VERSION ""

NS_ :

BS_:

BU_: RLPSU DPSU APSU PSB SHVU_RR vHS_B2 FCS EMCU SLB RCM CGW_CCU vDummy_HS_B ATS RLHV PFSU SGU ALBCU DSAU SWRC SHVU_FR RCS RRPSU BLTN_CAM SCM DLBCU OHCL RWPC RRHV WPC HOD ASAU

BO_ 1218 HU_USM_E_08: 8 CGW_CCU
 SG_ C_AVN_PTGHeightNValueSet : 13|3@1+ (1,0) [0|0] ""  Vector__XXX
 SG_ CF_AVN_SCCMLReset : 16|2@1+ (1,0) [0|0] ""  Vector__XXX
 SG_ C_TgltAwayCloseNValue : 18|2@1+ (1,0) [0|0] ""  Vector__XXX
 SG_ C_HAnBNValueSet : 20|2@1+ (1,0) [0|0] ""  Vector__XXX
 SG_ CF_AVN_RrSeatRemindNValueSet : 22|2@1+ (1,0) [0|0] ""  Vector__XXX
 SG_ CF_AVN_DSWNValueSet : 24|2@1+ (1,0) [0|0] ""  Vector__XXX
 SG_ CF_AVN_RRPSU_RLNValueSet : 26|3@1+ (1,0) [0|0] ""  APSU,RRPSU,RLPSU
 SG_ CF_AVN_APSUNValueSet : 29|3@1+ (1,0) [0|0] ""  APSU,ASAU
 SG_ CF_AVN_NCC_CameraNValueSet : 32|3@1+ (1,0) [0|0] ""  Vector__XXX
 SG_ CF_AVN_FCAJnctnNValueSet : 35|2@1+ (1,0) [0|0] ""  Vector__XXX
 SG_ CF_AVN_RRPSU_RRNValueSet : 37|3@1+ (1,0) [0|0] ""  APSU,RRPSU,RLPSU
 SG_ CF_AVN_HtBlcAstNValueSet : 40|4@1+ (1,0) [0|0] ""  APSU,SHVU_FR,DPSU
 SG_ CF_AVN_HtBlcDrvNValueSet : 44|4@1+ (1,0) [0|0] ""  APSU,SHVU_FR,DPSU
 SG_ CF_AVN_SCCModeNValueSet : 48|2@1+ (1,0) [0|0] ""  Vector__XXX
 SG_ CF_AVN_SCCMLChar1Set : 50|3@1+ (1,0) [0|0] ""  Vector__XXX
 SG_ CF_AVN_UIPNValueSet : 54|2@1+ (1,0) [0|0] ""  Vector__XXX
 SG_ CF_AVN_SCCMLChar2Set : 56|3@1+ (1,0) [0|0] ""  Vector__XXX
 SG_ CF_AVN_SCCMLChar3Set : 59|3@1+ (1,0) [0|0] ""  Vector__XXX
 SG_ CF_AVN_NmodeFCAoffNValue : 62|2@1+ (1,0) [0|0] ""  Vector__XXX
 SG_ CF_AVN_HDALCFuncNValueSet : 8|2@1+ (1,0) [0|0] ""  Vector__XXX

BO_ 2323816451 CCU_CCS_01_00ms_3: 8 CGW_CCU

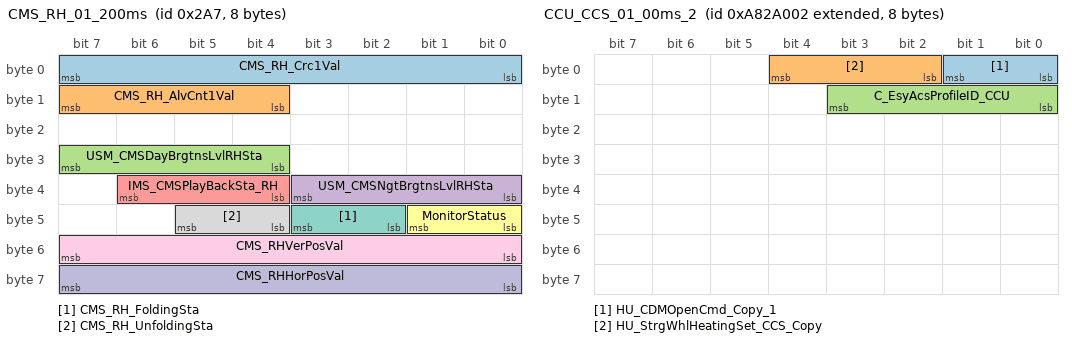
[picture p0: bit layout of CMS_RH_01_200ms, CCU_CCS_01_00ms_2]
BO_ 679 CMS_RH_01_200ms: 8 CGW_CCU
 SG_ CMS_RH_Crc1Val : 0|8@1+ (1,0) [0|0] ""  Vector__XXX
 SG_ CMS_RH_AlvCnt1Val : 12|4@1+ (1,0) [0|0] ""  Vector__XXX
 SG_ USM_CMSDayBrgtnsLvlRHSta : 28|4@1+ (1,0) [0|0] ""  Vector__XXX
 SG_ USM_CMSNgtBrgtnsLvlRHSta : 32|4@1+ (1,0) [0|0] ""  Vector__XXX
 SG_ IMS_CMSPlayBackSta_RH : 36|3@1+ (1,0) [0|0] ""  DPSU
 SG_ MonitorStatus : 40|2@1+ (1,0) [0|0] ""  Vector__XXX
 SG_ CMS_RH_FoldingSta : 42|2@1+ (1,0) [0|0] ""  Vector__XXX
 SG_ CMS_RH_UnfoldingSta : 44|2@1+ (1,0) [0|0] ""  Vector__XXX
 SG_ CMS_RHVerPosVal : 48|8@1+ (0.02,0) [0|0] "V"  Vector__XXX
 SG_ CMS_RHHorPosVal : 56|8@1+ (0.02,0) [0|0] "V"  Vector__XXX

BO_ 2323816450 CCU_CCS_01_00ms_2: 8 CGW_CCU
 SG_ HU_CDMOpenCmd_Copy_1 : 0|2@1+ (1,0) [0|0] ""  Vector__XXX
 SG_ HU_StrgWhlHeatingSet_CCS_Copy : 2|3@1+ (1,0) [0|0] ""  Vector__XXX
 SG_ C_EsyAcsProfileID_CCU : 8|4@1+ (1,0) [0|0] ""  DPSU

BO_ 678 AST_SEAT_01_00ms: 8 APSU
 SG_ Ast_AutoRlxWrngDis : 0|3@1+ (1,0) [0|0] ""  CGW_CCU
 SG_ APSM_IMSWngDis : 12|2@1+ (1,0) [0|0] ""  Vector__XXX

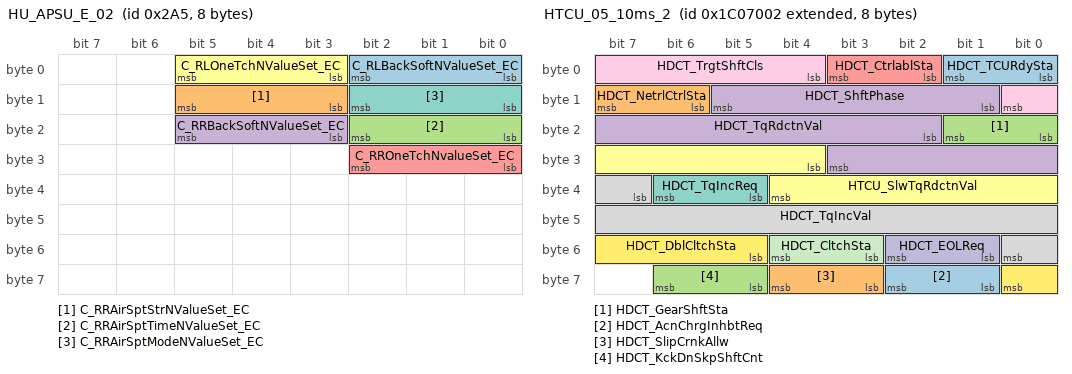
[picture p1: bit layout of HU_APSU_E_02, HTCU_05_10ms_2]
BO_ 677 HU_APSU_E_02: 8 CGW_CCU
 SG_ C_RLBackSoftNValueSet_EC : 0|3@1+ (1,0) [0|0] ""  RLPSU,ATS
 SG_ C_RRAirSptStrNValueSet_EC : 11|3@1+ (1,0) [0|0] ""  RRPSU,ATS
 SG_ C_RRAirSptTimeNValueSet_EC : 16|3@1+ (1,0) [0|0] ""  RRPSU,ATS
 SG_ C_RRBackSoftNValueSet_EC : 19|3@1+ (1,0) [0|0] ""  RRPSU,ATS
 SG_ C_RROneTchNvalueSet_EC : 24|3@1+ (1,0) [0|0] ""  RRPSU,ATS
 SG_ C_RLOneTchNValueSet_EC : 3|3@1+ (1,0) [0|0] ""  RRPSU,RLPSU,ATS
 SG_ C_RRAirSptModeNValueSet_EC : 8|3@1+ (1,0) [0|0] ""  RRPSU,ATS

BO_ 2323816449 CCU_CCS_01_00ms_1: 8 CGW_CCU
 SG_ C_CtrlDrLockRlyCCS_Copy_2 : 0|2@1+ (1,0) [0|0] ""  Vector__XXX
 SG_ C_TeleHeatingCmdIBOX_Copy_2 : 10|2@1+ (1,0) [0|0] ""  Vector__XXX
 SG_ C_TeleStrgWhlHeatingCmdIBOX_Copy_2 : 12|2@1+ (1,0) [0|0] ""  Vector__XXX
 SG_ C_TeleDefoggerHeatingCmdIBOX_Copy_2 : 14|2@1+ (1,0) [0|0] ""  Vector__XXX
 SG_ C_TeleDrvSeatOpCmdIBOX_Copy_2 : 16|4@1+ (1,0) [0|0] ""  SHVU_FR,DPSU
 SG_ C_CtrlDrUnlockRlyCCS_Copy_2 : 2|2@1+ (1,0) [0|0] ""  Vector__XXX
 SG_ C_TeleAstSeatOpCmdIBOX_Copy_2 : 20|4@1+ (1,0) [0|0] ""  APSU,SHVU_FR
 SG_ C_TeleRRSeatOpCmdIBOX_Copy_2 : 24|4@1+ (1,0) [0|0] ""  RRHV,SHVU_FR,SHVU_RR,RRPSU,RLPSU,ATS
 SG_ C_TeleRLSeatOpCmdIBOX_Copy_1 : 28|4@1+ (1,0) [0|0] ""  RLHV,SHVU_FR,SHVU_RR,RRPSU,RLPSU,ATS
 SG_ C_BlindCmdAVN_Copy_2 : 32|3@1+ (1,0) [0|0] ""  Vector__XXX
 SG_ C_GlassCmdAVN_Copy_2 : 35|3@1+ (1,0) [0|0] ""  Vector__XXX
 SG_ C_DrvWindowCmdAVN_Copy_2 : 38|4@1+ (1,0) [0|0] ""  Vector__XXX
 SG_ C_HazardFromCCS_Copy_2 : 4|2@1+ (1,0) [0|0] ""  Vector__XXX
 SG_ C_AstWindowCmdAVN_Copy_2 : 42|4@1+ (1,0) [0|0] ""  Vector__XXX
 SG_ C_RRWindowCmdAVN_Copy_2 : 46|4@1+ (1,0) [0|0] ""  Vector__XXX
 SG_ C_RLWindowCmdAVN_Copy_2 : 50|4@1+ (1,0) [0|0] ""  Vector__XXX
 SG_ TailCtrlReq_Copy : 54|2@1+ (1,0) [0|0] ""  Vector__XXX
 SG_ HazardCtrlReq_Copy : 56|2@1+ (1,0) [0|0] ""  Vector__XXX
 SG_ HU_DATC_AirCleaningSet_Copy_1 : 58|2@1+ (1,0) [0|0] ""  Vector__XXX
 SG_ C_PanicFromCCS_Copy_2 : 6|2@1+ (1,0) [0|0] ""  Vector__XXX
 SG_ C_TeleFrontHeatingCmdIBOX_Copy_1 : 60|2@1+ (1,0) [0|0] ""  Vector__XXX
 SG_ RAC_AirCleaningCtrlReq_Copy_1 : 62|2@1+ (1,0) [0|0] ""  Vector__XXX
 SG_ C_PreCrankReq_Copy : 8|2@1+ (1,0) [0|0] ""  Vector__XXX

BO_ 676 HU_APSU_E_01: 8 CGW_CCU
 SG_ C_DrAirSptNValueSet_EC : 0|2@1+ (1,0) [0|0] ""  DLBCU,DSAU
 SG_ C_DrCushSoftNValueSet_EC : 11|3@1+ (1,0) [0|0] ""  DPSU,DLBCU,DSAU
 SG_ C_AstAirSptNValueSet_EC : 14|2@1+ (1,0) [0|0] ""  ASAU,ALBCU
 SG_ C_DrBackSoftNValueSet_EC : 16|3@1+ (1,0) [0|0] ""  DPSU,DLBCU,DSAU
 SG_ C_AstAirSptModeNValueSet_EC : 19|3@1+ (1,0) [0|0] ""  ASAU,ALBCU
 SG_ C_DrAirSptModeNValueSet_EC : 2|3@1+ (1,0) [0|0] ""  DLBCU,DSAU
 SG_ C_RLAirSptNValueSet_EC : 22|2@1+ (1,0) [0|0] ""  RLPSU,ATS
 SG_ C_AstAirSptStrNValueSet_EC : 24|3@1+ (1,0) [0|0] ""  ASAU,ALBCU
 SG_ C_AstAirSptTimeNValueSet_EC : 27|3@1+ (1,0) [0|0] ""  ASAU,ALBCU
 SG_ C_RRAirSptNValueSet_EC : 30|2@1+ (1,0) [0|0] ""  RRPSU,ATS
 SG_ C_AstCushSoftNValueSet_EC : 32|3@1+ (1,0) [0|0] ""  ASAU
 SG_ C_AstBackSoftNValueSet_EC : 35|3@1+ (1,0) [0|0] ""  ASAU
 SG_ C_AstRlxNValueSet_EC : 40|3@1+ (1,0) [0|0] ""  APSU
 SG_ C_RLAirSptModeNValueSet_EC : 43|3@1+ (1,0) [0|0] ""  RLPSU,ATS
 SG_ C_DrAirSptStrNValueSet_EC : 5|3@1+ (1,0) [0|0] ""  DLBCU,DSAU
 SG_ C_RLAirSptStrNValueSet_EC : 56|3@1+ (1,0) [0|0] ""  RLPSU,ATS
 SG_ C_RLAirSptTimeNValueSet_EC : 59|3@1+ (1,0) [0|0] ""  RLPSU,ATS
 SG_ C_DrAirSptTimeNValueSet_EC : 8|3@1+ (1,0) [0|0] ""  DLBCU,DSAU

BO_ 675 HU_USM_E_11: 8 CGW_CCU
 SG_ Usm_RpmMUDSet : 1|2@1+ (1,0) [0|0] ""  Vector__XXX
 SG_ CF_AVN_HtBlcRLNValueSet : 11|4@1+ (1,0) [0|0] ""  SHVU_FR,SHVU_RR,RRPSU,RLPSU
 SG_ CF_AVN_BRAKE_PedalfeelNValueSet2 : 15|3@1+ (1,0) [0|0] ""  Vector__XXX
 SG_ CF_AVN_HtBlcRRNValueSet : 20|4@1+ (1,0) [0|0] ""  SHVU_FR,SHVU_RR,RRPSU,RLPSU
 SG_ LapTimer_AutoMeasure_Setting : 24|2@1+ (1,0) [0|0] ""  Vector__XXX
 SG_ LapTimer_TimeGap_Setting : 26|2@1+ (1,0) [0|0] ""  Vector__XXX
 SG_ Usm_RpmSANDSet : 3|2@1+ (1,0) [0|0] ""  Vector__XXX
 SG_ CF_AVN_RemoteWDWNValueSet : 30|2@1+ (1,0) [0|0] ""  Vector__XXX
 SG_ USM_TowWeight_Set : 32|4@1+ (1,0) [0|0] ""  Vector__XXX
 SG_ CF_AVN_PABArbgNValueSet : 36|2@1+ (1,0) [0|0] ""  Vector__XXX
 SG_ CF_AVN_SportHUD2 : 38|2@1+ (1,0) [0|0] ""  Vector__XXX
 SG_ C_SLB_SmartCtrl_Set_Nvalue : 44|4@1+ (1,0) [0|0] ""  SLB,DLBCU
 SG_ CF_AVN_ArHudLeftRightSet : 48|4@1+ (1,0) [0|0] ""  Vector__XXX
 SG_ HU_CustomNewMenuSet : 5|4@1+ (1,0) [0|0] ""  Vector__XXX
 SG_ CF_AVN_ArHudViewSet : 52|5@1+ (1,0) [0|0] ""  Vector__XXX
 SG_ USM_RpmComfortRearSet : 57|2@1+ (1,0) [0|0] ""  Vector__XXX
 SG_ Usm_RpmMyDriveModeSet : 59|2@1+ (1,0) [0|0] ""  Vector__XXX
 SG_ CF_AVN_PCA_RrEquipNvalueSet : 9|2@1+ (1,0) [0|0] ""  Vector__XXX

BO_ 1227 PSM_01_00ms: 8 DPSU
 SG_ DrvIMS_MemoryP1Req : 0|2@1+ (1,0) [0|0] ""  CGW_CCU
 SG_ DrvIMS_PlyBckP2Req : 10|2@1+ (1,0) [0|0] ""  CGW_CCU
 SG_ DrvIMS_PlyBckP3Req : 12|2@1+ (1,0) [0|0] ""  CGW_CCU
 SG_ DrvIMS_PlyBckStpReq : 14|2@1+ (1,0) [0|0] ""  CGW_CCU
 SG_ SmrtIMS_PlyBckReq : 16|12@1+ (1,0) [0|0] ""  CGW_CCU
 SG_ DrvIMS_MemoryP2Req : 2|2@1+ (1,0) [0|0] ""  CGW_CCU
 SG_ PSM_IMSReq : 28|3@1+ (1,0) [0|0] ""  CGW_CCU
 SG_ SmrtIMS_ImgDBVal : 32|5@1+ (1,0) [0|0] ""  CGW_CCU
 SG_ SmrtIMS_PlyBckStpReq : 37|2@1+ (1,0) [0|0] ""  CGW_CCU
 SG_ DrvIMS_MemoryP3Req : 4|2@1+ (1,0) [0|0] ""  CGW_CCU
 SG_ SmrtIMS_EnterSwSta : 40|2@1+ (1,0) [0|0] ""  CGW_CCU
 SG_ DrvIMS_BzrReq : 42|2@1+ (1,0) [0|0] ""  CGW_CCU
 SG_ DrvIMS_ErrConWmgDis : 46|2@1+ (1,0) [0|0] ""  CGW_CCU
 SG_ PSM_DrvRlxReturn_Req : 48|3@1+ (1,0) [0|0] ""  CGW_CCU
 SG_ Drv_AutoRlxWrngDis : 51|3@1+ (1,0) [0|0] ""  CGW_CCU
 SG_ DrvIMS_MemorySetEnaSta : 6|2@1+ (1,0) [0|0] ""  CGW_CCU
 SG_ DrvIMS_PlyBckP1Req : 8|2@1+ (1,0) [0|0] ""  CGW_CCU

BO_ 2323816452 CCU_CCS_01_00ms_4: 8 CGW_CCU

BO_ 2176872450 HTCU_05_10ms_2: 8 CGW_CCU
 SG_ HDCT_TCURdySta : 0|2@1+ (1,0) [0|0] ""  Vector__XXX
 SG_ HDCT_NetrlCtrlSta : 14|2@1+ (1,0) [0|0] ""  Vector__XXX
 SG_ HDCT_GearShftSta : 16|2@1+ (1,0) [0|0] ""  Vector__XXX
 SG_ HDCT_TqRdctnVal : 18|10@1+ (0.390625,-200) [0|0] "%"  Vector__XXX
 SG_ HDCT_CtrlablSta : 2|2@1+ (1,0) [0|0] ""  Vector__XXX
 SG_ HTCU_SlwTqRdctnVal : 28|9@1+ (0.390625,0) [0|0] "%"  Vector__XXX
 SG_ HDCT_TqIncReq : 37|2@1+ (1,0) [0|0] ""  Vector__XXX
 SG_ HDCT_TqIncVal : 39|10@1+ (0.390625,-200) [0|0] "%"  Vector__XXX
 SG_ HDCT_TrgtShftCls : 4|5@1+ (1,0) [0|0] "flag"  Vector__XXX
 SG_ HDCT_EOLReq : 49|2@1+ (1,0) [0|0] ""  Vector__XXX
 SG_ HDCT_CltchSta : 51|2@1+ (1,0) [0|0] ""  Vector__XXX
 SG_ HDCT_DblCltchSta : 53|4@1+ (1,0) [0|0] ""  Vector__XXX
 SG_ HDCT_AcnChrgInhbtReq : 57|2@1+ (1,0) [0|0] ""  Vector__XXX
 SG_ HDCT_SlipCrnkAllw : 59|2@1+ (1,0) [0|0] ""  Vector__XXX
 SG_ HDCT_KckDnSkpShftCnt : 61|2@1+ (1,0) [0|0] ""  Vector__XXX
 SG_ HDCT_ShftPhase : 9|5@1+ (1,0) [0|0] ""  Vector__XXX

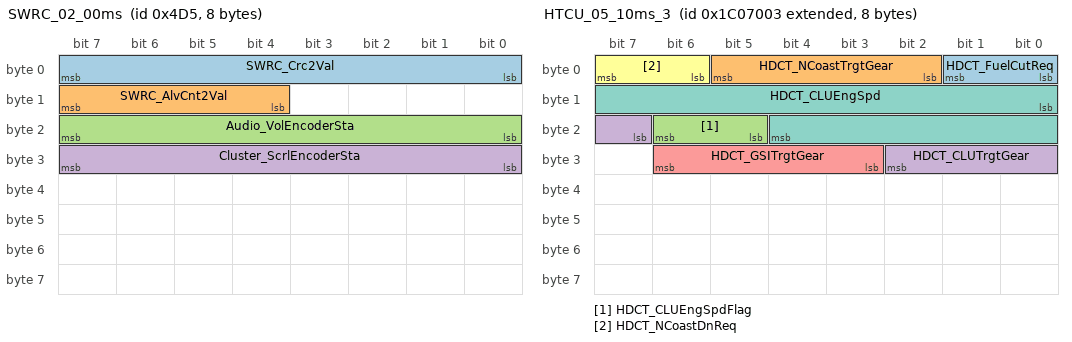
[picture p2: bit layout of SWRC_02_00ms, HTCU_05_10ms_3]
BO_ 1237 SWRC_02_00ms: 8 SWRC
 SG_ SWRC_Crc2Val : 0|8@1+ (1,0) [0|0] ""  Vector__XXX
 SG_ SWRC_AlvCnt2Val : 12|4@1+ (1,0) [0|0] ""  Vector__XXX
 SG_ Audio_VolEncoderSta : 16|8@1+ (1,0) [0|0] ""  CGW_CCU
 SG_ Cluster_ScrlEncoderSta : 24|8@1+ (1,0) [0|0] ""  CGW_CCU

BO_ 2176872451 HTCU_05_10ms_3: 8 CGW_CCU
 SG_ HDCT_FuelCutReq : 0|2@1+ (1,0) [0|0] ""  Vector__XXX
 SG_ HDCT_NCoastTrgtGear : 2|4@1+ (1,0) [0|0] ""  Vector__XXX
 SG_ HDCT_CLUEngSpdFlag : 21|2@1+ (1,0) [0|0] ""  Vector__XXX
 SG_ HDCT_CLUTrgtGear : 23|4@1+ (1,0) [0|0] ""  Vector__XXX
 SG_ HDCT_GSITrgtGear : 27|4@1+ (1,0) [0|0] ""  Vector__XXX
 SG_ HDCT_NCoastDnReq : 6|2@1+ (1,0) [0|0] ""  Vector__XXX
 SG_ HDCT_CLUEngSpd : 8|13@1+ (0.9766,0) [0|0] ""  Vector__XXX

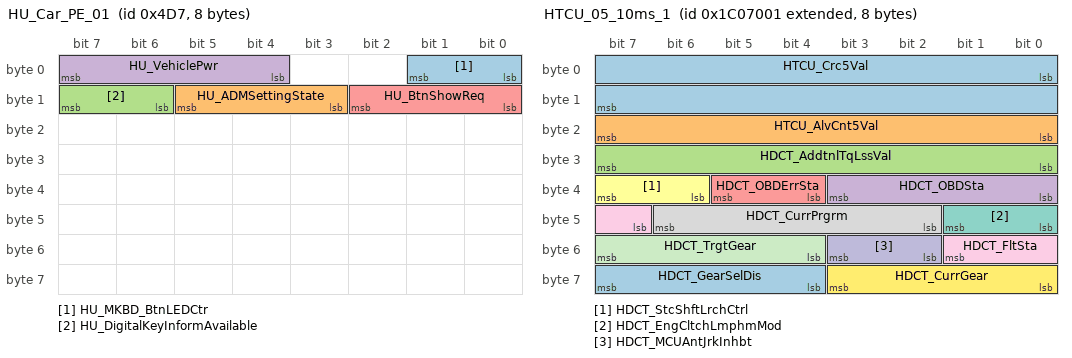
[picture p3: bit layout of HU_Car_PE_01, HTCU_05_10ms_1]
BO_ 1239 HU_Car_PE_01: 8 CGW_CCU
 SG_ HU_MKBD_BtnLEDCtr : 0|2@1+ (1,0) [0|0] ""  Vector__XXX
 SG_ HU_ADMSettingState : 11|3@1+ (1,0) [0|0] ""  Vector__XXX
 SG_ HU_DigitalKeyInformAvailable : 14|2@1+ (1,0) [0|0] ""  Vector__XXX
 SG_ HU_VehiclePwr : 4|4@1+ (1,0) [0|0] ""  SGU
 SG_ HU_BtnShowReq : 8|3@1+ (1,0) [0|0] ""  SWRC

BO_ 2176872449 HTCU_05_10ms_1: 8 CGW_CCU
 SG_ HTCU_Crc5Val : 0|16@1+ (1,0) [0|0] ""  Vector__XXX
 SG_ HTCU_AlvCnt5Val : 16|8@1+ (1,0) [0|0] ""  Vector__XXX
 SG_ HDCT_AddtnlTqLssVal : 24|8@1+ (0.390625,0) [0|0] "%"  Vector__XXX
 SG_ HDCT_OBDSta : 32|4@1+ (1,0) [0|0] ""  Vector__XXX
 SG_ HDCT_OBDErrSta : 36|2@1+ (1,0) [0|0] ""  Vector__XXX
 SG_ HDCT_StcShftLrchCtrl : 38|2@1+ (1,0) [0|0] ""  Vector__XXX
 SG_ HDCT_EngCltchLmphmMod : 40|2@1+ (1,0) [0|0] ""  Vector__XXX
 SG_ HDCT_CurrPrgrm : 42|5@1+ (1,0) [0|0] ""  Vector__XXX
 SG_ HDCT_FltSta : 47|3@1+ (1,0) [0|0] ""  Vector__XXX
 SG_ HDCT_MCUAntJrkInhbt : 50|2@1+ (1,0) [0|0] ""  Vector__XXX
 SG_ HDCT_TrgtGear : 52|4@1+ (1,0) [0|0] ""  Vector__XXX
 SG_ HDCT_CurrGear : 56|4@1+ (1,0) [0|0] ""  Vector__XXX
 SG_ HDCT_GearSelDis : 60|4@1+ (1,0) [0|0] ""  BLTN_CAM

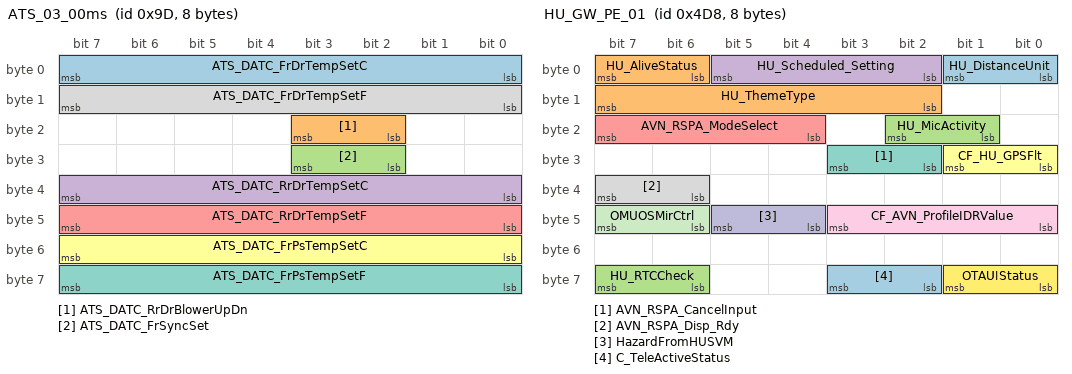
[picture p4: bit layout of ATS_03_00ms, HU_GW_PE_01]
BO_ 157 ATS_03_00ms: 8 ATS
 SG_ ATS_DATC_FrDrTempSetC : 0|8@1+ (0.5,14) [0|0] ""  CGW_CCU
 SG_ ATS_DATC_RrDrBlowerUpDn : 18|2@1+ (1,0) [0|0] ""  CGW_CCU
 SG_ ATS_DATC_FrSyncSet : 26|2@1+ (1,0) [0|0] ""  CGW_CCU
 SG_ ATS_DATC_RrDrTempSetC : 32|8@1+ (0.5,14) [0|0] ""  CGW_CCU
 SG_ ATS_DATC_RrDrTempSetF : 40|8@1+ (1,56) [0|0] ""  CGW_CCU
 SG_ ATS_DATC_FrPsTempSetC : 48|8@1+ (0.5,14) [0|0] ""  CGW_CCU
 SG_ ATS_DATC_FrPsTempSetF : 56|8@1+ (1,56) [0|0] ""  CGW_CCU
 SG_ ATS_DATC_FrDrTempSetF : 8|8@1+ (1,56) [0|0] ""  CGW_CCU

BO_ 2176872452 HTCU_05_10ms_4: 8 CGW_CCU

BO_ 158 ATS_02_00ms: 8 ATS
 SG_ ATS_DATC_FrDrBlowerSet : 12|4@1+ (1,0) [0|0] ""  CGW_CCU
 SG_ ATS_DATC_RrDrTempUpDn : 2|2@1+ (1,0) [0|0] ""  CGW_CCU
 SG_ ATS_DATC_RrDrBlowerSet : 20|4@1+ (1,0) [0|0] ""  CGW_CCU
 SG_ ATS_DATC_RrDrModeSet : 24|4@1+ (1,0) [0|0] ""  CGW_CCU
 SG_ ATS_DATC_FrDrModeSet : 28|4@1+ (1,0) [0|0] ""  CGW_CCU
 SG_ ATS_DATC_RrOnOffSet : 32|2@1+ (1,0) [0|0] ""  Vector__XXX
 SG_ ATS_DATC_IntakeSet : 34|2@1+ (1,0) [0|0] ""  CGW_CCU
 SG_ ATS_DATC_OffReq : 36|2@1+ (1,0) [0|0] ""  Vector__XXX
 SG_ ATS_DATC_FrDrAutoSet : 38|2@1+ (1,0) [0|0] ""  CGW_CCU
 SG_ ATS_DATC_FrPsTempUpDn : 4|2@1+ (1,0) [0|0] ""  CGW_CCU
 SG_ ATS_DATC_FrDefog : 42|2@1+ (1,0) [0|0] ""  CGW_CCU
 SG_ ATS_DATC_RrSyncSet : 44|2@1+ (1,0) [0|0] ""  CGW_CCU
 SG_ ATS_DATC_AcSet : 46|2@1+ (1,0) [0|0] ""  CGW_CCU
 SG_ ATS_DATC_AirCleaningSet : 56|2@1+ (1,0) [0|0] ""  CGW_CCU
 SG_ ATS_DATC_FrDrBlowerUpDn : 58|2@1+ (1,0) [0|0] ""  CGW_CCU
 SG_ ATS_DATC_FrDrTempUpDn : 6|2@1+ (1,0) [0|0] ""  CGW_CCU
 SG_ ATS_DATC_RrDrAutoSet : 62|2@1+ (1,0) [0|0] ""  CGW_CCU

BO_ 694 ASAU_02_00ms: 8 APSU
 SG_ ASAU_NotFootMsgOperStaWarn : 0|2@1+ (1,0) [0|0] ""  Vector__XXX

BO_ 1240 HU_GW_PE_01: 8 CGW_CCU
 SG_ HU_DistanceUnit : 0|2@1+ (1,0) [0|0] ""  Vector__XXX
 SG_ HU_ThemeType : 10|6@1+ (1,0) [0|0] ""  ATS,BLTN_CAM
 SG_ HU_MicActivity : 17|2@1+ (1,0) [0|0] ""  Vector__XXX
 SG_ HU_Scheduled_Setting : 2|4@1+ (1,0) [0|0] ""  Vector__XXX
 SG_ AVN_RSPA_ModeSelect : 20|4@1+ (1,0) [0|0] ""  Vector__XXX
 SG_ CF_HU_GPSFlt : 24|2@1+ (1,0) [0|0] ""  Vector__XXX
 SG_ AVN_RSPA_CancelInput : 26|2@1+ (1,0) [0|3] ""  Vector__XXX
 SG_ AVN_RSPA_Disp_Rdy : 38|2@1+ (1,0) [0|0] ""  Vector__XXX
 SG_ CF_AVN_ProfileIDRValue : 40|4@1+ (1,0) [0|0] ""  WPC,RWPC,DPSU,BLTN_CAM,SGU
 SG_ HazardFromHUSVM : 44|2@1+ (1,0) [0|0] ""  Vector__XXX
 SG_ OMUOSMirCtrl : 46|2@1+ (1,0) [0|0] ""  Vector__XXX
 SG_ OTAUIStatus : 56|2@1+ (1,0) [0|0] ""  Vector__XXX
 SG_ C_TeleActiveStatus : 58|2@1+ (1,0) [0|0] ""  Vector__XXX
 SG_ HU_AliveStatus : 6|2@1+ (1,0) [0|0] ""  Vector__XXX
 SG_ HU_RTCCheck : 62|2@1+ (1,0) [0|0] ""  APSU

BO_ 2424580353 DATC_12_200ms_1: 8 CGW_CCU
 SG_ DATC_Crc12Val : 0|16@1+ (1,0) [0|0] ""  Vector__XXX
 SG_ DATC_AlvCnt12Val : 16|8@1+ (1,0) [0|0] ""  Vector__XXX
 SG_ DATC_StrWhlHtrSwReq : 24|2@1+ (1,0) [0|0] ""  Vector__XXX
 SG_ DATC_FRStHtrSwReq : 26|2@1+ (1,0) [0|0] ""  APSU,SHVU_FR,SHVU_RR,DPSU
 SG_ DATC_FRStVentSwReq : 28|2@1+ (1,0) [0|0] ""  APSU,SHVU_FR,SHVU_RR,DPSU
 SG_ DATC_RrDefSw : 30|2@1+ (1,0) [0|0] ""  Vector__XXX
 SG_ DATC_FLStOpReq : 32|4@1+ (1,0) [0|0] ""  APSU,SHVU_FR,SHVU_RR,DPSU
 SG_ DATC_FRStOpReq : 36|4@1+ (1,0) [0|0] ""  APSU,SHVU_FR,SHVU_RR
 SG_ DATC_FLStHtrSwReq : 40|2@1+ (1,0) [0|0] ""  APSU,SHVU_FR,SHVU_RR,DPSU
 SG_ DATC_FLStVentSwReq : 42|2@1+ (1,0) [0|0] ""  APSU,SHVU_FR,SHVU_RR,DPSU
 SG_ DATC_FLStTmblrSwReq : 44|2@1+ (1,0) [0|0] ""  APSU,SHVU_FR
 SG_ DATC_FRStTmblrSwReq : 46|2@1+ (1,0) [0|0] ""  APSU,SHVU_FR
 SG_ DATC_RRStHtrSwReq : 48|2@1+ (1,0) [0|0] ""  RRHV,SHVU_FR,SHVU_RR,RRPSU,RLPSU
 SG_ DATC_RRStVentSwReq : 50|2@1+ (1,0) [0|0] ""  RRHV,SHVU_FR,SHVU_RR,RRPSU,RLPSU
 SG_ DATC_RLStHtrSwReq : 52|2@1+ (1,0) [0|0] ""  RLHV,SHVU_FR,SHVU_RR,RRPSU,RLPSU
 SG_ DATC_RLStVentSwReq : 54|2@1+ (1,0) [0|0] ""  RLHV,SHVU_FR,SHVU_RR,RRPSU,RLPSU
 SG_ DATC_FRWndShldHtSW : 56|2@1+ (1,0) [0|0] ""  Vector__XXX
 SG_ DATC_WhistlelNoise : 58|2@1+ (1,0) [0|0] ""  Vector__XXX
 SG_ DATC_WdwClsReq : 60|2@1+ (1,0) [0|0] ""  Vector__XXX
 SG_ DATC_RRSyncDis : 62|2@1+ (1,0) [0|0] ""  ATS

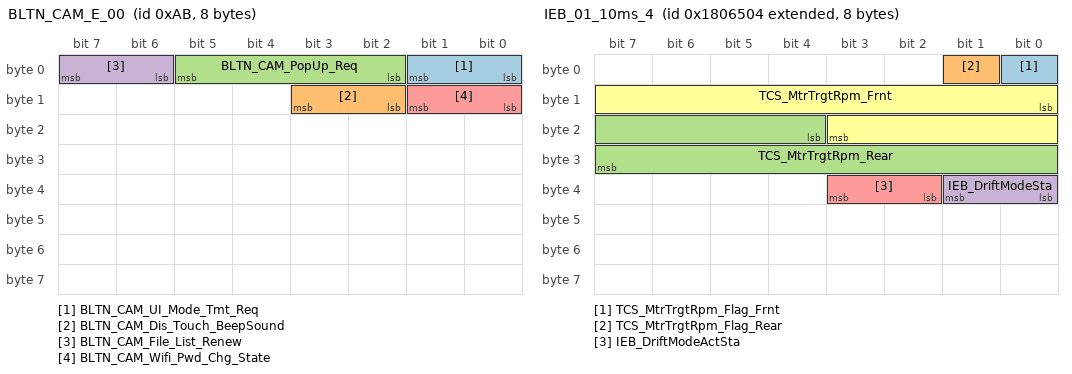
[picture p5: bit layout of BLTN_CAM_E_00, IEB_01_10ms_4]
BO_ 171 BLTN_CAM_E_00: 8 BLTN_CAM
 SG_ BLTN_CAM_UI_Mode_Tmt_Req : 0|2@1+ (1,0) [0|0] ""  CGW_CCU
 SG_ BLTN_CAM_Dis_Touch_BeepSound : 10|2@1+ (1,0) [0|0] ""  Vector__XXX
 SG_ BLTN_CAM_PopUp_Req : 2|4@1+ (1,0) [0|0] ""  CGW_CCU
 SG_ BLTN_CAM_File_List_Renew : 6|2@1+ (1,0) [0|0] ""  CGW_CCU
 SG_ BLTN_CAM_Wifi_Pwd_Chg_State : 8|2@1+ (1,0) [0|0] ""  CGW_CCU

BO_ 2172675332 IEB_01_10ms_4: 8 CGW_CCU
 SG_ TCS_MtrTrgtRpm_Flag_Frnt : 0|1@1+ (1,0) [0|0] ""  Vector__XXX
 SG_ TCS_MtrTrgtRpm_Flag_Rear : 1|1@1+ (1,0) [0|0] ""  Vector__XXX
 SG_ TCS_MtrTrgtRpm_Rear : 20|12@1+ (8,0) [0|0] "rpm"  Vector__XXX
 SG_ IEB_DriftModeSta : 32|2@1+ (1,0) [0|0] ""  Vector__XXX
 SG_ IEB_DriftModeActSta : 34|2@1+ (1,0) [0|0] ""  Vector__XXX
 SG_ TCS_MtrTrgtRpm_Frnt : 8|12@1+ (8,0) [0|0] "rpm"  Vector__XXX

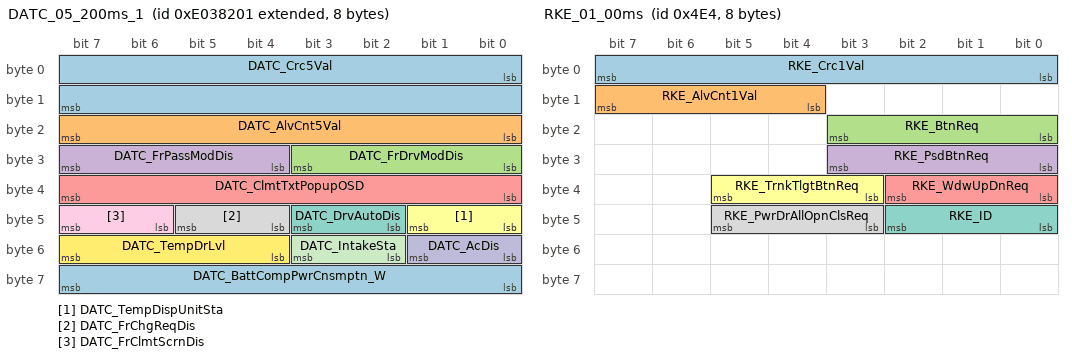
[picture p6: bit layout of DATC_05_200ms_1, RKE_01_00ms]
BO_ 2382594561 DATC_05_200ms_1: 8 CGW_CCU
 SG_ DATC_Crc5Val : 0|16@1+ (1,0) [0|0] ""  Vector__XXX
 SG_ DATC_AlvCnt5Val : 16|8@1+ (1,0) [0|0] ""  Vector__XXX
 SG_ DATC_FrDrvModDis : 24|4@1+ (1,0) [0|0] ""  ATS
 SG_ DATC_FrPassModDis : 28|4@1+ (1,0) [0|0] ""  ATS
 SG_ DATC_ClmtTxtPopupOSD : 32|8@1+ (1,0) [0|0] ""  ATS
 SG_ DATC_TempDispUnitSta : 40|2@1+ (1,0) [0|0] ""  ATS
 SG_ DATC_DrvAutoDis : 42|2@1+ (1,0) [0|0] ""  ATS
 SG_ DATC_FrChgReqDis : 44|2@1+ (1,0) [0|0] ""  Vector__XXX
 SG_ DATC_FrClmtScrnDis : 46|2@1+ (1,0) [0|0] ""  ATS
 SG_ DATC_AcDis : 48|2@1+ (1,0) [0|0] ""  ATS
 SG_ DATC_IntakeSta : 50|2@1+ (1,0) [0|0] ""  Vector__XXX
 SG_ DATC_TempDrLvl : 52|4@1+ (1,0) [0|0] ""  Vector__XXX
 SG_ DATC_BattCompPwrCnsmptn_W : 56|8@1+ (40,0) [0|0] "W"  Vector__XXX

BO_ 1252 RKE_01_00ms: 8 CGW_CCU
 SG_ RKE_Crc1Val : 0|8@1+ (1,0) [0|0] ""  Vector__XXX
 SG_ RKE_AlvCnt1Val : 12|4@1+ (1,0) [0|0] ""  Vector__XXX
 SG_ RKE_BtnReq : 16|4@1+ (1,0) [0|0] ""  ATS
 SG_ RKE_PsdBtnReq : 24|4@1+ (1,0) [0|0] ""  Vector__XXX
 SG_ RKE_WdwUpDnReq : 32|3@1+ (1,0) [0|0] ""  RCM
 SG_ RKE_TrnkTlgtBtnReq : 35|3@1+ (1,0) [0|0] ""  Vector__XXX
 SG_ RKE_ID : 40|3@1+ (1,0) [0|0] ""  Vector__XXX
 SG_ RKE_PwrDrAllOpnClsReq : 43|3@1+ (1,0) [0|0] ""  Vector__XXX

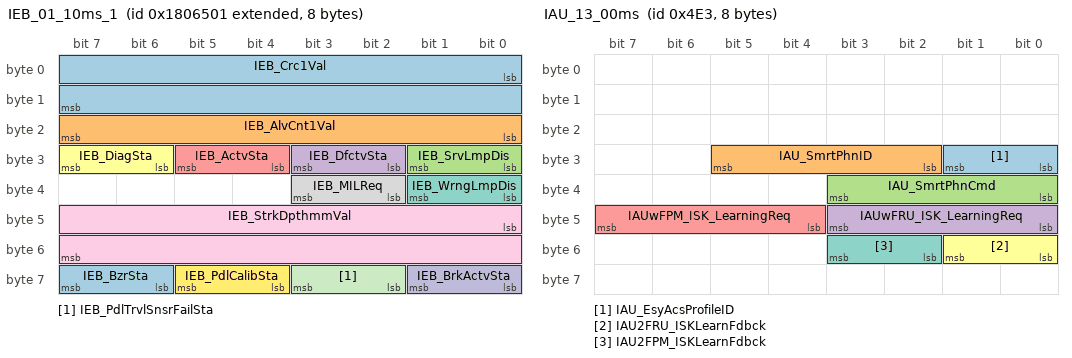
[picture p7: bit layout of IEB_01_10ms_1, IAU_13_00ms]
BO_ 2172675329 IEB_01_10ms_1: 8 CGW_CCU
 SG_ IEB_Crc1Val : 0|16@1+ (1,0) [0|0] ""  Vector__XXX
 SG_ IEB_AlvCnt1Val : 16|8@1+ (1,0) [0|0] ""  Vector__XXX
 SG_ IEB_SrvLmpDis : 24|2@1+ (1,0) [0|0] ""  Vector__XXX
 SG_ IEB_DfctvSta : 26|2@1+ (1,0) [0|0] ""  Vector__XXX
 SG_ IEB_ActvSta : 28|2@1+ (1,0) [0|0] ""  Vector__XXX
 SG_ IEB_DiagSta : 30|2@1+ (1,0) [0|0] ""  Vector__XXX
 SG_ IEB_WrngLmpDis : 32|2@1+ (1,0) [0|0] ""  Vector__XXX
 SG_ IEB_MILReq : 34|2@1+ (1,0) [0|0] ""  Vector__XXX
 SG_ IEB_StrkDpthmmVal : 40|16@1- (0.1,0) [0|0] "mm"  Vector__XXX
 SG_ IEB_BrkActvSta : 56|2@1+ (1,0) [0|0] ""  BLTN_CAM
 SG_ IEB_PdlTrvlSnsrFailSta : 58|2@1+ (1,0) [0|0] ""  Vector__XXX
 SG_ IEB_PdlCalibSta : 60|2@1+ (1,0) [0|0] ""  Vector__XXX
 SG_ IEB_BzrSta : 62|2@1+ (1,0) [0|0] ""  Vector__XXX

BO_ 1251 IAU_13_00ms: 8 CGW_CCU
 SG_ IAU_EsyAcsProfileID : 24|2@1+ (1,0) [0|0] ""  DPSU
 SG_ IAU_SmrtPhnID : 26|4@1+ (1,0) [0|0] ""  Vector__XXX
 SG_ IAU_SmrtPhnCmd : 32|4@1+ (1,0) [0|0] ""  Vector__XXX
 SG_ IAUwFRU_ISK_LearningReq : 40|4@1+ (1,0) [0|0] ""  Vector__XXX
 SG_ IAUwFPM_ISK_LearningReq : 44|4@1+ (1,0) [0|0] ""  Vector__XXX
 SG_ IAU2FRU_ISKLearnFdbck : 48|2@1+ (1,0) [0|0] ""  Vector__XXX
 SG_ IAU2FPM_ISKLearnFdbck : 50|2@1+ (1,0) [0|0] ""  Vector__XXX

BO_TX_BU_ 694 : APSU,ASAU;
CM_ BO_ 694 "[EC] On Event and On Change";
CM_ SG_ 694 ASAU_NotFootMsgOperStaWarn "Passenger Foot Massage Operation Disable Mode";
CM_ BO_ 678 "[EC] On Event and On Change";
CM_ SG_ 678 Ast_AutoRlxWrngDis "Assist seat auto relax warning information for AVN Display";
CM_ SG_ 678 APSM_IMSWngDis "Ast IMS information";
CM_ BO_ 158 "[EC] On Event and On Change";
CM_ SG_ 158 ATS_DATC_FrDrBlowerSet "Front Driver side Blower Set";
CM_ SG_ 158 ATS_DATC_RrDrTempUpDn "Rear Driver side Temp Up Down";
CM_ SG_ 158 ATS_DATC_RrDrBlowerSet "Rear Driver side Blower Up Down";
CM_ SG_ 158 ATS_DATC_RrDrModeSet "Rear Driver side Mode Set";
CM_ SG_ 158 ATS_DATC_FrDrModeSet "Front Driver side Mode Set";
CM_ SG_ 158 ATS_DATC_RrOnOffSet "Rear Climate On/Off Set";
CM_ SG_ 158 ATS_DATC_IntakeSet "Intake Set";
CM_ SG_ 158 ATS_DATC_OffReq "Front Climate Off Set";
CM_ SG_ 158 ATS_DATC_FrDrAutoSet "Front Driver side Auto Set";
CM_ SG_ 158 ATS_DATC_FrPsTempUpDn "Front Passenger side Temp Up Down";
CM_ SG_ 158 ATS_DATC_FrDefog "Front Defog set";
CM_ SG_ 158 ATS_DATC_RrSyncSet "Rear Sync Set";
CM_ SG_ 158 ATS_DATC_AcSet "Ac Set";
CM_ SG_ 158 ATS_DATC_AirCleaningSet "AirCleaning Set";
CM_ SG_ 158 ATS_DATC_FrDrBlowerUpDn "Front Driver Blower Up Down";
CM_ SG_ 158 ATS_DATC_FrDrTempUpDn "Front Driver side Temp Up Down";
CM_ SG_ 158 ATS_DATC_RrDrAutoSet "Rear Driver side Auto Set";
CM_ BO_ 157 "[EC] On Event and On Change";
CM_ SG_ 157 ATS_DATC_FrDrTempSetC "Front Driver side Temp Set (Celsius)";
CM_ SG_ 157 ATS_DATC_RrDrBlowerUpDn "Rear Driver side Blower Up Down";
CM_ SG_ 157 ATS_DATC_FrSyncSet "Front Sync Set";
CM_ SG_ 157 ATS_DATC_RrDrTempSetC "Rear Driver side Temp Set (Celsius)";
CM_ SG_ 157 ATS_DATC_RrDrTempSetF "Rear Driver side Temp Set (Fahrenheit)";
CM_ SG_ 157 ATS_DATC_FrPsTempSetC "Front Passenger side Temp Set (Celsius)";
CM_ SG_ 157 ATS_DATC_FrPsTempSetF "Front Passenger side Temp Set (Fahrenheit)";
CM_ SG_ 157 ATS_DATC_FrDrTempSetF "Front Driver side Temp Set (Fahrenheit)";
CM_ BO_ 171 "[EC] On Event and On Change";
CM_ SG_ 171 BLTN_CAM_UI_Mode_Tmt_Req "Built-in Cam UI Mode terminate request.";
CM_ SG_ 171 BLTN_CAM_Dis_Touch_BeepSound "Display Touch Beep Sound of valid space touch.";
CM_ SG_ 171 BLTN_CAM_PopUp_Req "Built-in Cam Operating and SD Card related Popup Request on HU Display.";
CM_ SG_ 171 BLTN_CAM_File_List_Renew "The Storage information is renewed inform to HU.";
CM_ SG_ 171 BLTN_CAM_Wifi_Pwd_Chg_State "The Response, when HU change Wifi Passowrd via SOME/IP";
CM_ BO_ 2323816449 "[EC] On Event and On Change";
CM_ SG_ 2323816449 C_CtrlDrLockRlyCCS_Copy_2 "Command for Remote Door Lock";
CM_ SG_ 2323816449 C_TeleHeatingCmdIBOX_Copy_2 "'Command for Remote Heating

(Steering Wheel, Rear Window, Side Mirror)";
CM_ SG_ 2323816449 C_TeleStrgWhlHeatingCmdIBOX_Copy_2 "'Command for Remote Heating
(Steering Wheel)";
CM_ SG_ 2323816449 C_TeleDefoggerHeatingCmdIBOX_Copy_2 "'Command for Remote Heating
(Rear Window, Side Mirror)";
CM_ SG_ 2323816449 C_TeleDrvSeatOpCmdIBOX_Copy_2 "Command for Remote Seat Heat/Vent control (Driver)";
CM_ SG_ 2323816449 C_CtrlDrUnlockRlyCCS_Copy_2 "Command for Remote Door UnLock";
CM_ SG_ 2323816449 C_TeleAstSeatOpCmdIBOX_Copy_2 "Command for Remote Seat Heat/Vent control (Passenger)";
CM_ SG_ 2323816449 C_TeleRRSeatOpCmdIBOX_Copy_2 "Command for Remote Seat Heat/Vent control (Rear Right)";
CM_ SG_ 2323816449 C_TeleRLSeatOpCmdIBOX_Copy_1 "Command for Remote Seat Heat/Vent control (Rear Left)";
CM_ SG_ 2323816449 C_BlindCmdAVN_Copy_2 "This signal indicates Sunroof Blind Open/Close Command";
CM_ SG_ 2323816449 C_GlassCmdAVN_Copy_2 "This signal indicates Sunroof Glass Open/Close Command";
CM_ SG_ 2323816449 C_DrvWindowCmdAVN_Copy_2 "This signal indicates DRV Window Open/Close Command";
CM_ SG_ 2323816449 C_HazardFromCCS_Copy_2 "Command for Remote Hazard";
CM_ SG_ 2323816449 C_AstWindowCmdAVN_Copy_2 "This signal indicates AST Window Open/Close Command";
CM_ SG_ 2323816449 C_RRWindowCmdAVN_Copy_2 "This signal indicates RR Window Open/Close Command";
CM_ SG_ 2323816449 C_RLWindowCmdAVN_Copy_2 "This signal indicates RL Window Open/Close Command";
CM_ SG_ 2323816449 TailCtrlReq_Copy "This signal is for cotroling Tail lamp.";
CM_ SG_ 2323816449 HazardCtrlReq_Copy "This signal is request for controling Hazard lamp.";
CM_ SG_ 2323816449 HU_DATC_AirCleaningSet_Copy_1 "Air Cleaning System set";
CM_ SG_ 2323816449 C_PanicFromCCS_Copy_2 "Command for Remote Panic (Only for USA)";
CM_ SG_ 2323816449 C_TeleFrontHeatingCmdIBOX_Copy_1 "Command for Remote Heating (Front Window)";
CM_ SG_ 2323816449 RAC_AirCleaningCtrlReq_Copy_1 "RAC_Air Cleaning Control Request";
CM_ SG_ 2323816449 C_PreCrankReq_Copy "Command for B-CAN wake up singal (Need to send this signal before other remote commands)";
CM_ BO_ 2323816450 "[EC] On Event and On Change";
CM_ SG_ 2323816450 HU_CDMOpenCmd_Copy_1 "Command for CDM open/close";
CM_ SG_ 2323816450 C_EsyAcsProfileID_CCU "This signal indicates the current detected profile ID by smartphone APP.
(The drv seat move to the easy access position of the detected profile ID when receive the signal)";
CM_ BO_ 2323816451 "[EC] On Event and On Change";
CM_ BO_ 2323816452 "[EC] On Event and On Change";
CM_ BO_ 679 "[PE] Periodic and On Event";
CM_ SG_ 679 CMS_RH_Crc1Val "CMS_RH_CyclicRedundancyCheck1Value";
CM_ SG_ 679 CMS_RH_AlvCnt1Val "CMS_RH_AliveCounter1Value";
CM_ SG_ 679 CMS_RHVerPosVal "RH Outside Mirror Vertical Position sensor value";
CM_ SG_ 679 CMS_RHHorPosVal "RH Outside Mirror Horizontal Position sensor value";
CM_ BO_ 2382594561 "[PE] Periodic and On Event";
CM_ SG_ 2382594561 DATC_Crc5Val "DATC_CyclicRedundancyCheck5Value";
CM_ SG_ 2382594561 DATC_AlvCnt5Val "DATC_AliveCounter5Value";
CM_ SG_ 2382594561 DATC_FrDrvModDis "DATC_FrontDriverModeDisplay";
CM_ SG_ 2382594561 DATC_FrPassModDis "DATC_FrontPassengerModeDisplay";
CM_ SG_ 2382594561 DATC_ClmtTxtPopupOSD "Climate Text Pop-up OSD";
CM_ SG_ 2382594561 DATC_TempDispUnitSta "DATC_TemperatureDiplayUnitStatus";
CM_ SG_ 2382594561 DATC_DrvAutoDis "DATC_DriverAutoDisplay";
CM_ SG_ 2382594561 DATC_FrChgReqDis "DATC_FrontChangeRequestDisplay";
CM_ SG_ 2382594561 DATC_FrClmtScrnDis "DATC_FrontClimateScreenDisplay";
CM_ SG_ 2382594561 DATC_AcDis "DATC_ACDisplay";
CM_ SG_ 2382594561 DATC_IntakeSta "DATC_IntakeStatus";
CM_ SG_ 2382594561 DATC_TempDrLvl "Level of temp door";
CM_ SG_ 2382594561 DATC_BattCompPwrCnsmptn_W "This signal indicates consumption power by e-compressor for battery";
CM_ BO_ 2424580353 "[PE] Periodic and On Event";
CM_ SG_ 2424580353 DATC_Crc12Val "DATC_CyclicRedundancyCheck12Value";
CM_ SG_ 2424580353 DATC_AlvCnt12Val "DATC_AliveCounter12Value";
CM_ SG_ 2424580353 DATC_StrWhlHtrSwReq "DATC_SteeringWheelHeaterSwitchRequest";
CM_ SG_ 2424580353 DATC_FRStHtrSwReq "DATC_FrontRightSeatHeaterSwitchRequest";
CM_ SG_ 2424580353 DATC_FRStVentSwReq "DATC_FrontRightSeatVentilationSwitchRequest";
CM_ SG_ 2424580353 DATC_RrDefSw "Rear Defog Switch";
CM_ SG_ 2424580353 DATC_FLStOpReq "DATC_FrontLeftSeatOperationRequest";
CM_ SG_ 2424580353 DATC_FRStOpReq "DATC_FrontRightSeatOperationRequest";
CM_ SG_ 2424580353 DATC_FLStHtrSwReq "DATC_FrontLeftSeatHeaterSwitchRequest";
CM_ SG_ 2424580353 DATC_FLStVentSwReq "DATC_FrontLefttSeatVentilationSwitchRequest";
CM_ SG_ 2424580353 DATC_FLStTmblrSwReq "DATC_FrontLefttSeatTumblerSwitchRequest";
CM_ SG_ 2424580353 DATC_FRStTmblrSwReq "DATC_FrontRightSeatTumblerSwitchRequest";
CM_ SG_ 2424580353 DATC_RRStHtrSwReq "DATC_RearRightSeatHeaterSwitchRequest";
CM_ SG_ 2424580353 DATC_RRStVentSwReq "DATC_RearRightSeatVentilationSwitchRequest";
CM_ SG_ 2424580353 DATC_RLStHtrSwReq "DATC_RearLeftSeatHeaterSwitchRequest";
CM_ SG_ 2424580353 DATC_RLStVentSwReq "DATC_RearLefttSeatVentilationSwitchRequest";
CM_ SG_ 2424580353 DATC_WdwClsReq "DATC_WindowCloseRequest";
CM_ SG_ 2424580353 DATC_RRSyncDis "DATC_RRSyncDisplay";
CM_ BO_ 2176872449 "[P] Periodic";
CM_ SG_ 2176872449 HTCU_Crc5Val "HTCU_CyclicRedundancyCheck5Value";
CM_ SG_ 2176872449 HTCU_AlvCnt5Val "HTCU_AliveCounter5Value";
CM_ SG_ 2176872449 HDCT_AddtnlTqLssVal "Additional Torque Loss Value ## TCU16 - CR_Tcu_AddTqLoss_Pc";
CM_ SG_ 2176872449 HDCT_OBDSta "OBD Status ## TCU16 - CF_Tcu_ObdStat";
CM_ SG_ 2176872449 HDCT_OBDErrSta "OBD Error Status ## TCU16 - CF_Tcu_ObdRelErr";
CM_ SG_ 2176872449 HDCT_StcShftLrchCtrl "Static Shift Lurch Control ## TCU16 - CF_Tcu_StaticLurchCtl";
CM_ SG_ 2176872449 HDCT_EngCltchLmphmMod "Engine Clutch Limphome Mode ## TCU16 - CF_Tcu_CltLimAct";
CM_ SG_ 2176872449 HDCT_CurrPrgrm "Current Program ## TCU16 - CF_Tcu_CurProgram";
CM_ SG_ 2176872449 HDCT_FltSta "TCU fault status ## TCU16 - CF_Tcu_Flt";
CM_ SG_ 2176872449 HDCT_MCUAntJrkInhbt "MCU Anti-Jerk Inhibition ## TCU16 - CF_Tcu_MCUAntiJerkInh";
CM_ SG_ 2176872449 HDCT_TrgtGear "Target Gear ## TCU11 - CF_Tcu_TarGe";
CM_ SG_ 2176872449 HDCT_CurrGear "Current Gear ## TCU11 - HDCT_CurrGear";
CM_ SG_ 2176872449 HDCT_GearSelDis "Gear Select Display ## TCU11 - CF_Tcu_GarSelDisp";
CM_ BO_ 2176872450 "[P] Periodic";
CM_ SG_ 2176872450 HDCT_TCURdySta "TCU Ready Status ## TCU11 - CF_Tcu_Rdy";
CM_ SG_ 2176872450 HDCT_NetrlCtrlSta "Neutralize Control Status ## TCU11 - CF_Tcu_NeutAck";
CM_ SG_ 2176872450 HDCT_GearShftSta "Gear Shfit Status ## TCU11 - CF_Tcu_GarChange";
CM_ SG_ 2176872450 HDCT_TqRdctnVal "Torque Reduction Value ## TCU11 - CR_Tcu_TqRedReq_Pc";
CM_ SG_ 2176872450 HDCT_CtrlablSta "Controllable Status ## TCU11 - CF_Tcu_Cont";
CM_ SG_ 2176872450 HTCU_SlwTqRdctnVal "Slow Torque Reduction Value ## TCU11 - CR_Tcu_TqRedReqSlw_Pc";
CM_ SG_ 2176872450 HDCT_TqIncReq "Torque Increase Request ## TCU11 - CF_Tcu_TqIncReq";
CM_ SG_ 2176872450 HDCT_TqIncVal "Torque Increase Value ## TCU11 - CR_Tcu_TqIncReq_Pc";
CM_ SG_ 2176872450 HDCT_TrgtShftCls "Target Shift Class ## TCU11 - CF_Tcu_ShiftClass";
CM_ SG_ 2176872450 HDCT_EOLReq "EOL Request ## DCT_TCU1 - CF_Tcu_DCT_EOLReq";
CM_ SG_ 2176872450 HDCT_CltchSta "Clutch Status ## DCT_TCU1 - CF_Tcu_CltStat";
CM_ SG_ 2176872450 HDCT_DblCltchSta "Double Clutch Status ## DCT_TCU1 - CF_Tcu_DCT_CltState";
CM_ SG_ 2176872450 HDCT_AcnChrgInhbtReq "Aircon Change Inhibit Request ## DCT_TCU1 - CF_Tcu_ChgInhAC";
CM_ SG_ 2176872450 HDCT_SlipCrnkAllw "Slip Crank Allow ## DCT_TCU1 - CF_Tcu_SlipCrk_Allow";
CM_ SG_ 2176872450 HDCT_KckDnSkpShftCnt "Kick Down Skip Shift Count ## DCT_TCU1 - CF_Tcu_KD_SkipShft_Cnt";
CM_ SG_ 2176872450 HDCT_ShftPhase "Shift Phase ## TCU11 - CF_Tcu_ShiftPhase";
CM_ BO_ 2176872451 "[P] Periodic";
CM_ SG_ 2176872451 HDCT_FuelCutReq "Fuel Cut Request ## DCT_TCU1 - CF_Tcu_FuelCutReq";
CM_ SG_ 2176872451 HDCT_NCoastTrgtGear "N Coast Target Gear ## DCT_TCU1 - CR_Tcu_NCoastTgtGear";
CM_ SG_ 2176872451 HDCT_CLUEngSpdFlag "Cluster Engine Speed Flag ## DCT_TCU1 - Cluster_Engine_RPM_Flag";
CM_ SG_ 2176872451 HDCT_CLUTrgtGear "Clutster Target Gear ## DCT_TCU1 - CF_Tcu_TarGeforCLU";
CM_ SG_ 2176872451 HDCT_GSITrgtGear "GSI Target Gear ## DCT_TCU1 - CF_Tcu_GSITgtGear";
CM_ SG_ 2176872451 HDCT_NCoastDnReq "N Coast Down Request ## DCT_TCU1 - CF_Tcu_NcoastDwnReq";
CM_ SG_ 2176872451 HDCT_CLUEngSpd "Clutster Engine Speed ## DCT_TCU1 - Cluster_Engine_RPM";
CM_ BO_ 2176872452 "[P] Periodic";
CM_ BO_ 676 "[EC] On Event and On Change";
CM_ SG_ 676 C_DrAirSptNValueSet_EC "Driver Seat Smart Air Support On/Off";
CM_ SG_ 676 C_DrCushSoftNValueSet_EC "Driver Seat Cushion Softness";
CM_ SG_ 676 C_AstAirSptNValueSet_EC "Assistant Seat Smart Air Support On/Off";
CM_ SG_ 676 C_DrBackSoftNValueSet_EC "Driver Seat Back Softness";
CM_ SG_ 676 C_AstAirSptModeNValueSet_EC "Assistant Seat Smart Air Support Mode";
CM_ SG_ 676 C_DrAirSptModeNValueSet_EC "Driver Seat Smart Air Support Mode";
CM_ SG_ 676 C_RLAirSptNValueSet_EC "2nd Left Seat Smart Air Support On/Off";
CM_ SG_ 676 C_AstAirSptStrNValueSet_EC "Assistant Seat Smart Air Support Strength";
CM_ SG_ 676 C_AstAirSptTimeNValueSet_EC "Assistant Seat Smart Air Support Time";
CM_ SG_ 676 C_RRAirSptNValueSet_EC "2nd Right side seat Smart Air Support On/Off";
CM_ SG_ 676 C_AstCushSoftNValueSet_EC "Assistant Seat Cushion Softness off/low/mid/high";
CM_ SG_ 676 C_AstBackSoftNValueSet_EC "Assistant Seat Back Softness Off/Low/Mid/High";
CM_ SG_ 676 C_AstRlxNValueSet_EC "Assistant seat Moving control : Relaxtion mode";
CM_ SG_ 676 C_RLAirSptModeNValueSet_EC "2nd Left Seat Smart Air Support Mode";
CM_ SG_ 676 C_DrAirSptStrNValueSet_EC "Driver Seat Smart Air Support Strength";
CM_ SG_ 676 C_RLAirSptStrNValueSet_EC "2nd Left Seat Smart Air Support Strength";
CM_ SG_ 676 C_RLAirSptTimeNValueSet_EC "2nd Left Seat Smart Air Support Time";
CM_ SG_ 676 C_DrAirSptTimeNValueSet_EC "Driver Seat Smart Air Support Time";
CM_ BO_ 677 "[EC] On Event and On Change";
CM_ SG_ 677 C_RLBackSoftNValueSet_EC "2nd Left Seat Back Softness";
CM_ SG_ 677 C_RRAirSptStrNValueSet_EC "2nd Right side seat Smart Air Support Strength";
CM_ SG_ 677 C_RRAirSptTimeNValueSet_EC "2nd Right side seat Smart Air Support Time";
CM_ SG_ 677 C_RRBackSoftNValueSet_EC "2nd Right side seat Back Softness";
CM_ SG_ 677 C_RROneTchNvalueSet_EC "2nd Right side seat One Touch Mode";
CM_ SG_ 677 C_RLOneTchNValueSet_EC "2nd Left side seat One Touch Mode";
CM_ SG_ 677 C_RRAirSptModeNValueSet_EC "2nd Right side seat Moving control : Smart Air Support Mode";
CM_ BO_ 1239 "[PE] Periodic and On Event";
CM_ SG_ 1239 HU_ADMSettingState "Information for ADM(Accessry Delay Mode) Setting Vaule in HU / Made at 2021.1.25";
CM_ SG_ 1239 HU_DigitalKeyInformAvailable "DigitalKeyInformAvailable";
CM_ SG_ 1239 HU_VehiclePwr "Information for the H/U power status for ADM(Accessary Delay Mode)";
CM_ BO_ 1240 "[PE] Periodic and On Event";
CM_ SG_ 1240 HU_DistanceUnit "Request to set CLU Distance Unit";
CM_ SG_ 1240 HU_MicActivity "HU send this signal to eCall for MIC using status.
eCall unit stop the diagonosis when received 0x1:Activated from HU
Otherwise, eCall unit keep diagnosis every 1 sec. and HU can not use MIC";
CM_ SG_ 1240 CF_HU_GPSFlt "Information of GPS Fault 

0x0: Normal
0x1 : Fault operation
0x2 : Reserved
0x3:Invalid";
CM_ SG_ 1240 AVN_RSPA_CancelInput "Request Signal to cancel RSPA function";
CM_ SG_ 1240 AVN_RSPA_Disp_Rdy "Signal to inform RSPA of AVN's display ready status
(RSPA È­¸é Ç¥½Ã °¡´É/ºÒ°¡´É »óÅÂ¸¦ ¾Ë¸®±â À§ÇÑ ½ÅÈ£)";
CM_ SG_ 1240 CF_AVN_ProfileIDRValue "This signal is User ID value in H/Unit.";
CM_ SG_ 1240 HazardFromHUSVM "This signal is for Hazard control";
CM_ SG_ 1240 OMUOSMirCtrl "This signal is for the OutSide Mirror Control (Fold or Unfold)";
CM_ SG_ 1240 OTAUIStatus "Information of the status of Head Unit";
CM_ SG_ 1240 C_TeleActiveStatus "This signal is for check TMS active status";
CM_ SG_ 1240 HU_AliveStatus "Information of the status of Head Unit
0x00 : Headunit is booting so, Headunit cant display any state
0x01 : Headunit is normal state, Headunit could display according to MM CAN  command.
0x02 : Headunit is doing their internal process, so Headunit cant communicate with other node.
For CLU/SCC/eCall
-AVN System transmission signal";
CM_ SG_ 1240 HU_RTCCheck "Checking whether RTC of AVN and HCU is operationg normally.";
CM_ BO_ 1218 "[EC] On Event and On Change";
CM_ SG_ 1218 C_AVN_PTGHeightNValueSet "Power Tailgate(Trunk) Height Request Signal";
CM_ SG_ 1218 CF_AVN_SCCMLReset "Request for SCC-ML reset";
CM_ SG_ 1218 C_HAnBNValueSet "USM Request for Horn Feedback";
CM_ SG_ 1218 CF_AVN_RrSeatRemindNValueSet "USM Request for Rear Seat Remind function";
CM_ SG_ 1218 CF_AVN_DSWNValueSet "Request for driver state warning";
CM_ SG_ 1218 CF_AVN_RRPSU_RLNValueSet "Request for Seat easy access of rear left seat";
CM_ SG_ 1218 CF_AVN_APSUNValueSet "Request for easy access of passenger seat";
CM_ SG_ 1218 CF_AVN_NCC_CameraNValueSet "Request for Eco Vehicle NCC";
CM_ SG_ 1218 CF_AVN_FCAJnctnNValueSet "Request for foward cross traffic safety";
CM_ SG_ 1218 CF_AVN_RRPSU_RRNValueSet "Request for seat easy access of rear right seat";
CM_ SG_ 1218 CF_AVN_HtBlcAstNValueSet "Request for Passenger seat heater balance";
CM_ SG_ 1218 CF_AVN_HtBlcDrvNValueSet "Request for Driver seat heater balance";
CM_ SG_ 1218 CF_AVN_SCCModeNValueSet "This signal request for scc setting(Whether sccml or following driving mode)";
CM_ SG_ 1218 CF_AVN_SCCMLChar1Set "Request for scc-ml acceleration learning result change";
CM_ SG_ 1218 CF_AVN_UIPNValueSet "USM Request for Ultrasonic Intrusion Protection function";
CM_ SG_ 1218 CF_AVN_SCCMLChar2Set "Request for scc-ml distnace learning result change";
CM_ SG_ 1218 CF_AVN_SCCMLChar3Set "Request for scc-ml reaction learning result change";
CM_ SG_ 1218 CF_AVN_HDALCFuncNValueSet "Request for highway lane change assist";
CM_ BO_ 675 "[EC] On Event and On Change";
CM_ SG_ 675 CF_AVN_HtBlcRLNValueSet "Request for 2nd Left seat heater balance";
CM_ SG_ 675 CF_AVN_HtBlcRRNValueSet "Request for 2nd Right seat heater balance";
CM_ SG_ 675 CF_AVN_RemoteWDWNValueSet "Remote Window On/Off Set signal of USM for Fob Key";
CM_ SG_ 675 USM_TowWeight_Set "Trailer Mode Setting USM: Tow Weight set for User";
CM_ SG_ 675 CF_AVN_PABArbgNValueSet "USM PAB On/Off Set Signal";
CM_ SG_ 675 CF_AVN_SportHUD2 "Related to HUD Sports mode of custom mode2";
CM_ SG_ 675 CF_AVN_ArHudLeftRightSet "AR Hud Left Right Set Signal";
CM_ SG_ 675 HU_CustomNewMenuSet "Custom Mode User Setting Signal";
CM_ SG_ 675 CF_AVN_ArHudViewSet "AR Mode Height View Set Signal";
CM_ SG_ 675 USM_RpmComfortRearSet "RPM Display Setting When Comfort(Rear) mode Set";
CM_ SG_ 675 Usm_RpmMyDriveModeSet "Cluster MY Drive Mode RPM Set Signal";
CM_ SG_ 675 CF_AVN_PCA_RrEquipNvalueSet "Headunit Setting signal for Rear Safety of USM";
CM_ BO_ 1251 "[EC] On Event and On Change";
CM_ BO_ 2172675329 "[P] Periodic";
CM_ SG_ 2172675329 IEB_Crc1Val "IEB_CyclicRedundancyCheck1Value";
CM_ SG_ 2172675329 IEB_AlvCnt1Val "IEB_AliveCounter1Value";
CM_ SG_ 2172675329 IEB_SrvLmpDis "IEB_ServiceLampDisplay ##2G##ESC - AHB1 - CF_Ahb_SLmp";
CM_ SG_ 2172675329 IEB_DfctvSta "IEB_DefectiveStatus ##2G##ESC - AHB1 - CF_Ahb_Def";
CM_ SG_ 2172675329 IEB_ActvSta "IEB_ActiveStatus ##2G##ESC - AHB1 - CF_Ahb_Act";
CM_ SG_ 2172675329 IEB_DiagSta "IEB_DiagnosticStatus ##2G##ESC - AHB1 - CF_Ahb_Diag";
CM_ SG_ 2172675329 IEB_WrngLmpDis "IEB_WarningLampDisplay ##2G##ESC - AHB1 - CF_Ahb_WLmp";
CM_ SG_ 2172675329 IEB_MILReq "MIL Requeset";
CM_ SG_ 2172675329 IEB_StrkDpthmmVal "IEB_StrokeDepthmmValue ##2G##ESC - AHB1 - CR_Ahb_StDep_mm";
CM_ SG_ 2172675329 IEB_BrkActvSta "IEB_BrakeActiveStatus ##2G##ESC - AHB1 - CF_Esc_BrakeAct";
CM_ SG_ 2172675329 IEB_PdlTrvlSnsrFailSta "IEB_PedalTravelSensorFailStatus ##2G##ESC - AHB1 - CF_Ahb_SnsFail";
CM_ SG_ 2172675329 IEB_PdlCalibSta "IEB_PedalCalibrationStatus ##2G##ESC - AHB1 - CF_Ahb_PedalCalStat";
CM_ SG_ 2172675329 IEB_BzrSta "IEB_BuzzerStatus ##2G##ESC - AHB1 - CF_Ahb_Bzzr";
CM_ BO_ 2172675332 "[P] Periodic";
CM_ SG_ 2172675332 TCS_MtrTrgtRpm_Flag_Frnt "TCS_MotorTargetRPM_Flag_Front";
CM_ SG_ 2172675332 TCS_MtrTrgtRpm_Flag_Rear "TCS_MotorTargetRPM_Flag_Rear";
CM_ SG_ 2172675332 TCS_MtrTrgtRpm_Rear "TCS_MotorTargetRPM_Rear";
CM_ SG_ 2172675332 IEB_DriftModeSta "Display";
CM_ SG_ 2172675332 IEB_DriftModeActSta "ON/OFF status, Symbol";
CM_ SG_ 2172675332 TCS_MtrTrgtRpm_Frnt "TCS_MotorTargetRPM_Front";
CM_ BO_ 1227 "[EC] On Event and On Change";
CM_ SG_ 1227 DrvIMS_MemoryP1Req "PSM_DriverSeatPositionMemoryP1Request";
CM_ SG_ 1227 DrvIMS_PlyBckP2Req "PSM_PlayBackP2Request";
CM_ SG_ 1227 DrvIMS_PlyBckP3Req "PSM_PlayBackP3Request";
CM_ SG_ 1227 DrvIMS_PlyBckStpReq "PSM_PlayBackStopRequest";
CM_ SG_ 1227 SmrtIMS_PlyBckReq "HCIMS_PlayBackRequest";
CM_ SG_ 1227 DrvIMS_MemoryP2Req "PSM_DriverSeatPositionMemoryP2Request";
CM_ SG_ 1227 SmrtIMS_ImgDBVal "Smart IMS image DB number";
CM_ SG_ 1227 SmrtIMS_PlyBckStpReq "HCIMS_Status";
CM_ SG_ 1227 DrvIMS_MemoryP3Req "PSM_DriverSeatPositionMemoryP3Request";
CM_ SG_ 1227 SmrtIMS_EnterSwSta "Smart IMS switch on using IMS switch";
CM_ SG_ 1227 DrvIMS_BzrReq "PSM_DriverSeatImsBuzzerRequest";
CM_ SG_ 1227 DrvIMS_ErrConWmgDis "Warning about IMS Mem/Play Error Condition";
CM_ SG_ 1227 Drv_AutoRlxWrngDis "Drive seat auto relax warning information for AVN display";
CM_ SG_ 1227 DrvIMS_MemorySetEnaSta "PSM_MemorySetEnableStatus";
CM_ SG_ 1227 DrvIMS_PlyBckP1Req "PSM_PlayBackP1Request";
CM_ BO_ 1252 "[EC] On Event and On Change";
CM_ SG_ 1252 RKE_Crc1Val "RKE_CyclicRedundancyCheck1Value";
CM_ SG_ 1252 RKE_AlvCnt1Val "RKE_AliveCounter1Value";
CM_ SG_ 1252 RKE_BtnReq "RemoteKey_ButtonRequest ##2G##BCM - BCMmsg01 - C_RKECmd";
CM_ SG_ 1252 RKE_PsdBtnReq "RemoteKey_PowerSlindingDoorButtonRequest ##2G##BCM - BCMmsg01 - C_RKEPSDCmd";
CM_ SG_ 1252 RKE_WdwUpDnReq "RemoteKey_WindowUpDownRequest ##2G##BCM - BCMmsg01 - C_WdwComfortCMDBCM";
CM_ SG_ 1252 RKE_TrnkTlgtBtnReq "RemoteKey_Trunk/TailgateButtonRequest ##2G##BCM - BCMmsg01 - C_TailgateTrunkRKECMD";
CM_ SG_ 1252 RKE_ID "RemoteKey_ID ##2G##BCM - BCMmsg01 - C_BCMRKEID";
CM_ BO_ 1237 "[EC] On Event and On Change";
CM_ SG_ 1237 SWRC_Crc2Val "SWRC_CyclicRedundancyCheck2Value";
CM_ SG_ 1237 SWRC_AlvCnt2Val "SWRC_AliveCounter2Value";
CM_ SG_ 1237 Audio_VolEncoderSta "Audio_VolumeScrollSwitchStatus";
CM_ SG_ 1237 Cluster_ScrlEncoderSta "Cluster_ScrollSwitchStatus";
BA_DEF_ BO_ "DiagState" ENUM "No","Yes" ;
BA_DEF_ BO_ "DiagResponse" ENUM "No","Yes" ;
BA_DEF_ BO_ "DiagRequest" ENUM "No","Yes" ;
BA_DEF_ BO_ "TpMessage" ENUM "No","Yes" ;
BA_DEF_ BO_ "UsrMsgIDSforwardDeviation" INT 0 100 ;
BA_DEF_ BO_ "UsrMsgIDSbackwardDeviation" INT 50 1000 ;
BA_DEF_ BO_ "GenMsgCycleTime" INT 0 2000 ;
BA_DEF_ BO_ "GenMsgStartDelayTime" INT 0 2000 ;
BA_DEF_ BO_ "GenMsgSendType" ENUM "Cyclic","NoMsgSendType" ;
BA_DEF_ BO_ "GenMsgCycleTimeFast" INT 0 500 ;
BA_DEF_ BO_ "GenMsgDelayTime" INT 0 20 ;
BA_DEF_ BO_ "GenMsgILSupport" ENUM "No","Yes" ;
BA_DEF_ BO_ "GenMsgNrOfRepetition" INT 0 3 ;
BA_DEF_ BO_ "NmMessage" ENUM "No","Yes" ;
BA_DEF_ BO_ "NWM-Botschaft" ENUM "No","Yes" ;
BA_DEF_ BO_ "TpTxIndex" INT 0 255 ;
BA_DEF_ BO_ "VFrameFormat" ENUM "StandardCAN","ExtendedCAN","reserved","reserved","reserved","reserved","reserved","reserved","reserved","reserved","reserved","reserved","reserved","reserved","StandardCAN_FD","ExtendedCAN_FD" ;
BA_DEF_ SG_ "UserSigValidity" ENUM "B+","ACC","IG","IG1","IG2","IG3","IG1 or IG2","IG1 or IG3","Undef" ;
BA_DEF_ SG_ "TimeoutValue" STRING ;
BA_DEF_ SG_ "UsrSigPurpose" ENUM "Undef","FN","DIAG","DIAG(Req)","DIAG(Res)","DIAG(Phy)","DEV","CCP(Req)","CCP(Res)","NM","TP" ;
BA_DEF_ SG_ "GenSigStartValue" INT 0 1215752192 ;
BA_DEF_ SG_ "NetworkRequest" ENUM "Yes","No" ;
BA_DEF_ SG_ "NetworkRequestHoldingTime" INT 0 65535 ;
BA_DEF_ SG_ "Description" STRING ;
BA_DEF_ SG_ "Version" STRING ;
BA_DEF_ SG_ "GenSigEnvVarType" ENUM "Int","Float","Undef" ;
BA_DEF_ SG_ "GenSigSendType" ENUM "Cyclic","OnWrite","OnWriteWithRepetition","OnChange","OnChangeWithRepetition","IfActive","IfActiveWithRepetition","NoSigSendType","OnChangeAndIfActive","OnChangeAndIfActiveWithRepetition" ;
BA_DEF_ SG_ "GwSigLatencyTime" INT 0 65536 ;
BA_DEF_ SG_ "GwSigMissingSourceType" ENUM "Undef","OldValue","DefaultValue","InitialValue" ;
BA_DEF_ SG_ "NWM-WakeupAllowed" ENUM "<n.a.>" ;
BA_DEF_ SG_ "RoutingFactor" INT 1 1215752192 ;
BA_DEF_REL_ BU_SG_REL_ "GenSigTimeoutTime" INT 0 7000 ;
BA_DEF_DEF_ "DiagState" "No" ;
BA_DEF_DEF_ "DiagResponse" "No" ;
BA_DEF_DEF_ "DiagRequest" "No" ;
BA_DEF_DEF_ "TpMessage" "No" ;
BA_DEF_DEF_ "UsrMsgIDSforwardDeviation" 10 ;
BA_DEF_DEF_ "UsrMsgIDSbackwardDeviation" 100 ;
BA_DEF_DEF_ "GenMsgCycleTime" 200 ;
BA_DEF_DEF_ "GenMsgStartDelayTime" 0 ;
BA_DEF_DEF_ "GenMsgSendType" "NoMsgSendType" ;
BA_DEF_DEF_ "GenMsgCycleTimeFast" 40 ;
BA_DEF_DEF_ "GenMsgDelayTime" 20 ;
BA_DEF_DEF_ "GenMsgILSupport" "Yes" ;
BA_DEF_DEF_ "GenMsgNrOfRepetition" 3 ;
BA_DEF_DEF_ "NmMessage" "No" ;
BA_DEF_DEF_ "NWM-Botschaft" "No" ;
BA_DEF_DEF_ "TpTxIndex" 0 ;
BA_DEF_DEF_ "VFrameFormat" "StandardCAN" ;
BA_DEF_DEF_ "UserSigValidity" "IG" ;
BA_DEF_DEF_ "TimeoutValue" "" ;
BA_DEF_DEF_ "UsrSigPurpose" "FN" ;
BA_DEF_DEF_ "GenSigStartValue" 0 ;
BA_DEF_DEF_ "NetworkRequest" "No" ;
BA_DEF_DEF_ "NetworkRequestHoldingTime" 0 ;
BA_DEF_DEF_ "Description" "" ;
BA_DEF_DEF_ "Version" "" ;
BA_DEF_DEF_ "GenSigEnvVarType" "Undef" ;
BA_DEF_DEF_ "GenSigSendType" "NoSigSendType" ;
BA_DEF_DEF_ "GwSigLatencyTime" 40 ;
BA_DEF_DEF_ "GwSigMissingSourceType" "Undef" ;
BA_DEF_DEF_ "NWM-WakeupAllowed" "<n.a.>" ;
BA_DEF_DEF_ "RoutingFactor" 1 ;
BA_DEF_DEF_REL_ "GenSigTimeoutTime" 500 ;
BA_ "GenMsgCycleTime" BO_ 694 0;
BA_ "Description" SG_ 694 ASAU_NotFootMsgOperStaWarn "Passenger Foot Massage Operation Disable Mode";
BA_ "GenSigSendType" SG_ 694 ASAU_NotFootMsgOperStaWarn 4;
BA_ "UserSigValidity" SG_ 694 ASAU_NotFootMsgOperStaWarn 3;
BA_ "NetworkRequest" SG_ 694 ASAU_NotFootMsgOperStaWarn 0;
BA_ "NetworkRequestHoldingTime" SG_ 694 ASAU_NotFootMsgOperStaWarn 5000;
BA_ "RoutingFactor" SG_ 694 ASAU_NotFootMsgOperStaWarn 0;
BA_ "Version" SG_ 694 ASAU_NotFootMsgOperStaWarn "20.08.00";
BA_ "GenMsgCycleTime" BO_ 678 0;
BA_ "GenSigSendType" SG_ 678 Ast_AutoRlxWrngDis 4;
BA_ "UserSigValidity" SG_ 678 Ast_AutoRlxWrngDis 1;
BA_REL_ "GenSigTimeoutTime" BU_SG_REL_ CGW_CCU SG_ 678 Ast_AutoRlxWrngDis 0;
BA_ "NetworkRequest" SG_ 678 Ast_AutoRlxWrngDis 0;
BA_ "NetworkRequestHoldingTime" SG_ 678 Ast_AutoRlxWrngDis 5000;
BA_ "RoutingFactor" SG_ 678 Ast_AutoRlxWrngDis 0;
BA_ "Version" SG_ 678 Ast_AutoRlxWrngDis "21.06.10";
BA_ "GenSigSendType" SG_ 678 APSM_IMSWngDis 4;
BA_ "UserSigValidity" SG_ 678 APSM_IMSWngDis 0;
BA_ "NetworkRequest" SG_ 678 APSM_IMSWngDis 0;
BA_ "NetworkRequestHoldingTime" SG_ 678 APSM_IMSWngDis 5000;
BA_ "RoutingFactor" SG_ 678 APSM_IMSWngDis 0;
BA_ "Version" SG_ 678 APSM_IMSWngDis "21.08.01";
BA_ "GenMsgCycleTime" BO_ 158 0;
BA_ "Description" SG_ 158 ATS_DATC_FrDrBlowerSet "Àü¼® ¿îÀü¼® Ãø ºí·Î¿ö ´Ü¼ö ¼³Á¤";
BA_ "GenSigSendType" SG_ 158 ATS_DATC_FrDrBlowerSet 4;
BA_ "GenSigStartValue" SG_ 158 ATS_DATC_FrDrBlowerSet 15;
BA_ "UserSigValidity" SG_ 158 ATS_DATC_FrDrBlowerSet 3;
BA_REL_ "GenSigTimeoutTime" BU_SG_REL_ CGW_CCU SG_ 158 ATS_DATC_FrDrBlowerSet 0;
BA_ "Version" SG_ 158 ATS_DATC_FrDrBlowerSet "19.12.08";
BA_ "Description" SG_ 158 ATS_DATC_RrDrTempUpDn "ÈÄ¼® ¿îÀü¼® Ãø ¼³Á¤¿Âµµ Áõ°¨ ¼³Á¤";
BA_ "GenSigSendType" SG_ 158 ATS_DATC_RrDrTempUpDn 4;
BA_ "UserSigValidity" SG_ 158 ATS_DATC_RrDrTempUpDn 3;
BA_REL_ "GenSigTimeoutTime" BU_SG_REL_ CGW_CCU SG_ 158 ATS_DATC_RrDrTempUpDn 0;
BA_ "Version" SG_ 158 ATS_DATC_RrDrTempUpDn "19.12.08";
BA_ "Description" SG_ 158 ATS_DATC_RrDrBlowerSet "ÈÄ¼® ¿îÀü¼® Ãø ºí·Î¿ö Áõ°¨ ¼³Á¤";
BA_ "GenSigSendType" SG_ 158 ATS_DATC_RrDrBlowerSet 4;
BA_ "GenSigStartValue" SG_ 158 ATS_DATC_RrDrBlowerSet 15;
BA_ "UserSigValidity" SG_ 158 ATS_DATC_RrDrBlowerSet 3;
BA_REL_ "GenSigTimeoutTime" BU_SG_REL_ CGW_CCU SG_ 158 ATS_DATC_RrDrBlowerSet 0;
BA_ "Version" SG_ 158 ATS_DATC_RrDrBlowerSet "19.12.08";
BA_ "Description" SG_ 158 ATS_DATC_RrDrModeSet "ÈÄ¼® ¿îÀü¼® Ãø ¸ðµå ¼³Á¤";
BA_ "GenSigSendType" SG_ 158 ATS_DATC_RrDrModeSet 4;
BA_ "GenSigStartValue" SG_ 158 ATS_DATC_RrDrModeSet 15;
BA_ "UserSigValidity" SG_ 158 ATS_DATC_RrDrModeSet 3;
BA_REL_ "GenSigTimeoutTime" BU_SG_REL_ CGW_CCU SG_ 158 ATS_DATC_RrDrModeSet 0;
BA_ "Version" SG_ 158 ATS_DATC_RrDrModeSet "19.12.08";
BA_ "Description" SG_ 158 ATS_DATC_FrDrModeSet "Àü¼® ¿îÀü¼® Ãø ¸ðµå ¼³Á¤";
BA_ "GenSigSendType" SG_ 158 ATS_DATC_FrDrModeSet 4;
BA_ "UserSigValidity" SG_ 158 ATS_DATC_FrDrModeSet 3;
BA_REL_ "GenSigTimeoutTime" BU_SG_REL_ CGW_CCU SG_ 158 ATS_DATC_FrDrModeSet 0;
BA_ "Version" SG_ 158 ATS_DATC_FrDrModeSet "19.12.08";
BA_ "Description" SG_ 158 ATS_DATC_RrOnOffSet "ÈÄ¼® °øÁ¶ ¿Â¿ÀÇÁ ¼³Á¤";
BA_ "GenSigSendType" SG_ 158 ATS_DATC_RrOnOffSet 4;
BA_ "GenSigStartValue" SG_ 158 ATS_DATC_RrOnOffSet 3;
BA_ "UserSigValidity" SG_ 158 ATS_DATC_RrOnOffSet 3;
BA_ "Version" SG_ 158 ATS_DATC_RrOnOffSet "19.12.08";
BA_ "Description" SG_ 158 ATS_DATC_IntakeSet "³»¿Ü±â ¼³Á¤";
BA_ "GenSigSendType" SG_ 158 ATS_DATC_IntakeSet 4;
BA_ "GenSigStartValue" SG_ 158 ATS_DATC_IntakeSet 3;
BA_ "UserSigValidity" SG_ 158 ATS_DATC_IntakeSet 3;
BA_REL_ "GenSigTimeoutTime" BU_SG_REL_ CGW_CCU SG_ 158 ATS_DATC_IntakeSet 0;
BA_ "Version" SG_ 158 ATS_DATC_IntakeSet "19.12.08";
BA_ "Description" SG_ 158 ATS_DATC_OffReq "Àü¼® °øÁ¶ ¿ÀÇÁ ¼³Á¤";
BA_ "GenSigSendType" SG_ 158 ATS_DATC_OffReq 4;
BA_ "UserSigValidity" SG_ 158 ATS_DATC_OffReq 3;
BA_ "Version" SG_ 158 ATS_DATC_OffReq "19.12.08";
BA_ "Description" SG_ 158 ATS_DATC_FrDrAutoSet "Àü¼® ¿îÀü¼® Ãø AUTO ¼³Á¤";
BA_ "GenSigSendType" SG_ 158 ATS_DATC_FrDrAutoSet 4;
BA_ "UserSigValidity" SG_ 158 ATS_DATC_FrDrAutoSet 3;
BA_REL_ "GenSigTimeoutTime" BU_SG_REL_ CGW_CCU SG_ 158 ATS_DATC_FrDrAutoSet 0;
BA_ "Version" SG_ 158 ATS_DATC_FrDrAutoSet "19.12.08";
BA_ "Description" SG_ 158 ATS_DATC_FrPsTempUpDn "Àü¼® Á¶¼ö¼® Ãø ¼³Á¤¿Âµµ Áõ°¨ ¼³Á¤";
BA_ "GenSigSendType" SG_ 158 ATS_DATC_FrPsTempUpDn 4;
BA_ "UserSigValidity" SG_ 158 ATS_DATC_FrPsTempUpDn 3;
BA_REL_ "GenSigTimeoutTime" BU_SG_REL_ CGW_CCU SG_ 158 ATS_DATC_FrPsTempUpDn 0;
BA_ "Version" SG_ 158 ATS_DATC_FrPsTempUpDn "19.12.08";
BA_ "Description" SG_ 158 ATS_DATC_FrDefog "Àü¼® DEF ¼³Á¤";
BA_ "GenSigSendType" SG_ 158 ATS_DATC_FrDefog 4;
BA_ "GenSigStartValue" SG_ 158 ATS_DATC_FrDefog 3;
BA_ "UserSigValidity" SG_ 158 ATS_DATC_FrDefog 3;
BA_REL_ "GenSigTimeoutTime" BU_SG_REL_ CGW_CCU SG_ 158 ATS_DATC_FrDefog 0;
BA_ "Version" SG_ 158 ATS_DATC_FrDefog "19.12.08";
BA_ "Description" SG_ 158 ATS_DATC_RrSyncSet "ÈÄ¼® SYNC ¼³Á¤";
BA_ "GenSigSendType" SG_ 158 ATS_DATC_RrSyncSet 4;
BA_ "UserSigValidity" SG_ 158 ATS_DATC_RrSyncSet 3;
BA_REL_ "GenSigTimeoutTime" BU_SG_REL_ CGW_CCU SG_ 158 ATS_DATC_RrSyncSet 0;
BA_ "Version" SG_ 158 ATS_DATC_RrSyncSet "19.12.08";
BA_ "Description" SG_ 158 ATS_DATC_AcSet "AC ¼³Á¤";
BA_ "GenSigSendType" SG_ 158 ATS_DATC_AcSet 4;
BA_ "GenSigStartValue" SG_ 158 ATS_DATC_AcSet 3;
BA_ "UserSigValidity" SG_ 158 ATS_DATC_AcSet 3;
BA_REL_ "GenSigTimeoutTime" BU_SG_REL_ CGW_CCU SG_ 158 ATS_DATC_AcSet 0;
BA_ "Version" SG_ 158 ATS_DATC_AcSet "19.12.08";
BA_ "Description" SG_ 158 ATS_DATC_AirCleaningSet "°ø±âÃ»Á¤¸ðµå ¼³Á¤";
BA_ "GenSigSendType" SG_ 158 ATS_DATC_AirCleaningSet 4;
BA_ "GenSigStartValue" SG_ 158 ATS_DATC_AirCleaningSet 3;
BA_ "UserSigValidity" SG_ 158 ATS_DATC_AirCleaningSet 3;
BA_REL_ "GenSigTimeoutTime" BU_SG_REL_ CGW_CCU SG_ 158 ATS_DATC_AirCleaningSet 0;
BA_ "Version" SG_ 158 ATS_DATC_AirCleaningSet "19.12.08";
BA_ "Description" SG_ 158 ATS_DATC_FrDrBlowerUpDn "Àü¼® ¿îÀü¼® Ãø ºí·Î¿ö Áõ°¨ ¼³Á¤";
BA_ "GenSigSendType" SG_ 158 ATS_DATC_FrDrBlowerUpDn 4;
BA_ "UserSigValidity" SG_ 158 ATS_DATC_FrDrBlowerUpDn 3;
BA_REL_ "GenSigTimeoutTime" BU_SG_REL_ CGW_CCU SG_ 158 ATS_DATC_FrDrBlowerUpDn 0;
BA_ "Version" SG_ 158 ATS_DATC_FrDrBlowerUpDn "19.12.08";
BA_ "Description" SG_ 158 ATS_DATC_FrDrTempUpDn "Àü¼® ¿îÀü¼® Ãø ¼³Á¤¿Âµµ Áõ°¨ ¼³Á¤";
BA_ "GenSigSendType" SG_ 158 ATS_DATC_FrDrTempUpDn 4;
BA_ "UserSigValidity" SG_ 158 ATS_DATC_FrDrTempUpDn 3;
BA_REL_ "GenSigTimeoutTime" BU_SG_REL_ CGW_CCU SG_ 158 ATS_DATC_FrDrTempUpDn 0;
BA_ "Version" SG_ 158 ATS_DATC_FrDrTempUpDn "19.12.08";
BA_ "Description" SG_ 158 ATS_DATC_RrDrAutoSet "ÈÄ¼® ¿îÀü¼® Ãø AUTO ¼³Á¤";
BA_ "GenSigSendType" SG_ 158 ATS_DATC_RrDrAutoSet 4;
BA_ "GenSigStartValue" SG_ 158 ATS_DATC_RrDrAutoSet 3;
BA_ "UserSigValidity" SG_ 158 ATS_DATC_RrDrAutoSet 3;
BA_REL_ "GenSigTimeoutTime" BU_SG_REL_ CGW_CCU SG_ 158 ATS_DATC_RrDrAutoSet 0;
BA_ "Version" SG_ 158 ATS_DATC_RrDrAutoSet "19.12.08";
BA_ "GenMsgCycleTime" BO_ 157 0;
BA_ "Description" SG_ 157 ATS_DATC_FrDrTempSetC "Àü¼® ¿îÀü¼® Ãø ¼³Á¤¿Âµµ°ª(¼·¾¾) ¼³Á¤";
BA_ "GenSigSendType" SG_ 157 ATS_DATC_FrDrTempSetC 4;
BA_ "GenSigStartValue" SG_ 157 ATS_DATC_FrDrTempSetC 255;
BA_ "UserSigValidity" SG_ 157 ATS_DATC_FrDrTempSetC 3;
BA_REL_ "GenSigTimeoutTime" BU_SG_REL_ CGW_CCU SG_ 157 ATS_DATC_FrDrTempSetC 0;
BA_ "Version" SG_ 157 ATS_DATC_FrDrTempSetC "19.12.08";
BA_ "Description" SG_ 157 ATS_DATC_RrDrBlowerUpDn "ÈÄ¼® ¿îÀü¼® Ãø ºí·Î¿ö Áõ°¨ ¼³Á¤";
BA_ "GenSigSendType" SG_ 157 ATS_DATC_RrDrBlowerUpDn 4;
BA_ "UserSigValidity" SG_ 157 ATS_DATC_RrDrBlowerUpDn 3;
BA_REL_ "GenSigTimeoutTime" BU_SG_REL_ CGW_CCU SG_ 157 ATS_DATC_RrDrBlowerUpDn 0;
BA_ "Version" SG_ 157 ATS_DATC_RrDrBlowerUpDn "19.12.08";
BA_ "Description" SG_ 157 ATS_DATC_FrSyncSet "Àü¼® SYNC ¼³Á¤";
BA_ "GenSigSendType" SG_ 157 ATS_DATC_FrSyncSet 4;
BA_ "UserSigValidity" SG_ 157 ATS_DATC_FrSyncSet 3;
BA_REL_ "GenSigTimeoutTime" BU_SG_REL_ CGW_CCU SG_ 157 ATS_DATC_FrSyncSet 0;
BA_ "Version" SG_ 157 ATS_DATC_FrSyncSet "19.12.08";
BA_ "Description" SG_ 157 ATS_DATC_RrDrTempSetC "ÈÄ¼® ¿îÀü¼® Ãø ¼³Á¤¿Âµµ°ª(¼·¾¾) ¼³Á¤";
BA_ "GenSigSendType" SG_ 157 ATS_DATC_RrDrTempSetC 4;
BA_ "GenSigStartValue" SG_ 157 ATS_DATC_RrDrTempSetC 255;
BA_ "UserSigValidity" SG_ 157 ATS_DATC_RrDrTempSetC 3;
BA_REL_ "GenSigTimeoutTime" BU_SG_REL_ CGW_CCU SG_ 157 ATS_DATC_RrDrTempSetC 0;
BA_ "Version" SG_ 157 ATS_DATC_RrDrTempSetC "19.12.08";
BA_ "Description" SG_ 157 ATS_DATC_RrDrTempSetF "ÈÄ¼® ¿îÀü¼® Ãø ¼³Á¤¿Âµµ°ª(È­¾¾) ¼³Á¤";
BA_ "GenSigSendType" SG_ 157 ATS_DATC_RrDrTempSetF 4;
BA_ "GenSigStartValue" SG_ 157 ATS_DATC_RrDrTempSetF 255;
BA_ "UserSigValidity" SG_ 157 ATS_DATC_RrDrTempSetF 3;
BA_REL_ "GenSigTimeoutTime" BU_SG_REL_ CGW_CCU SG_ 157 ATS_DATC_RrDrTempSetF 0;
BA_ "Version" SG_ 157 ATS_DATC_RrDrTempSetF "19.12.08";
BA_ "Description" SG_ 157 ATS_DATC_FrPsTempSetC "Àü¼® Á¶¼ö¼® Ãø ¼³Á¤¿Âµµ°ª(¼·¾¾) ¼³Á¤";
BA_ "GenSigSendType" SG_ 157 ATS_DATC_FrPsTempSetC 4;
BA_ "GenSigStartValue" SG_ 157 ATS_DATC_FrPsTempSetC 255;
BA_ "UserSigValidity" SG_ 157 ATS_DATC_FrPsTempSetC 3;
BA_REL_ "GenSigTimeoutTime" BU_SG_REL_ CGW_CCU SG_ 157 ATS_DATC_FrPsTempSetC 0;
BA_ "Version" SG_ 157 ATS_DATC_FrPsTempSetC "19.12.08";
BA_ "Description" SG_ 157 ATS_DATC_FrPsTempSetF "Àü¼® Á¶¼ö¼® Ãø ¼³Á¤¿Âµµ°ª(È­¾¾) ¼³Á¤";
BA_ "GenSigSendType" SG_ 157 ATS_DATC_FrPsTempSetF 4;
BA_ "GenSigStartValue" SG_ 157 ATS_DATC_FrPsTempSetF 255;
BA_ "UserSigValidity" SG_ 157 ATS_DATC_FrPsTempSetF 3;
BA_REL_ "GenSigTimeoutTime" BU_SG_REL_ CGW_CCU SG_ 157 ATS_DATC_FrPsTempSetF 0;
BA_ "Version" SG_ 157 ATS_DATC_FrPsTempSetF "19.12.08";
BA_ "Description" SG_ 157 ATS_DATC_FrDrTempSetF "Àü¼® ¿îÀü¼® Ãø ¼³Á¤¿Âµµ°ª(È­¾¾) ¼³Á¤";
BA_ "GenSigSendType" SG_ 157 ATS_DATC_FrDrTempSetF 4;
BA_ "GenSigStartValue" SG_ 157 ATS_DATC_FrDrTempSetF 255;
BA_ "UserSigValidity" SG_ 157 ATS_DATC_FrDrTempSetF 3;
BA_REL_ "GenSigTimeoutTime" BU_SG_REL_ CGW_CCU SG_ 157 ATS_DATC_FrDrTempSetF 0;
BA_ "Version" SG_ 157 ATS_DATC_FrDrTempSetF "19.12.08";
BA_ "GenMsgCycleTime" BO_ 171 0;
BA_ "Description" SG_ 171 BLTN_CAM_UI_Mode_Tmt_Req "Built-in Cam UI Mode terminate request.";
BA_ "GenSigSendType" SG_ 171 BLTN_CAM_UI_Mode_Tmt_Req 4;
BA_ "UserSigValidity" SG_ 171 BLTN_CAM_UI_Mode_Tmt_Req 1;
BA_REL_ "GenSigTimeoutTime" BU_SG_REL_ CGW_CCU SG_ 171 BLTN_CAM_UI_Mode_Tmt_Req 0;
BA_ "Version" SG_ 171 BLTN_CAM_UI_Mode_Tmt_Req "21.05.02";
BA_ "Description" SG_ 171 BLTN_CAM_Dis_Touch_BeepSound "Display Touch Beep Sound of valid space touch.";
BA_ "GenSigSendType" SG_ 171 BLTN_CAM_Dis_Touch_BeepSound 4;
BA_ "UserSigValidity" SG_ 171 BLTN_CAM_Dis_Touch_BeepSound 1;
BA_ "Version" SG_ 171 BLTN_CAM_Dis_Touch_BeepSound "21.05.02";
BA_ "Description" SG_ 171 BLTN_CAM_PopUp_Req "Built-in Cam Operating and SD Card related Popup Request on HU Display.";
BA_ "GenSigSendType" SG_ 171 BLTN_CAM_PopUp_Req 4;
BA_ "UserSigValidity" SG_ 171 BLTN_CAM_PopUp_Req 1;
BA_REL_ "GenSigTimeoutTime" BU_SG_REL_ CGW_CCU SG_ 171 BLTN_CAM_PopUp_Req 0;
BA_ "Version" SG_ 171 BLTN_CAM_PopUp_Req "21.11.07";
BA_ "Description" SG_ 171 BLTN_CAM_File_List_Renew "The Storage information is renewed inform to HU.";
BA_ "GenSigSendType" SG_ 171 BLTN_CAM_File_List_Renew 4;
BA_ "UserSigValidity" SG_ 171 BLTN_CAM_File_List_Renew 1;
BA_REL_ "GenSigTimeoutTime" BU_SG_REL_ CGW_CCU SG_ 171 BLTN_CAM_File_List_Renew 0;
BA_ "Version" SG_ 171 BLTN_CAM_File_List_Renew "21.05.02";
BA_ "Description" SG_ 171 BLTN_CAM_Wifi_Pwd_Chg_State "The Response, when HU change Wifi Passowrd via SOME/IP";
BA_ "GenSigSendType" SG_ 171 BLTN_CAM_Wifi_Pwd_Chg_State 4;
BA_ "UserSigValidity" SG_ 171 BLTN_CAM_Wifi_Pwd_Chg_State 1;
BA_REL_ "GenSigTimeoutTime" BU_SG_REL_ CGW_CCU SG_ 171 BLTN_CAM_Wifi_Pwd_Chg_State 0;
BA_ "Version" SG_ 171 BLTN_CAM_Wifi_Pwd_Chg_State "21.05.04";
BA_ "GenMsgCycleTime" BO_ 2323816449 0;
BA_ "VFrameFormat" BO_ 2323816449 1;
BA_ "GenSigSendType" SG_ 2323816449 C_CtrlDrLockRlyCCS_Copy_2 4;
BA_ "UserSigValidity" SG_ 2323816449 C_CtrlDrLockRlyCCS_Copy_2 0;
BA_ "NetworkRequest" SG_ 2323816449 C_CtrlDrLockRlyCCS_Copy_2 0;
BA_ "NetworkRequestHoldingTime" SG_ 2323816449 C_CtrlDrLockRlyCCS_Copy_2 2000;
BA_ "Version" SG_ 2323816449 C_CtrlDrLockRlyCCS_Copy_2 "20.08.07";
BA_ "GenSigSendType" SG_ 2323816449 C_TeleHeatingCmdIBOX_Copy_2 4;
BA_ "GenSigStartValue" SG_ 2323816449 C_TeleHeatingCmdIBOX_Copy_2 3;
BA_ "UserSigValidity" SG_ 2323816449 C_TeleHeatingCmdIBOX_Copy_2 0;
BA_ "NetworkRequest" SG_ 2323816449 C_TeleHeatingCmdIBOX_Copy_2 0;
BA_ "NetworkRequestHoldingTime" SG_ 2323816449 C_TeleHeatingCmdIBOX_Copy_2 2000;
BA_ "Version" SG_ 2323816449 C_TeleHeatingCmdIBOX_Copy_2 "20.08.07";
BA_ "GenSigSendType" SG_ 2323816449 C_TeleStrgWhlHeatingCmdIBOX_Copy_2 4;
BA_ "GenSigStartValue" SG_ 2323816449 C_TeleStrgWhlHeatingCmdIBOX_Copy_2 3;
BA_ "UserSigValidity" SG_ 2323816449 C_TeleStrgWhlHeatingCmdIBOX_Copy_2 0;
BA_ "NetworkRequest" SG_ 2323816449 C_TeleStrgWhlHeatingCmdIBOX_Copy_2 0;
BA_ "NetworkRequestHoldingTime" SG_ 2323816449 C_TeleStrgWhlHeatingCmdIBOX_Copy_2 2000;
BA_ "Version" SG_ 2323816449 C_TeleStrgWhlHeatingCmdIBOX_Copy_2 "20.08.07";
BA_ "GenSigSendType" SG_ 2323816449 C_TeleDefoggerHeatingCmdIBOX_Copy_2 4;
BA_ "GenSigStartValue" SG_ 2323816449 C_TeleDefoggerHeatingCmdIBOX_Copy_2 3;
BA_ "UserSigValidity" SG_ 2323816449 C_TeleDefoggerHeatingCmdIBOX_Copy_2 0;
BA_ "NetworkRequest" SG_ 2323816449 C_TeleDefoggerHeatingCmdIBOX_Copy_2 0;
BA_ "NetworkRequestHoldingTime" SG_ 2323816449 C_TeleDefoggerHeatingCmdIBOX_Copy_2 2000;
BA_ "Version" SG_ 2323816449 C_TeleDefoggerHeatingCmdIBOX_Copy_2 "20.08.07";
BA_ "GenSigSendType" SG_ 2323816449 C_TeleDrvSeatOpCmdIBOX_Copy_2 4;
BA_ "UserSigValidity" SG_ 2323816449 C_TeleDrvSeatOpCmdIBOX_Copy_2 3;
BA_REL_ "GenSigTimeoutTime" BU_SG_REL_ SHVU_FR SG_ 2323816449 C_TeleDrvSeatOpCmdIBOX_Copy_2 0;
BA_REL_ "GenSigTimeoutTime" BU_SG_REL_ DPSU SG_ 2323816449 C_TeleDrvSeatOpCmdIBOX_Copy_2 0;
BA_ "Version" SG_ 2323816449 C_TeleDrvSeatOpCmdIBOX_Copy_2 "20.08.07";
BA_ "GenSigSendType" SG_ 2323816449 C_CtrlDrUnlockRlyCCS_Copy_2 4;
BA_ "UserSigValidity" SG_ 2323816449 C_CtrlDrUnlockRlyCCS_Copy_2 0;
BA_ "NetworkRequest" SG_ 2323816449 C_CtrlDrUnlockRlyCCS_Copy_2 0;
BA_ "NetworkRequestHoldingTime" SG_ 2323816449 C_CtrlDrUnlockRlyCCS_Copy_2 2000;
BA_ "Version" SG_ 2323816449 C_CtrlDrUnlockRlyCCS_Copy_2 "20.08.07";
BA_ "GenSigSendType" SG_ 2323816449 C_TeleAstSeatOpCmdIBOX_Copy_2 4;
BA_ "UserSigValidity" SG_ 2323816449 C_TeleAstSeatOpCmdIBOX_Copy_2 3;
BA_REL_ "GenSigTimeoutTime" BU_SG_REL_ APSU SG_ 2323816449 C_TeleAstSeatOpCmdIBOX_Copy_2 0;
BA_REL_ "GenSigTimeoutTime" BU_SG_REL_ SHVU_FR SG_ 2323816449 C_TeleAstSeatOpCmdIBOX_Copy_2 0;
BA_ "Version" SG_ 2323816449 C_TeleAstSeatOpCmdIBOX_Copy_2 "20.08.07";
BA_ "GenSigSendType" SG_ 2323816449 C_TeleRRSeatOpCmdIBOX_Copy_2 4;
BA_ "UserSigValidity" SG_ 2323816449 C_TeleRRSeatOpCmdIBOX_Copy_2 3;
BA_REL_ "GenSigTimeoutTime" BU_SG_REL_ RRHV SG_ 2323816449 C_TeleRRSeatOpCmdIBOX_Copy_2 0;
BA_REL_ "GenSigTimeoutTime" BU_SG_REL_ SHVU_FR SG_ 2323816449 C_TeleRRSeatOpCmdIBOX_Copy_2 0;
BA_REL_ "GenSigTimeoutTime" BU_SG_REL_ SHVU_RR SG_ 2323816449 C_TeleRRSeatOpCmdIBOX_Copy_2 0;
BA_REL_ "GenSigTimeoutTime" BU_SG_REL_ RRPSU SG_ 2323816449 C_TeleRRSeatOpCmdIBOX_Copy_2 0;
BA_REL_ "GenSigTimeoutTime" BU_SG_REL_ RLPSU SG_ 2323816449 C_TeleRRSeatOpCmdIBOX_Copy_2 0;
BA_REL_ "GenSigTimeoutTime" BU_SG_REL_ ATS SG_ 2323816449 C_TeleRRSeatOpCmdIBOX_Copy_2 0;
BA_ "Version" SG_ 2323816449 C_TeleRRSeatOpCmdIBOX_Copy_2 "20.08.07";
BA_ "GenSigSendType" SG_ 2323816449 C_TeleRLSeatOpCmdIBOX_Copy_1 4;
BA_ "UserSigValidity" SG_ 2323816449 C_TeleRLSeatOpCmdIBOX_Copy_1 3;
BA_REL_ "GenSigTimeoutTime" BU_SG_REL_ RLHV SG_ 2323816449 C_TeleRLSeatOpCmdIBOX_Copy_1 0;
BA_REL_ "GenSigTimeoutTime" BU_SG_REL_ SHVU_FR SG_ 2323816449 C_TeleRLSeatOpCmdIBOX_Copy_1 0;
BA_REL_ "GenSigTimeoutTime" BU_SG_REL_ SHVU_RR SG_ 2323816449 C_TeleRLSeatOpCmdIBOX_Copy_1 0;
BA_REL_ "GenSigTimeoutTime" BU_SG_REL_ RRPSU SG_ 2323816449 C_TeleRLSeatOpCmdIBOX_Copy_1 0;
BA_REL_ "GenSigTimeoutTime" BU_SG_REL_ RLPSU SG_ 2323816449 C_TeleRLSeatOpCmdIBOX_Copy_1 0;
BA_REL_ "GenSigTimeoutTime" BU_SG_REL_ ATS SG_ 2323816449 C_TeleRLSeatOpCmdIBOX_Copy_1 0;
BA_ "Version" SG_ 2323816449 C_TeleRLSeatOpCmdIBOX_Copy_1 "20.08.07";
BA_ "GenSigSendType" SG_ 2323816449 C_BlindCmdAVN_Copy_2 4;
BA_ "GenSigStartValue" SG_ 2323816449 C_BlindCmdAVN_Copy_2 7;
BA_ "UserSigValidity" SG_ 2323816449 C_BlindCmdAVN_Copy_2 1;
BA_ "Version" SG_ 2323816449 C_BlindCmdAVN_Copy_2 "20.08.07";
BA_ "GenSigSendType" SG_ 2323816449 C_GlassCmdAVN_Copy_2 4;
BA_ "GenSigStartValue" SG_ 2323816449 C_GlassCmdAVN_Copy_2 7;
BA_ "UserSigValidity" SG_ 2323816449 C_GlassCmdAVN_Copy_2 1;
BA_ "Version" SG_ 2323816449 C_GlassCmdAVN_Copy_2 "20.08.07";
BA_ "GenSigSendType" SG_ 2323816449 C_DrvWindowCmdAVN_Copy_2 4;
BA_ "GenSigStartValue" SG_ 2323816449 C_DrvWindowCmdAVN_Copy_2 15;
BA_ "UserSigValidity" SG_ 2323816449 C_DrvWindowCmdAVN_Copy_2 0;
BA_ "Version" SG_ 2323816449 C_DrvWindowCmdAVN_Copy_2 "20.08.07";
BA_ "GenSigSendType" SG_ 2323816449 C_HazardFromCCS_Copy_2 4;
BA_ "UserSigValidity" SG_ 2323816449 C_HazardFromCCS_Copy_2 0;
BA_ "NetworkRequest" SG_ 2323816449 C_HazardFromCCS_Copy_2 0;
BA_ "NetworkRequestHoldingTime" SG_ 2323816449 C_HazardFromCCS_Copy_2 2000;
BA_ "Version" SG_ 2323816449 C_HazardFromCCS_Copy_2 "20.08.07";
BA_ "GenSigSendType" SG_ 2323816449 C_AstWindowCmdAVN_Copy_2 4;
BA_ "GenSigStartValue" SG_ 2323816449 C_AstWindowCmdAVN_Copy_2 15;
BA_ "UserSigValidity" SG_ 2323816449 C_AstWindowCmdAVN_Copy_2 0;
BA_ "Version" SG_ 2323816449 C_AstWindowCmdAVN_Copy_2 "20.08.07";
BA_ "GenSigSendType" SG_ 2323816449 C_RRWindowCmdAVN_Copy_2 4;
BA_ "GenSigStartValue" SG_ 2323816449 C_RRWindowCmdAVN_Copy_2 15;
BA_ "UserSigValidity" SG_ 2323816449 C_RRWindowCmdAVN_Copy_2 0;
BA_ "Version" SG_ 2323816449 C_RRWindowCmdAVN_Copy_2 "20.08.07";
BA_ "GenSigSendType" SG_ 2323816449 C_RLWindowCmdAVN_Copy_2 4;
BA_ "GenSigStartValue" SG_ 2323816449 C_RLWindowCmdAVN_Copy_2 15;
BA_ "UserSigValidity" SG_ 2323816449 C_RLWindowCmdAVN_Copy_2 0;
BA_ "Version" SG_ 2323816449 C_RLWindowCmdAVN_Copy_2 "20.08.07";
BA_ "Description" SG_ 2323816449 TailCtrlReq_Copy "This signal is for cotroling Tail lamp.";
BA_ "GenSigSendType" SG_ 2323816449 TailCtrlReq_Copy 4;
BA_ "UserSigValidity" SG_ 2323816449 TailCtrlReq_Copy 0;
BA_ "Version" SG_ 2323816449 TailCtrlReq_Copy "20.08.07";
BA_ "Description" SG_ 2323816449 HazardCtrlReq_Copy "This signal is request for controling Hazard lamp.";
BA_ "GenSigSendType" SG_ 2323816449 HazardCtrlReq_Copy 4;
BA_ "UserSigValidity" SG_ 2323816449 HazardCtrlReq_Copy 0;
BA_ "Version" SG_ 2323816449 HazardCtrlReq_Copy "20.08.07";
BA_ "GenSigSendType" SG_ 2323816449 HU_DATC_AirCleaningSet_Copy_1 4;
BA_ "GenSigStartValue" SG_ 2323816449 HU_DATC_AirCleaningSet_Copy_1 3;
BA_ "UserSigValidity" SG_ 2323816449 HU_DATC_AirCleaningSet_Copy_1 3;
BA_ "Version" SG_ 2323816449 HU_DATC_AirCleaningSet_Copy_1 "20.08.07";
BA_ "GenSigSendType" SG_ 2323816449 C_PanicFromCCS_Copy_2 4;
BA_ "UserSigValidity" SG_ 2323816449 C_PanicFromCCS_Copy_2 0;
BA_ "NetworkRequest" SG_ 2323816449 C_PanicFromCCS_Copy_2 0;
BA_ "NetworkRequestHoldingTime" SG_ 2323816449 C_PanicFromCCS_Copy_2 2000;
BA_ "Version" SG_ 2323816449 C_PanicFromCCS_Copy_2 "20.08.07";
BA_ "Description" SG_ 2323816449 C_TeleFrontHeatingCmdIBOX_Copy_1 "Command for Remote Heating (Front Window)";
BA_ "GenSigSendType" SG_ 2323816449 C_TeleFrontHeatingCmdIBOX_Copy_1 4;
BA_ "GenSigStartValue" SG_ 2323816449 C_TeleFrontHeatingCmdIBOX_Copy_1 3;
BA_ "UserSigValidity" SG_ 2323816449 C_TeleFrontHeatingCmdIBOX_Copy_1 0;
BA_ "NetworkRequest" SG_ 2323816449 C_TeleFrontHeatingCmdIBOX_Copy_1 0;
BA_ "NetworkRequestHoldingTime" SG_ 2323816449 C_TeleFrontHeatingCmdIBOX_Copy_1 2000;
BA_ "Version" SG_ 2323816449 C_TeleFrontHeatingCmdIBOX_Copy_1 "20.08.07";
BA_ "Description" SG_ 2323816449 RAC_AirCleaningCtrlReq_Copy_1 "CCS Module(Telematics unit) transmits this signal to control the air cleaning when the remote air-condition is request.";
BA_ "GenSigSendType" SG_ 2323816449 RAC_AirCleaningCtrlReq_Copy_1 4;
BA_ "UserSigValidity" SG_ 2323816449 RAC_AirCleaningCtrlReq_Copy_1 3;
BA_ "Version" SG_ 2323816449 RAC_AirCleaningCtrlReq_Copy_1 "20.09.00";
BA_ "GenSigSendType" SG_ 2323816449 C_PreCrankReq_Copy 4;
BA_ "UserSigValidity" SG_ 2323816449 C_PreCrankReq_Copy 0;
BA_ "NetworkRequest" SG_ 2323816449 C_PreCrankReq_Copy 0;
BA_ "Version" SG_ 2323816449 C_PreCrankReq_Copy "20.08.07";
BA_ "GenMsgCycleTime" BO_ 2323816450 0;
BA_ "VFrameFormat" BO_ 2323816450 1;
BA_ "Description" SG_ 2323816450 HU_CDMOpenCmd_Copy_1 "Command for CDM open/close";
BA_ "GenSigSendType" SG_ 2323816450 HU_CDMOpenCmd_Copy_1 4;
BA_ "UserSigValidity" SG_ 2323816450 HU_CDMOpenCmd_Copy_1 7;
BA_ "Version" SG_ 2323816450 HU_CDMOpenCmd_Copy_1 "20.09.00";
BA_ "Description" SG_ 2323816450 HU_StrgWhlHeatingSet_CCS_Copy "steering wheel heating control by step1/2";
BA_ "GenSigSendType" SG_ 2323816450 HU_StrgWhlHeatingSet_CCS_Copy 4;
BA_ "GenSigStartValue" SG_ 2323816450 HU_StrgWhlHeatingSet_CCS_Copy 7;
BA_ "UserSigValidity" SG_ 2323816450 HU_StrgWhlHeatingSet_CCS_Copy 0;
BA_ "Version" SG_ 2323816450 HU_StrgWhlHeatingSet_CCS_Copy "21.05.02";
BA_ "GenSigSendType" SG_ 2323816450 C_EsyAcsProfileID_CCU 4;
BA_ "UserSigValidity" SG_ 2323816450 C_EsyAcsProfileID_CCU 0;
BA_REL_ "GenSigTimeoutTime" BU_SG_REL_ DPSU SG_ 2323816450 C_EsyAcsProfileID_CCU 0;
BA_ "Version" SG_ 2323816450 C_EsyAcsProfileID_CCU "20.09.00";
BA_ "GenMsgCycleTime" BO_ 2323816451 0;
BA_ "VFrameFormat" BO_ 2323816451 1;
BA_ "GenMsgCycleTime" BO_ 2323816452 0;
BA_ "VFrameFormat" BO_ 2323816452 1;
BA_ "GenMsgSendType" BO_ 679 0;
BA_ "Description" SG_ 679 CMS_RH_Crc1Val "The data area for CRC calculation is based on the data length (DLC) of the message DB.

The CRC shall be calculated over the entire data block (excluding the CRC bytes) including the user data, alive counter and Data ID 

 

- CRC Polynomial (0x1D) , Initial Value : 0x00, XOR value : 0xFF, Data ID Mode : Both, Data ID : Message ID + 0xF800 

- The initial value is for CRC calculation and the message should be sent with the calculated result value. 

The mathematical expression to 8 bit CRC polynomial is given here. G(x) = x8 + x4 + x3 + x2 + 1";
BA_ "GenSigSendType" SG_ 679 CMS_RH_Crc1Val 4;
BA_ "GenSigStartValue" SG_ 679 CMS_RH_Crc1Val 255;
BA_ "UserSigValidity" SG_ 679 CMS_RH_Crc1Val 0;
BA_ "RoutingFactor" SG_ 679 CMS_RH_Crc1Val 0;
BA_ "Version" SG_ 679 CMS_RH_Crc1Val "19.09.06";
BA_ "Description" SG_ 679 CMS_RH_AlvCnt1Val "For the first transmission request for a data element the counter shall be initialized with 0 and shall be incremented by 1

for every subsequent send request. When the counter reaches the maximum value(0xE), then it shall restart with 0 for the next send request";
BA_ "GenSigSendType" SG_ 679 CMS_RH_AlvCnt1Val 4;
BA_ "UserSigValidity" SG_ 679 CMS_RH_AlvCnt1Val 0;
BA_ "RoutingFactor" SG_ 679 CMS_RH_AlvCnt1Val 0;
BA_ "Version" SG_ 679 CMS_RH_AlvCnt1Val "19.09.06";
BA_ "GenSigSendType" SG_ 679 USM_CMSDayBrgtnsLvlRHSta 4;
BA_ "GenSigStartValue" SG_ 679 USM_CMSDayBrgtnsLvlRHSta 5;
BA_ "UserSigValidity" SG_ 679 USM_CMSDayBrgtnsLvlRHSta 0;
BA_ "NetworkRequest" SG_ 679 USM_CMSDayBrgtnsLvlRHSta 0;
BA_ "NetworkRequestHoldingTime" SG_ 679 USM_CMSDayBrgtnsLvlRHSta 5;
BA_ "RoutingFactor" SG_ 679 USM_CMSDayBrgtnsLvlRHSta 0;
BA_ "Version" SG_ 679 USM_CMSDayBrgtnsLvlRHSta "19.12.00";
BA_ "GenSigSendType" SG_ 679 USM_CMSNgtBrgtnsLvlRHSta 4;
BA_ "GenSigStartValue" SG_ 679 USM_CMSNgtBrgtnsLvlRHSta 5;
BA_ "UserSigValidity" SG_ 679 USM_CMSNgtBrgtnsLvlRHSta 0;
BA_ "NetworkRequest" SG_ 679 USM_CMSNgtBrgtnsLvlRHSta 0;
BA_ "NetworkRequestHoldingTime" SG_ 679 USM_CMSNgtBrgtnsLvlRHSta 5;
BA_ "RoutingFactor" SG_ 679 USM_CMSNgtBrgtnsLvlRHSta 0;
BA_ "Version" SG_ 679 USM_CMSNgtBrgtnsLvlRHSta "19.12.00";
BA_ "GenSigSendType" SG_ 679 IMS_CMSPlayBackSta_RH 4;
BA_ "UserSigValidity" SG_ 679 IMS_CMSPlayBackSta_RH 0;
BA_REL_ "GenSigTimeoutTime" BU_SG_REL_ DPSU SG_ 679 IMS_CMSPlayBackSta_RH 1500;
BA_ "NetworkRequest" SG_ 679 IMS_CMSPlayBackSta_RH 0;
BA_ "NetworkRequestHoldingTime" SG_ 679 IMS_CMSPlayBackSta_RH 5;
BA_ "RoutingFactor" SG_ 679 IMS_CMSPlayBackSta_RH 0;
BA_ "Version" SG_ 679 IMS_CMSPlayBackSta_RH "20.08.07";
BA_ "GenSigSendType" SG_ 679 MonitorStatus 4;
BA_ "UserSigValidity" SG_ 679 MonitorStatus 0;
BA_ "NetworkRequest" SG_ 679 MonitorStatus 0;
BA_ "NetworkRequestHoldingTime" SG_ 679 MonitorStatus 5;
BA_ "RoutingFactor" SG_ 679 MonitorStatus 0;
BA_ "Version" SG_ 679 MonitorStatus "20.04.06";
BA_ "GenSigSendType" SG_ 679 CMS_RH_FoldingSta 4;
BA_ "UserSigValidity" SG_ 679 CMS_RH_FoldingSta 0;
BA_ "NetworkRequest" SG_ 679 CMS_RH_FoldingSta 0;
BA_ "NetworkRequestHoldingTime" SG_ 679 CMS_RH_FoldingSta 5000;
BA_ "RoutingFactor" SG_ 679 CMS_RH_FoldingSta 0;
BA_ "Version" SG_ 679 CMS_RH_FoldingSta "20.11.04";
BA_ "GenSigSendType" SG_ 679 CMS_RH_UnfoldingSta 4;
BA_ "UserSigValidity" SG_ 679 CMS_RH_UnfoldingSta 0;
BA_ "NetworkRequest" SG_ 679 CMS_RH_UnfoldingSta 0;
BA_ "NetworkRequestHoldingTime" SG_ 679 CMS_RH_UnfoldingSta 5000;
BA_ "RoutingFactor" SG_ 679 CMS_RH_UnfoldingSta 0;
BA_ "Version" SG_ 679 CMS_RH_UnfoldingSta "20.11.04";
BA_ "Description" SG_ 679 CMS_RHVerPosVal "This signal indicates RH Outside Mirror Vertical Position Sensor Voltage";
BA_ "GenSigSendType" SG_ 679 CMS_RHVerPosVal 4;
BA_ "UserSigValidity" SG_ 679 CMS_RHVerPosVal 0;
BA_ "NetworkRequest" SG_ 679 CMS_RHVerPosVal 0;
BA_ "NetworkRequestHoldingTime" SG_ 679 CMS_RHVerPosVal 5000;
BA_ "RoutingFactor" SG_ 679 CMS_RHVerPosVal 0;
BA_ "Version" SG_ 679 CMS_RHVerPosVal "20.08.07";
BA_ "Description" SG_ 679 CMS_RHHorPosVal "This signal indicates RH Outside Mirror Horizontal Position Sensor Voltage";
BA_ "GenSigSendType" SG_ 679 CMS_RHHorPosVal 4;
BA_ "UserSigValidity" SG_ 679 CMS_RHHorPosVal 0;
BA_ "NetworkRequest" SG_ 679 CMS_RHHorPosVal 0;
BA_ "NetworkRequestHoldingTime" SG_ 679 CMS_RHHorPosVal 5000;
BA_ "RoutingFactor" SG_ 679 CMS_RHHorPosVal 0;
BA_ "Version" SG_ 679 CMS_RHHorPosVal "20.08.07";
BA_ "GenMsgSendType" BO_ 2382594561 0;
BA_ "VFrameFormat" BO_ 2382594561 1;
BA_ "Description" SG_ 2382594561 DATC_Crc5Val "The data area for CRC calculation is based on the data length (DLC) of the message DB.

The CRC shall be calculated over the entire data block (excluding the CRC bytes) including the user data, alive counter and Data ID

 

- CRC Polynomial (0x1021) , Initial Value : 0xFFFF, XOR value : 0x0000, Data ID : Message ID + 0xF800 

- The initial value is for CRC calculation and the message should be sent with the calculated result value. 

- The mathematical expression to 16 bit CRC polynomial is given here. G(x) = x16 + x12 + x5 + 1";
BA_ "GenSigSendType" SG_ 2382594561 DATC_Crc5Val 4;
BA_ "GenSigStartValue" SG_ 2382594561 DATC_Crc5Val 65535;
BA_ "UserSigValidity" SG_ 2382594561 DATC_Crc5Val 3;
BA_ "Version" SG_ 2382594561 DATC_Crc5Val "18.11.08";
BA_ "Description" SG_ 2382594561 DATC_AlvCnt5Val "For the first transmission request for a data element the counter shall be initialized with 0 and shall be incremented by 1 for every subsequent send request. 

When the counter reaches the maximum value(0xFF), then it shall restart with 0 for the next send request";
BA_ "GenSigSendType" SG_ 2382594561 DATC_AlvCnt5Val 4;
BA_ "UserSigValidity" SG_ 2382594561 DATC_AlvCnt5Val 3;
BA_ "Version" SG_ 2382594561 DATC_AlvCnt5Val "18.11.08";
BA_ "Description" SG_ 2382594561 DATC_FrDrvModDis "This signal indicates MODE of HTR Control (VENT, B/L, FLOOR, MIX, DEF, AUTO Defog).

This signal occurs when MODE switch(button) is selected either manually or automatically.";
BA_ "GenSigSendType" SG_ 2382594561 DATC_FrDrvModDis 4;
BA_ "UserSigValidity" SG_ 2382594561 DATC_FrDrvModDis 7;
BA_REL_ "GenSigTimeoutTime" BU_SG_REL_ ATS SG_ 2382594561 DATC_FrDrvModDis 1500;
BA_ "Version" SG_ 2382594561 DATC_FrDrvModDis "18.11.06";
BA_ "Description" SG_ 2382594561 DATC_FrPassModDis "This signal indicates Passenger MODE of HTR Control

 (VENT, B/L, FLOOR, MIX, DEF, AUTO Defog)

This signal occurs when MODE switch(button) is selected either manually or automatically";
BA_ "GenSigSendType" SG_ 2382594561 DATC_FrPassModDis 4;
BA_ "UserSigValidity" SG_ 2382594561 DATC_FrPassModDis 7;
BA_REL_ "GenSigTimeoutTime" BU_SG_REL_ ATS SG_ 2382594561 DATC_FrPassModDis 1500;
BA_ "Version" SG_ 2382594561 DATC_FrPassModDis "18.11.05";
BA_ "Description" SG_ 2382594561 DATC_ClmtTxtPopupOSD "Climate Text Pop-up OSD";
BA_ "GenSigSendType" SG_ 2382594561 DATC_ClmtTxtPopupOSD 4;
BA_ "TimeoutValue" SG_ 2382594561 DATC_ClmtTxtPopupOSD "0x0";
BA_ "UserSigValidity" SG_ 2382594561 DATC_ClmtTxtPopupOSD 7;
BA_REL_ "GenSigTimeoutTime" BU_SG_REL_ ATS SG_ 2382594561 DATC_ClmtTxtPopupOSD 1500;
BA_ "Version" SG_ 2382594561 DATC_ClmtTxtPopupOSD "21.04.10";
BA_ "Description" SG_ 2382594561 DATC_TempDispUnitSta "This signal indicates Temp unit of HTR Control (¡É, ¢µ).";
BA_ "GenSigSendType" SG_ 2382594561 DATC_TempDispUnitSta 4;
BA_ "UserSigValidity" SG_ 2382594561 DATC_TempDispUnitSta 6;
BA_REL_ "GenSigTimeoutTime" BU_SG_REL_ ATS SG_ 2382594561 DATC_TempDispUnitSta 1500;
BA_ "Version" SG_ 2382594561 DATC_TempDispUnitSta "17.11.00";
BA_ "Description" SG_ 2382594561 DATC_DrvAutoDis "This signal indicates AUTO Graphic On & Off.

This signal occurs when AUTO switch(button) is selected either manually or automatically.";
BA_ "GenSigSendType" SG_ 2382594561 DATC_DrvAutoDis 4;
BA_ "UserSigValidity" SG_ 2382594561 DATC_DrvAutoDis 6;
BA_REL_ "GenSigTimeoutTime" BU_SG_REL_ ATS SG_ 2382594561 DATC_DrvAutoDis 1500;
BA_ "Version" SG_ 2382594561 DATC_DrvAutoDis "17.11.00";
BA_ "Description" SG_ 2382594561 DATC_FrChgReqDis "This signal indicates to show Climate Pop-up screen.

This signal occurs when any kinds of climate switch(button)s are selected manually.";
BA_ "GenSigSendType" SG_ 2382594561 DATC_FrChgReqDis 4;
BA_ "UserSigValidity" SG_ 2382594561 DATC_FrChgReqDis 6;
BA_ "Version" SG_ 2382594561 DATC_FrChgReqDis "17.11.00";
BA_ "Description" SG_ 2382594561 DATC_FrClmtScrnDis "This signal indicates that screen change to Climate Full screen.



This signal occurs when Climate switch(button) is selected manually.";
BA_ "GenSigSendType" SG_ 2382594561 DATC_FrClmtScrnDis 4;
BA_ "UserSigValidity" SG_ 2382594561 DATC_FrClmtScrnDis 6;
BA_REL_ "GenSigTimeoutTime" BU_SG_REL_ ATS SG_ 2382594561 DATC_FrClmtScrnDis 1500;
BA_ "Version" SG_ 2382594561 DATC_FrClmtScrnDis "17.11.00";
BA_ "Description" SG_ 2382594561 DATC_AcDis "This signal indicates A/C Graphic On & Off.

This signal occurs when A/C switch(button) is selected either manually or automatically.";
BA_ "GenSigSendType" SG_ 2382594561 DATC_AcDis 4;
BA_ "UserSigValidity" SG_ 2382594561 DATC_AcDis 6;
BA_REL_ "GenSigTimeoutTime" BU_SG_REL_ ATS SG_ 2382594561 DATC_AcDis 1500;
BA_ "Version" SG_ 2382594561 DATC_AcDis "17.11.00";
BA_ "Description" SG_ 2382594561 DATC_IntakeSta "This signal indicates Intake status (REC or FRE).";
BA_ "GenSigSendType" SG_ 2382594561 DATC_IntakeSta 4;
BA_ "UserSigValidity" SG_ 2382594561 DATC_IntakeSta 7;
BA_ "Version" SG_ 2382594561 DATC_IntakeSta "17.11.00";
BA_ "Description" SG_ 2382594561 DATC_TempDrLvl "This signal indicates level of temp door.";
BA_ "GenSigSendType" SG_ 2382594561 DATC_TempDrLvl 4;
BA_ "UserSigValidity" SG_ 2382594561 DATC_TempDrLvl 3;
BA_ "Version" SG_ 2382594561 DATC_TempDrLvl "18.09.00";
BA_ "Description" SG_ 2382594561 DATC_BattCompPwrCnsmptn_W "This signal indicates consumption power by e-compressor for battery";
BA_ "GenSigSendType" SG_ 2382594561 DATC_BattCompPwrCnsmptn_W 4;
BA_ "UserSigValidity" SG_ 2382594561 DATC_BattCompPwrCnsmptn_W 5;
BA_ "Version" SG_ 2382594561 DATC_BattCompPwrCnsmptn_W "18.09.00";
BA_ "GenMsgSendType" BO_ 2424580353 0;
BA_ "VFrameFormat" BO_ 2424580353 1;
BA_ "Description" SG_ 2424580353 DATC_Crc12Val "The data area for CRC calculation is based on the data length (DLC) of the message DB.

The CRC shall be calculated over the entire data block (excluding the CRC bytes) including the user data, alive counter and Data ID

 

- CRC Polynomial (0x1021) , Initial Value : 0xFFFF, XOR value : 0x0000, Data ID : Message ID + 0xF800 

- The initial value is for CRC calculation and the message should be sent with the calculated result value. 

- The mathematical expression to 16 bit CRC polynomial is given here. G(x) = x16 + x12 + x5 + 1";
BA_ "GenSigSendType" SG_ 2424580353 DATC_Crc12Val 4;
BA_ "GenSigStartValue" SG_ 2424580353 DATC_Crc12Val 65535;
BA_ "UserSigValidity" SG_ 2424580353 DATC_Crc12Val 3;
BA_ "Version" SG_ 2424580353 DATC_Crc12Val "18.11.08";
BA_ "Description" SG_ 2424580353 DATC_AlvCnt12Val "For the first transmission request for a data element the counter shall be initialized with 0 and shall be incremented by 1 for every subsequent send request. 

When the counter reaches the maximum value(0xFF), then it shall restart with 0 for the next send request";
BA_ "GenSigSendType" SG_ 2424580353 DATC_AlvCnt12Val 4;
BA_ "UserSigValidity" SG_ 2424580353 DATC_AlvCnt12Val 3;
BA_ "Version" SG_ 2424580353 DATC_AlvCnt12Val "18.11.08";
BA_ "Description" SG_ 2424580353 DATC_StrWhlHtrSwReq "Steering Wheel heater S/W";
BA_ "GenSigSendType" SG_ 2424580353 DATC_StrWhlHtrSwReq 4;
BA_ "UserSigValidity" SG_ 2424580353 DATC_StrWhlHtrSwReq 7;
BA_ "Version" SG_ 2424580353 DATC_StrWhlHtrSwReq "17.11.00";
BA_ "Description" SG_ 2424580353 DATC_FRStHtrSwReq "Front Right Seat heater S/W";
BA_ "GenSigSendType" SG_ 2424580353 DATC_FRStHtrSwReq 4;
BA_ "UserSigValidity" SG_ 2424580353 DATC_FRStHtrSwReq 7;
BA_REL_ "GenSigTimeoutTime" BU_SG_REL_ APSU SG_ 2424580353 DATC_FRStHtrSwReq 1500;
BA_REL_ "GenSigTimeoutTime" BU_SG_REL_ SHVU_FR SG_ 2424580353 DATC_FRStHtrSwReq 1500;
BA_REL_ "GenSigTimeoutTime" BU_SG_REL_ SHVU_RR SG_ 2424580353 DATC_FRStHtrSwReq 1500;
BA_REL_ "GenSigTimeoutTime" BU_SG_REL_ DPSU SG_ 2424580353 DATC_FRStHtrSwReq 1500;
BA_ "Version" SG_ 2424580353 DATC_FRStHtrSwReq "17.11.00";
BA_ "Description" SG_ 2424580353 DATC_FRStVentSwReq "Front Right Seat cooler S/W";
BA_ "GenSigSendType" SG_ 2424580353 DATC_FRStVentSwReq 4;
BA_ "UserSigValidity" SG_ 2424580353 DATC_FRStVentSwReq 7;
BA_REL_ "GenSigTimeoutTime" BU_SG_REL_ APSU SG_ 2424580353 DATC_FRStVentSwReq 1500;
BA_REL_ "GenSigTimeoutTime" BU_SG_REL_ SHVU_FR SG_ 2424580353 DATC_FRStVentSwReq 1500;
BA_REL_ "GenSigTimeoutTime" BU_SG_REL_ SHVU_RR SG_ 2424580353 DATC_FRStVentSwReq 1500;
BA_REL_ "GenSigTimeoutTime" BU_SG_REL_ DPSU SG_ 2424580353 DATC_FRStVentSwReq 1500;
BA_ "Version" SG_ 2424580353 DATC_FRStVentSwReq "17.11.00";
BA_ "Description" SG_ 2424580353 DATC_RrDefSw "Rear Defog Switch";
BA_ "GenSigSendType" SG_ 2424580353 DATC_RrDefSw 4;
BA_ "UserSigValidity" SG_ 2424580353 DATC_RrDefSw 3;
BA_ "Version" SG_ 2424580353 DATC_RrDefSw "19.04.06";
BA_ "Description" SG_ 2424580353 DATC_FLStOpReq "Left Seat warmer / Ventilation Operation request";
BA_ "GenSigSendType" SG_ 2424580353 DATC_FLStOpReq 4;
BA_ "UserSigValidity" SG_ 2424580353 DATC_FLStOpReq 7;
BA_REL_ "GenSigTimeoutTime" BU_SG_REL_ APSU SG_ 2424580353 DATC_FLStOpReq 1500;
BA_REL_ "GenSigTimeoutTime" BU_SG_REL_ SHVU_FR SG_ 2424580353 DATC_FLStOpReq 1500;
BA_REL_ "GenSigTimeoutTime" BU_SG_REL_ SHVU_RR SG_ 2424580353 DATC_FLStOpReq 1500;
BA_REL_ "GenSigTimeoutTime" BU_SG_REL_ DPSU SG_ 2424580353 DATC_FLStOpReq 1500;
BA_ "Version" SG_ 2424580353 DATC_FLStOpReq "17.11.00";
BA_ "Description" SG_ 2424580353 DATC_FRStOpReq "Right Seat Warmer / Ventilation Operation request";
BA_ "GenSigSendType" SG_ 2424580353 DATC_FRStOpReq 4;
BA_ "UserSigValidity" SG_ 2424580353 DATC_FRStOpReq 7;
BA_REL_ "GenSigTimeoutTime" BU_SG_REL_ APSU SG_ 2424580353 DATC_FRStOpReq 1500;
BA_REL_ "GenSigTimeoutTime" BU_SG_REL_ SHVU_FR SG_ 2424580353 DATC_FRStOpReq 1500;
BA_REL_ "GenSigTimeoutTime" BU_SG_REL_ SHVU_RR SG_ 2424580353 DATC_FRStOpReq 1500;
BA_ "Version" SG_ 2424580353 DATC_FRStOpReq "17.11.00";
BA_ "Description" SG_ 2424580353 DATC_FLStHtrSwReq "Front Left Seat heater S/W";
BA_ "GenSigSendType" SG_ 2424580353 DATC_FLStHtrSwReq 4;
BA_ "UserSigValidity" SG_ 2424580353 DATC_FLStHtrSwReq 7;
BA_REL_ "GenSigTimeoutTime" BU_SG_REL_ APSU SG_ 2424580353 DATC_FLStHtrSwReq 1500;
BA_REL_ "GenSigTimeoutTime" BU_SG_REL_ SHVU_FR SG_ 2424580353 DATC_FLStHtrSwReq 1500;
BA_REL_ "GenSigTimeoutTime" BU_SG_REL_ SHVU_RR SG_ 2424580353 DATC_FLStHtrSwReq 1500;
BA_REL_ "GenSigTimeoutTime" BU_SG_REL_ DPSU SG_ 2424580353 DATC_FLStHtrSwReq 1500;
BA_ "Version" SG_ 2424580353 DATC_FLStHtrSwReq "17.11.00";
BA_ "Description" SG_ 2424580353 DATC_FLStVentSwReq "Front Left Seat cooler S/W";
BA_ "GenSigSendType" SG_ 2424580353 DATC_FLStVentSwReq 4;
BA_ "UserSigValidity" SG_ 2424580353 DATC_FLStVentSwReq 7;
BA_REL_ "GenSigTimeoutTime" BU_SG_REL_ APSU SG_ 2424580353 DATC_FLStVentSwReq 1500;
BA_REL_ "GenSigTimeoutTime" BU_SG_REL_ SHVU_FR SG_ 2424580353 DATC_FLStVentSwReq 1500;
BA_REL_ "GenSigTimeoutTime" BU_SG_REL_ SHVU_RR SG_ 2424580353 DATC_FLStVentSwReq 1500;
BA_REL_ "GenSigTimeoutTime" BU_SG_REL_ DPSU SG_ 2424580353 DATC_FLStVentSwReq 1500;
BA_ "Version" SG_ 2424580353 DATC_FLStVentSwReq "17.11.00";
BA_ "Description" SG_ 2424580353 DATC_FLStTmblrSwReq "Front Left Seat cooler S/W";
BA_ "GenSigSendType" SG_ 2424580353 DATC_FLStTmblrSwReq 4;
BA_ "UserSigValidity" SG_ 2424580353 DATC_FLStTmblrSwReq 3;
BA_REL_ "GenSigTimeoutTime" BU_SG_REL_ APSU SG_ 2424580353 DATC_FLStTmblrSwReq 1500;
BA_REL_ "GenSigTimeoutTime" BU_SG_REL_ SHVU_FR SG_ 2424580353 DATC_FLStTmblrSwReq 1500;
BA_ "Version" SG_ 2424580353 DATC_FLStTmblrSwReq "18.01.07";
BA_ "Description" SG_ 2424580353 DATC_FRStTmblrSwReq "Front Left Seat cooler S/W";
BA_ "GenSigSendType" SG_ 2424580353 DATC_FRStTmblrSwReq 4;
BA_ "UserSigValidity" SG_ 2424580353 DATC_FRStTmblrSwReq 3;
BA_REL_ "GenSigTimeoutTime" BU_SG_REL_ APSU SG_ 2424580353 DATC_FRStTmblrSwReq 1500;
BA_REL_ "GenSigTimeoutTime" BU_SG_REL_ SHVU_FR SG_ 2424580353 DATC_FRStTmblrSwReq 1500;
BA_ "Version" SG_ 2424580353 DATC_FRStTmblrSwReq "18.01.07";
BA_ "Description" SG_ 2424580353 DATC_RRStHtrSwReq "This signal indicate DATC Rear Right Seat Heater Switch Request";
BA_ "GenSigSendType" SG_ 2424580353 DATC_RRStHtrSwReq 4;
BA_ "UserSigValidity" SG_ 2424580353 DATC_RRStHtrSwReq 7;
BA_REL_ "GenSigTimeoutTime" BU_SG_REL_ RRHV SG_ 2424580353 DATC_RRStHtrSwReq 1500;
BA_REL_ "GenSigTimeoutTime" BU_SG_REL_ SHVU_FR SG_ 2424580353 DATC_RRStHtrSwReq 1500;
BA_REL_ "GenSigTimeoutTime" BU_SG_REL_ SHVU_RR SG_ 2424580353 DATC_RRStHtrSwReq 1500;
BA_REL_ "GenSigTimeoutTime" BU_SG_REL_ RRPSU SG_ 2424580353 DATC_RRStHtrSwReq 1500;
BA_REL_ "GenSigTimeoutTime" BU_SG_REL_ RLPSU SG_ 2424580353 DATC_RRStHtrSwReq 1500;
BA_ "Version" SG_ 2424580353 DATC_RRStHtrSwReq "18.03.05";
BA_ "Description" SG_ 2424580353 DATC_RRStVentSwReq "This signal indicates DATC Rear Right Seat Ventilation Switch Request";
BA_ "GenSigSendType" SG_ 2424580353 DATC_RRStVentSwReq 4;
BA_ "UserSigValidity" SG_ 2424580353 DATC_RRStVentSwReq 7;
BA_REL_ "GenSigTimeoutTime" BU_SG_REL_ RRHV SG_ 2424580353 DATC_RRStVentSwReq 1500;
BA_REL_ "GenSigTimeoutTime" BU_SG_REL_ SHVU_FR SG_ 2424580353 DATC_RRStVentSwReq 1500;
BA_REL_ "GenSigTimeoutTime" BU_SG_REL_ SHVU_RR SG_ 2424580353 DATC_RRStVentSwReq 1500;
BA_REL_ "GenSigTimeoutTime" BU_SG_REL_ RRPSU SG_ 2424580353 DATC_RRStVentSwReq 1500;
BA_REL_ "GenSigTimeoutTime" BU_SG_REL_ RLPSU SG_ 2424580353 DATC_RRStVentSwReq 1500;
BA_ "Version" SG_ 2424580353 DATC_RRStVentSwReq "18.03.05";
BA_ "Description" SG_ 2424580353 DATC_RLStHtrSwReq "This signal indicates DATC Rear Left Seat Heater Switch Request";
BA_ "GenSigSendType" SG_ 2424580353 DATC_RLStHtrSwReq 4;
BA_ "UserSigValidity" SG_ 2424580353 DATC_RLStHtrSwReq 7;
BA_REL_ "GenSigTimeoutTime" BU_SG_REL_ RLHV SG_ 2424580353 DATC_RLStHtrSwReq 1500;
BA_REL_ "GenSigTimeoutTime" BU_SG_REL_ SHVU_FR SG_ 2424580353 DATC_RLStHtrSwReq 1500;
BA_REL_ "GenSigTimeoutTime" BU_SG_REL_ SHVU_RR SG_ 2424580353 DATC_RLStHtrSwReq 1500;
BA_REL_ "GenSigTimeoutTime" BU_SG_REL_ RRPSU SG_ 2424580353 DATC_RLStHtrSwReq 1500;
BA_REL_ "GenSigTimeoutTime" BU_SG_REL_ RLPSU SG_ 2424580353 DATC_RLStHtrSwReq 1500;
BA_ "Version" SG_ 2424580353 DATC_RLStHtrSwReq "19.06.00";
BA_ "Description" SG_ 2424580353 DATC_RLStVentSwReq "This signal indicates DATC Rear Left Seat Ventilation Switch Request";
BA_ "GenSigSendType" SG_ 2424580353 DATC_RLStVentSwReq 4;
BA_ "UserSigValidity" SG_ 2424580353 DATC_RLStVentSwReq 7;
BA_REL_ "GenSigTimeoutTime" BU_SG_REL_ RLHV SG_ 2424580353 DATC_RLStVentSwReq 1500;
BA_REL_ "GenSigTimeoutTime" BU_SG_REL_ SHVU_FR SG_ 2424580353 DATC_RLStVentSwReq 1500;
BA_REL_ "GenSigTimeoutTime" BU_SG_REL_ SHVU_RR SG_ 2424580353 DATC_RLStVentSwReq 1500;
BA_REL_ "GenSigTimeoutTime" BU_SG_REL_ RRPSU SG_ 2424580353 DATC_RLStVentSwReq 1500;
BA_REL_ "GenSigTimeoutTime" BU_SG_REL_ RLPSU SG_ 2424580353 DATC_RLStVentSwReq 1500;
BA_ "Version" SG_ 2424580353 DATC_RLStVentSwReq "18.03.05";
BA_ "Description" SG_ 2424580353 DATC_FRWndShldHtSW "Front windshield glass heating switch

(Russia / Canada regions applied)";
BA_ "GenSigSendType" SG_ 2424580353 DATC_FRWndShldHtSW 4;
BA_ "UserSigValidity" SG_ 2424580353 DATC_FRWndShldHtSW 3;
BA_ "Version" SG_ 2424580353 DATC_FRWndShldHtSW "19.04.06";
BA_ "Description" SG_ 2424580353 DATC_WhistlelNoise "This signal is to prevent whistle noise from the door glass

(Fresh & Blower more than 4 Step condition)";
BA_ "GenSigSendType" SG_ 2424580353 DATC_WhistlelNoise 4;
BA_ "UserSigValidity" SG_ 2424580353 DATC_WhistlelNoise 3;
BA_ "Version" SG_ 2424580353 DATC_WhistlelNoise "19.04.06";
BA_ "Description" SG_ 2424580353 DATC_WdwClsReq "This signal indicates Window Close Request.

(This signal is used for Closing Control of Window when AirClean Switch is selecting)";
BA_ "GenSigSendType" SG_ 2424580353 DATC_WdwClsReq 4;
BA_ "UserSigValidity" SG_ 2424580353 DATC_WdwClsReq 7;
BA_ "Version" SG_ 2424580353 DATC_WdwClsReq "19.07.06";
BA_ "Description" SG_ 2424580353 DATC_RRSyncDis "This signal indicates SYNC Graphic On & Off.

This signal occurs when Rear SYNC switch(button) is selected either manually or automatically.";
BA_ "GenSigSendType" SG_ 2424580353 DATC_RRSyncDis 4;
BA_ "UserSigValidity" SG_ 2424580353 DATC_RRSyncDis 7;
BA_REL_ "GenSigTimeoutTime" BU_SG_REL_ ATS SG_ 2424580353 DATC_RRSyncDis 1500;
BA_ "Version" SG_ 2424580353 DATC_RRSyncDis "19.12.00";
BA_ "GenMsgSendType" BO_ 2176872449 0;
BA_ "GenMsgCycleTime" BO_ 2176872449 50;
BA_ "GenMsgCycleTimeFast" BO_ 2176872449 0;
BA_ "GenMsgNrOfRepetition" BO_ 2176872449 0;
BA_ "VFrameFormat" BO_ 2176872449 1;
BA_ "Description" SG_ 2176872449 HTCU_Crc5Val "The data area for CRC calculation is based on the data length (DLC) of the message DB.

The CRC shall be calculated over the entire data block (excluding the CRC bytes) including the user data, alive counter and Data ID

 

- CRC Polynomial (0x1021) , Initial Value : 0xFFFF, XOR value : 0x0000, Data ID : Message ID + 0xF800 

- The initial value is for CRC calculation and the message should be sent with the calculated result value. 

- The mathematical expression to 16 bit CRC polynomial is given here. G(x) = x16 + x12 + x5 + 1";
BA_ "GenSigStartValue" SG_ 2176872449 HTCU_Crc5Val 65535;
BA_ "UserSigValidity" SG_ 2176872449 HTCU_Crc5Val 3;
BA_ "RoutingFactor" SG_ 2176872449 HTCU_Crc5Val 5;
BA_ "Version" SG_ 2176872449 HTCU_Crc5Val "19.10.00";
BA_ "Description" SG_ 2176872449 HTCU_AlvCnt5Val "For the first transmission request for a data element the counter shall be initialized with 0 and shall be incremented by 1 for every subsequent send request. 

When the counter reaches the maximum value(0xFF), then it shall restart with 0 for the next send request";
BA_ "UserSigValidity" SG_ 2176872449 HTCU_AlvCnt5Val 3;
BA_ "RoutingFactor" SG_ 2176872449 HTCU_AlvCnt5Val 5;
BA_ "Version" SG_ 2176872449 HTCU_AlvCnt5Val "19.10.00";
BA_ "Description" SG_ 2176872449 HDCT_AddtnlTqLssVal "Additional torque loss";
BA_ "UserSigValidity" SG_ 2176872449 HDCT_AddtnlTqLssVal 3;
BA_ "RoutingFactor" SG_ 2176872449 HDCT_AddtnlTqLssVal 5;
BA_ "Version" SG_ 2176872449 HDCT_AddtnlTqLssVal "19.10.01";
BA_ "Description" SG_ 2176872449 HDCT_OBDSta "The signal HDCT_ObdSta is used to inform the OBD master (EMS-ECU) in case a OBD relevant fault is detected. According to the OBD regulations the HTCU could request MIL on, MIL blinking and freeze frame storage. If a freeze frame request by the HTCU has not been acknowledged (CF_Ems_ObdFrfAck) within 2 seconds, this request has to be canceled.

Value description

Bit 0: readiness info / Bit 1: freeze frame request / Bit 2: MIL on request / Bit3: MIL blinking request";
BA_ "UserSigValidity" SG_ 2176872449 HDCT_OBDSta 3;
BA_ "RoutingFactor" SG_ 2176872449 HDCT_OBDSta 5;
BA_ "Version" SG_ 2176872449 HDCT_OBDSta "19.10.01";
BA_ "Description" SG_ 2176872449 HDCT_OBDErrSta "Informs about the presence of an OBD-relevant error in the HTCU.

When an OBD-relevant error detected HDCT_ObdErrSta is set to 1 and the related DTC(s) would be recorded into non-volatile memory. Even if the error is not detected currently, HDCT_ObdErrSta should be set to 1 as long as DTC exists in memory.";
BA_ "UserSigValidity" SG_ 2176872449 HDCT_OBDErrSta 3;
BA_ "RoutingFactor" SG_ 2176872449 HDCT_OBDErrSta 5;
BA_ "Version" SG_ 2176872449 HDCT_OBDErrSta "19.10.01";
BA_ "Description" SG_ 2176872449 HDCT_StcShftLrchCtrl "Static shift DR or RD lurch control";
BA_ "UserSigValidity" SG_ 2176872449 HDCT_StcShftLrchCtrl 3;
BA_ "RoutingFactor" SG_ 2176872449 HDCT_StcShftLrchCtrl 5;
BA_ "Version" SG_ 2176872449 HDCT_StcShftLrchCtrl "19.10.01";
BA_ "Description" SG_ 2176872449 HDCT_EngCltchLmphmMod "Engine clutch limp-home control activation";
BA_ "UserSigValidity" SG_ 2176872449 HDCT_EngCltchLmphmMod 3;
BA_ "RoutingFactor" SG_ 2176872449 HDCT_EngCltchLmphmMod 5;
BA_ "Version" SG_ 2176872449 HDCT_EngCltchLmphmMod "19.10.01";
BA_ "UserSigValidity" SG_ 2176872449 HDCT_CurrPrgrm 3;
BA_ "RoutingFactor" SG_ 2176872449 HDCT_CurrPrgrm 5;
BA_ "Version" SG_ 2176872449 HDCT_CurrPrgrm "19.10.01";
BA_ "Description" SG_ 2176872449 HDCT_FltSta "informs about status of transmission control.



<Value Description>

Bit 0: TCU Diagnostic failure

Bit 1: TCU Diagnostic failure ? Limphome activated

Bit 2: OPU/EOP Diagnostic failure";
BA_ "UserSigValidity" SG_ 2176872449 HDCT_FltSta 3;
BA_ "RoutingFactor" SG_ 2176872449 HDCT_FltSta 5;
BA_ "Version" SG_ 2176872449 HDCT_FltSta "20.02.00";
BA_ "Description" SG_ 2176872449 HDCT_MCUAntJrkInhbt "MCU anti-jerk inhibition";
BA_ "UserSigValidity" SG_ 2176872449 HDCT_MCUAntJrkInhbt 3;
BA_ "RoutingFactor" SG_ 2176872449 HDCT_MCUAntJrkInhbt 5;
BA_ "Version" SG_ 2176872449 HDCT_MCUAntJrkInhbt "19.10.01";
BA_ "Description" SG_ 2176872449 HDCT_TrgtGear "HTCU_TrgtGearSta informs about the speed, which is currently engaged in the gearbox, or, in case of a gear change (HTCU_GearChgSta), which speed is reached.

Note: Gear changes covering more than one speed are also possible.

In the P and N positions, the frictional connection is interrupted hydraulically.

Depending on the type of error, the 3rd or 4th (forward) speed, and the R (reverse) speed are engaged in the limp home program.";
BA_ "UserSigValidity" SG_ 2176872449 HDCT_TrgtGear 3;
BA_ "RoutingFactor" SG_ 2176872449 HDCT_TrgtGear 5;
BA_ "Version" SG_ 2176872449 HDCT_TrgtGear "19.10.01";
BA_ "Description" SG_ 2176872449 HDCT_CurrGear "CUR_GR indicates the gear speed which is currently engaged in the gearbox.";
BA_ "UserSigValidity" SG_ 2176872449 HDCT_CurrGear 3;
BA_ "RoutingFactor" SG_ 2176872449 HDCT_CurrGear 5;
BA_ "Version" SG_ 2176872449 HDCT_CurrGear "19.10.01";
BA_ "Description" SG_ 2176872449 HDCT_GearSelDis "Position (P, R, N..), which was identified by the gear selector.

In case the gear selector is in a intermediate position, the last clear recognized position is used.

There is no specific phase relationship between the output and any other signal.";
BA_ "GenSigStartValue" SG_ 2176872449 HDCT_GearSelDis 9;
BA_ "UserSigValidity" SG_ 2176872449 HDCT_GearSelDis 3;
BA_ "RoutingFactor" SG_ 2176872449 HDCT_GearSelDis 5;
BA_ "Version" SG_ 2176872449 HDCT_GearSelDis "19.10.01";
BA_ "GenMsgSendType" BO_ 2176872450 0;
BA_ "GenMsgCycleTime" BO_ 2176872450 50;
BA_ "GenMsgCycleTimeFast" BO_ 2176872450 0;
BA_ "GenMsgNrOfRepetition" BO_ 2176872450 0;
BA_ "VFrameFormat" BO_ 2176872450 1;
BA_ "Description" SG_ 2176872450 HDCT_TCURdySta "Flag that the HTCU is ready to work. (In fact, this flag is true from the moment that CAN is working. So, normally no ¡°false¡± will be sent on CAN.) This flag does not show that everything is alright in the HTCU. This information is given in the warning and fault flags.";
BA_ "UserSigValidity" SG_ 2176872450 HDCT_TCURdySta 3;
BA_ "RoutingFactor" SG_ 2176872450 HDCT_TCURdySta 5;
BA_ "Version" SG_ 2176872450 HDCT_TCURdySta "19.10.01";
BA_ "Description" SG_ 2176872450 HDCT_NetrlCtrlSta "This signal indicates the status of Neutral Control Response.";
BA_ "UserSigValidity" SG_ 2176872450 HDCT_NetrlCtrlSta 3;
BA_ "RoutingFactor" SG_ 2176872450 HDCT_NetrlCtrlSta 5;
BA_ "Version" SG_ 2176872450 HDCT_NetrlCtrlSta "19.10.01";
BA_ "Description" SG_ 2176872450 HDCT_GearShftSta "HTCU_GearChgSta indicates whether a gear change is being executed in the gearbox.

Note : Gear change means a gear shift at D-range and Garage shift(PRND).";
BA_ "UserSigValidity" SG_ 2176872450 HDCT_GearShftSta 3;
BA_ "RoutingFactor" SG_ 2176872450 HDCT_GearShftSta 5;
BA_ "Version" SG_ 2176872450 HDCT_GearShftSta "19.10.01";
BA_ "Description" SG_ 2176872450 HDCT_TqRdctnVal "The HTCU requests a torque reduction via the signal CR_Tcu_TqInt_Pc to the ECU and MCU.

The requested torque HTCU_TqRdctnPcVal refers to a maximum torque CR_Ems_TqStd_Nm. This conversion into a physical quantity provides a range of CR_Ems_TqStd_Nm of 0 ..199.61%.

There is no specific phase relationship between the output and any other signal.

Conversion : (PH) = 0.390625 * (HEX) [%]";
BA_ "GenSigStartValue" SG_ 2176872450 HDCT_TqRdctnVal 1023;
BA_ "UserSigValidity" SG_ 2176872450 HDCT_TqRdctnVal 3;
BA_ "RoutingFactor" SG_ 2176872450 HDCT_TqRdctnVal 5;
BA_ "Version" SG_ 2176872450 HDCT_TqRdctnVal "20.05.02";
BA_ "Description" SG_ 2176872450 HDCT_CtrlablSta "CF_Tcu_Cont indicates the status of the HTCU control which normally works by hydraulic pressure in the T/M";
BA_ "UserSigValidity" SG_ 2176872450 HDCT_CtrlablSta 3;
BA_ "RoutingFactor" SG_ 2176872450 HDCT_CtrlablSta 5;
BA_ "Version" SG_ 2176872450 HDCT_CtrlablSta "19.10.01";
BA_ "Description" SG_ 2176872450 HTCU_SlwTqRdctnVal "The HTCU requests a slow torque reduction via the signal HTCU_TqRdctnPcVal to the ECU and MCU.";
BA_ "GenSigStartValue" SG_ 2176872450 HTCU_SlwTqRdctnVal 511;
BA_ "UserSigValidity" SG_ 2176872450 HTCU_SlwTqRdctnVal 3;
BA_ "RoutingFactor" SG_ 2176872450 HTCU_SlwTqRdctnVal 5;
BA_ "Version" SG_ 2176872450 HTCU_SlwTqRdctnVal "19.10.01";
BA_ "Description" SG_ 2176872450 HDCT_TqIncReq "An Identifier of a DCT HTCU controller for increasing torque intervention. 



This bit is to prevent the triggering of unintended DCT HTCU interventions.";
BA_ "UserSigValidity" SG_ 2176872450 HDCT_TqIncReq 3;
BA_ "RoutingFactor" SG_ 2176872450 HDCT_TqIncReq 5;
BA_ "Version" SG_ 2176872450 HDCT_TqIncReq "19.10.01";
BA_ "Description" SG_ 2176872450 HDCT_TqIncVal "The HTCU requests the engine RPM increase via the signal HTCU_TqIncPcVal to the EMS..

The requested torque HTCU_TqIncPcVal refers to maximum torque CR_Ems_TqStd_Nm. This conversion into a physical quantity provides a range of CR_Ems_TqStd_Nm of 0..99.6094%.";
BA_ "UserSigValidity" SG_ 2176872450 HDCT_TqIncVal 3;
BA_ "RoutingFactor" SG_ 2176872450 HDCT_TqIncVal 5;
BA_ "Version" SG_ 2176872450 HDCT_TqIncVal "20.05.02";
BA_ "Description" SG_ 2176872450 HDCT_TrgtShftCls "HTCU Shift Target Class";
BA_ "UserSigValidity" SG_ 2176872450 HDCT_TrgtShftCls 3;
BA_ "RoutingFactor" SG_ 2176872450 HDCT_TrgtShftCls 5;
BA_ "Version" SG_ 2176872450 HDCT_TrgtShftCls "19.10.01";
BA_ "UserSigValidity" SG_ 2176872450 HDCT_EOLReq 3;
BA_ "RoutingFactor" SG_ 2176872450 HDCT_EOLReq 5;
BA_ "Version" SG_ 2176872450 HDCT_EOLReq "19.10.01";
BA_ "Description" SG_ 2176872450 HDCT_CltchSta "Status of DCT clutches. This signal gives information about the frictional connection between the engine and the drive train.";
BA_ "UserSigValidity" SG_ 2176872450 HDCT_CltchSta 3;
BA_ "RoutingFactor" SG_ 2176872450 HDCT_CltchSta 5;
BA_ "Version" SG_ 2176872450 HDCT_CltchSta "19.10.01";
BA_ "UserSigValidity" SG_ 2176872450 HDCT_DblCltchSta 3;
BA_ "RoutingFactor" SG_ 2176872450 HDCT_DblCltchSta 5;
BA_ "Version" SG_ 2176872450 HDCT_DblCltchSta "19.10.01";
BA_ "Description" SG_ 2176872450 HDCT_AcnChrgInhbtReq "Inhibit changes of engine torque. e.g. by changing status of the air condition.";
BA_ "UserSigValidity" SG_ 2176872450 HDCT_AcnChrgInhbtReq 3;
BA_ "RoutingFactor" SG_ 2176872450 HDCT_AcnChrgInhbtReq 5;
BA_ "Version" SG_ 2176872450 HDCT_AcnChrgInhbtReq "19.10.01";
BA_ "UserSigValidity" SG_ 2176872450 HDCT_SlipCrnkAllw 3;
BA_ "RoutingFactor" SG_ 2176872450 HDCT_SlipCrnkAllw 5;
BA_ "Version" SG_ 2176872450 HDCT_SlipCrnkAllw "19.10.01";
BA_ "UserSigValidity" SG_ 2176872450 HDCT_KckDnSkpShftCnt 3;
BA_ "RoutingFactor" SG_ 2176872450 HDCT_KckDnSkpShftCnt 5;
BA_ "Version" SG_ 2176872450 HDCT_KckDnSkpShftCnt "19.10.01";
BA_ "Description" SG_ 2176872450 HDCT_ShftPhase "HDCT_ShftPhaseSta informs about control shift phase of the release element or apply element during shifting.";
BA_ "UserSigValidity" SG_ 2176872450 HDCT_ShftPhase 3;
BA_ "RoutingFactor" SG_ 2176872450 HDCT_ShftPhase 5;
BA_ "Version" SG_ 2176872450 HDCT_ShftPhase "19.10.01";
BA_ "GenMsgSendType" BO_ 2176872451 0;
BA_ "GenMsgCycleTime" BO_ 2176872451 50;
BA_ "GenMsgCycleTimeFast" BO_ 2176872451 0;
BA_ "GenMsgNrOfRepetition" BO_ 2176872451 0;
BA_ "VFrameFormat" BO_ 2176872451 1;
BA_ "Description" SG_ 2176872451 HDCT_FuelCutReq "Fuel Cut request bit signal to let EMS perform ¡®Fuel Cut torque intervention¡¯ during shift.";
BA_ "UserSigValidity" SG_ 2176872451 HDCT_FuelCutReq 3;
BA_ "RoutingFactor" SG_ 2176872451 HDCT_FuelCutReq 5;
BA_ "Version" SG_ 2176872451 HDCT_FuelCutReq "19.10.02";
BA_ "Description" SG_ 2176872451 HDCT_NCoastTrgtGear "Target Gear Information to Control of gN Coast Down";
BA_ "UserSigValidity" SG_ 2176872451 HDCT_NCoastTrgtGear 3;
BA_ "RoutingFactor" SG_ 2176872451 HDCT_NCoastTrgtGear 5;
BA_ "Version" SG_ 2176872451 HDCT_NCoastTrgtGear "19.10.02";
BA_ "Description" SG_ 2176872451 HDCT_CLUEngSpdFlag "Flag for Engine RPM(from ECU) Display on Cluster, Only when this flag is set to 1, Cluster shall display the Engine RPM from TCU";
BA_ "UserSigValidity" SG_ 2176872451 HDCT_CLUEngSpdFlag 3;
BA_ "RoutingFactor" SG_ 2176872451 HDCT_CLUEngSpdFlag 5;
BA_ "Version" SG_ 2176872451 HDCT_CLUEngSpdFlag "19.10.02";
BA_ "Description" SG_ 2176872451 HDCT_CLUTrgtGear "This target gear signal is only for Cluster.



It is different with HTCU_TrgtGearSta.";
BA_ "UserSigValidity" SG_ 2176872451 HDCT_CLUTrgtGear 3;
BA_ "RoutingFactor" SG_ 2176872451 HDCT_CLUTrgtGear 5;
BA_ "Version" SG_ 2176872451 HDCT_CLUTrgtGear "19.10.02";
BA_ "Description" SG_ 2176872451 HDCT_GSITrgtGear "Target Gear Information for Gear Shift Indicator";
BA_ "UserSigValidity" SG_ 2176872451 HDCT_GSITrgtGear 3;
BA_ "RoutingFactor" SG_ 2176872451 HDCT_GSITrgtGear 5;
BA_ "Version" SG_ 2176872451 HDCT_GSITrgtGear "19.10.02";
BA_ "Description" SG_ 2176872451 HDCT_NCoastDnReq "Act of gN Coast Down 

(Requested of Not Requested)";
BA_ "UserSigValidity" SG_ 2176872451 HDCT_NCoastDnReq 3;
BA_ "RoutingFactor" SG_ 2176872451 HDCT_NCoastDnReq 5;
BA_ "Version" SG_ 2176872451 HDCT_NCoastDnReq "19.10.02";
BA_ "Description" SG_ 2176872451 HDCT_CLUEngSpd "Engine RPM from TCU(only for the display on Cluster)";
BA_ "UserSigValidity" SG_ 2176872451 HDCT_CLUEngSpd 3;
BA_ "RoutingFactor" SG_ 2176872451 HDCT_CLUEngSpd 5;
BA_ "Version" SG_ 2176872451 HDCT_CLUEngSpd "19.10.02";
BA_ "GenMsgSendType" BO_ 2176872452 0;
BA_ "GenMsgCycleTime" BO_ 2176872452 50;
BA_ "GenMsgCycleTimeFast" BO_ 2176872452 0;
BA_ "GenMsgNrOfRepetition" BO_ 2176872452 0;
BA_ "VFrameFormat" BO_ 2176872452 1;
BA_ "GenMsgCycleTime" BO_ 676 0;
BA_ "Description" SG_ 676 C_DrAirSptNValueSet_EC "Driver Seat Smart Air Support On/Off";
BA_ "GenSigSendType" SG_ 676 C_DrAirSptNValueSet_EC 4;
BA_ "UserSigValidity" SG_ 676 C_DrAirSptNValueSet_EC 0;
BA_REL_ "GenSigTimeoutTime" BU_SG_REL_ DLBCU SG_ 676 C_DrAirSptNValueSet_EC 0;
BA_REL_ "GenSigTimeoutTime" BU_SG_REL_ DSAU SG_ 676 C_DrAirSptNValueSet_EC 0;
BA_ "Version" SG_ 676 C_DrAirSptNValueSet_EC "20.02.03";
BA_ "Description" SG_ 676 C_DrCushSoftNValueSet_EC "Driver Seat Cushion Softness";
BA_ "GenSigSendType" SG_ 676 C_DrCushSoftNValueSet_EC 4;
BA_ "UserSigValidity" SG_ 676 C_DrCushSoftNValueSet_EC 0;
BA_REL_ "GenSigTimeoutTime" BU_SG_REL_ DPSU SG_ 676 C_DrCushSoftNValueSet_EC 0;
BA_REL_ "GenSigTimeoutTime" BU_SG_REL_ DLBCU SG_ 676 C_DrCushSoftNValueSet_EC 0;
BA_REL_ "GenSigTimeoutTime" BU_SG_REL_ DSAU SG_ 676 C_DrCushSoftNValueSet_EC 0;
BA_ "Version" SG_ 676 C_DrCushSoftNValueSet_EC "20.02.03";
BA_ "Description" SG_ 676 C_AstAirSptNValueSet_EC "Assistant Seat Smart Air Support On/Off";
BA_ "GenSigSendType" SG_ 676 C_AstAirSptNValueSet_EC 4;
BA_ "UserSigValidity" SG_ 676 C_AstAirSptNValueSet_EC 0;
BA_REL_ "GenSigTimeoutTime" BU_SG_REL_ ASAU SG_ 676 C_AstAirSptNValueSet_EC 0;
BA_REL_ "GenSigTimeoutTime" BU_SG_REL_ ALBCU SG_ 676 C_AstAirSptNValueSet_EC 0;
BA_ "Version" SG_ 676 C_AstAirSptNValueSet_EC "20.02.03";
BA_ "Description" SG_ 676 C_DrBackSoftNValueSet_EC "Driver Seat Back Softness";
BA_ "GenSigSendType" SG_ 676 C_DrBackSoftNValueSet_EC 4;
BA_ "UserSigValidity" SG_ 676 C_DrBackSoftNValueSet_EC 0;
BA_REL_ "GenSigTimeoutTime" BU_SG_REL_ DPSU SG_ 676 C_DrBackSoftNValueSet_EC 0;
BA_REL_ "GenSigTimeoutTime" BU_SG_REL_ DLBCU SG_ 676 C_DrBackSoftNValueSet_EC 0;
BA_REL_ "GenSigTimeoutTime" BU_SG_REL_ DSAU SG_ 676 C_DrBackSoftNValueSet_EC 0;
BA_ "Version" SG_ 676 C_DrBackSoftNValueSet_EC "20.02.03";
BA_ "Description" SG_ 676 C_AstAirSptModeNValueSet_EC "Assistant Seat Smart Air Support Mode";
BA_ "GenSigSendType" SG_ 676 C_AstAirSptModeNValueSet_EC 4;
BA_ "UserSigValidity" SG_ 676 C_AstAirSptModeNValueSet_EC 0;
BA_REL_ "GenSigTimeoutTime" BU_SG_REL_ ASAU SG_ 676 C_AstAirSptModeNValueSet_EC 0;
BA_REL_ "GenSigTimeoutTime" BU_SG_REL_ ALBCU SG_ 676 C_AstAirSptModeNValueSet_EC 0;
BA_ "Version" SG_ 676 C_AstAirSptModeNValueSet_EC "20.02.03";
BA_ "Description" SG_ 676 C_DrAirSptModeNValueSet_EC "Driver Seat Smart Air Support Mode";
BA_ "GenSigSendType" SG_ 676 C_DrAirSptModeNValueSet_EC 4;
BA_ "UserSigValidity" SG_ 676 C_DrAirSptModeNValueSet_EC 0;
BA_REL_ "GenSigTimeoutTime" BU_SG_REL_ DLBCU SG_ 676 C_DrAirSptModeNValueSet_EC 0;
BA_REL_ "GenSigTimeoutTime" BU_SG_REL_ DSAU SG_ 676 C_DrAirSptModeNValueSet_EC 0;
BA_ "Version" SG_ 676 C_DrAirSptModeNValueSet_EC "20.02.03";
BA_ "Description" SG_ 676 C_RLAirSptNValueSet_EC "2nd Left Seat Smart Air Support On/Off";
BA_ "GenSigSendType" SG_ 676 C_RLAirSptNValueSet_EC 4;
BA_ "UserSigValidity" SG_ 676 C_RLAirSptNValueSet_EC 0;
BA_REL_ "GenSigTimeoutTime" BU_SG_REL_ RLPSU SG_ 676 C_RLAirSptNValueSet_EC 0;
BA_REL_ "GenSigTimeoutTime" BU_SG_REL_ ATS SG_ 676 C_RLAirSptNValueSet_EC 0;
BA_ "Version" SG_ 676 C_RLAirSptNValueSet_EC "20.02.03";
BA_ "Description" SG_ 676 C_AstAirSptStrNValueSet_EC "Assistant Seat Smart Air Support Strength";
BA_ "GenSigSendType" SG_ 676 C_AstAirSptStrNValueSet_EC 4;
BA_ "UserSigValidity" SG_ 676 C_AstAirSptStrNValueSet_EC 0;
BA_REL_ "GenSigTimeoutTime" BU_SG_REL_ ASAU SG_ 676 C_AstAirSptStrNValueSet_EC 0;
BA_REL_ "GenSigTimeoutTime" BU_SG_REL_ ALBCU SG_ 676 C_AstAirSptStrNValueSet_EC 0;
BA_ "Version" SG_ 676 C_AstAirSptStrNValueSet_EC "20.02.03";
BA_ "Description" SG_ 676 C_AstAirSptTimeNValueSet_EC "Assistant Seat Smart Air Support Time";
BA_ "GenSigSendType" SG_ 676 C_AstAirSptTimeNValueSet_EC 4;
BA_ "UserSigValidity" SG_ 676 C_AstAirSptTimeNValueSet_EC 0;
BA_REL_ "GenSigTimeoutTime" BU_SG_REL_ ASAU SG_ 676 C_AstAirSptTimeNValueSet_EC 0;
BA_REL_ "GenSigTimeoutTime" BU_SG_REL_ ALBCU SG_ 676 C_AstAirSptTimeNValueSet_EC 0;
BA_ "Version" SG_ 676 C_AstAirSptTimeNValueSet_EC "20.02.03";
BA_ "Description" SG_ 676 C_RRAirSptNValueSet_EC "2nd Right side seat Smart Air Support On/Off";
BA_ "GenSigSendType" SG_ 676 C_RRAirSptNValueSet_EC 4;
BA_ "UserSigValidity" SG_ 676 C_RRAirSptNValueSet_EC 0;
BA_REL_ "GenSigTimeoutTime" BU_SG_REL_ RRPSU SG_ 676 C_RRAirSptNValueSet_EC 0;
BA_REL_ "GenSigTimeoutTime" BU_SG_REL_ ATS SG_ 676 C_RRAirSptNValueSet_EC 0;
BA_ "Version" SG_ 676 C_RRAirSptNValueSet_EC "20.02.03";
BA_ "Description" SG_ 676 C_AstCushSoftNValueSet_EC "Assistant Seat Cushion Softness off/low/mid/high";
BA_ "GenSigSendType" SG_ 676 C_AstCushSoftNValueSet_EC 4;
BA_ "UserSigValidity" SG_ 676 C_AstCushSoftNValueSet_EC 0;
BA_REL_ "GenSigTimeoutTime" BU_SG_REL_ ASAU SG_ 676 C_AstCushSoftNValueSet_EC 0;
BA_ "Version" SG_ 676 C_AstCushSoftNValueSet_EC "20.02.03";
BA_ "Description" SG_ 676 C_AstBackSoftNValueSet_EC "Assistant Seat Back Softness Off/Low/Mid/High";
BA_ "GenSigSendType" SG_ 676 C_AstBackSoftNValueSet_EC 4;
BA_ "UserSigValidity" SG_ 676 C_AstBackSoftNValueSet_EC 0;
BA_REL_ "GenSigTimeoutTime" BU_SG_REL_ ASAU SG_ 676 C_AstBackSoftNValueSet_EC 0;
BA_ "Version" SG_ 676 C_AstBackSoftNValueSet_EC "20.02.03";
BA_ "Description" SG_ 676 C_AstRlxNValueSet_EC "Assistant seat Moving control : Relaxtion mode";
BA_ "GenSigSendType" SG_ 676 C_AstRlxNValueSet_EC 4;
BA_ "UserSigValidity" SG_ 676 C_AstRlxNValueSet_EC 0;
BA_REL_ "GenSigTimeoutTime" BU_SG_REL_ APSU SG_ 676 C_AstRlxNValueSet_EC 0;
BA_ "Version" SG_ 676 C_AstRlxNValueSet_EC "20.02.03";
BA_ "Description" SG_ 676 C_RLAirSptModeNValueSet_EC "2nd Left Seat Smart Air Support Mode";
BA_ "GenSigSendType" SG_ 676 C_RLAirSptModeNValueSet_EC 4;
BA_ "UserSigValidity" SG_ 676 C_RLAirSptModeNValueSet_EC 0;
BA_REL_ "GenSigTimeoutTime" BU_SG_REL_ RLPSU SG_ 676 C_RLAirSptModeNValueSet_EC 0;
BA_REL_ "GenSigTimeoutTime" BU_SG_REL_ ATS SG_ 676 C_RLAirSptModeNValueSet_EC 0;
BA_ "Version" SG_ 676 C_RLAirSptModeNValueSet_EC "20.02.03";
BA_ "Description" SG_ 676 C_DrAirSptStrNValueSet_EC "Driver Seat Smart Air Support Strength";
BA_ "GenSigSendType" SG_ 676 C_DrAirSptStrNValueSet_EC 4;
BA_ "UserSigValidity" SG_ 676 C_DrAirSptStrNValueSet_EC 0;
BA_REL_ "GenSigTimeoutTime" BU_SG_REL_ DLBCU SG_ 676 C_DrAirSptStrNValueSet_EC 0;
BA_REL_ "GenSigTimeoutTime" BU_SG_REL_ DSAU SG_ 676 C_DrAirSptStrNValueSet_EC 0;
BA_ "Version" SG_ 676 C_DrAirSptStrNValueSet_EC "20.02.03";
BA_ "Description" SG_ 676 C_RLAirSptStrNValueSet_EC "2nd Left Seat Smart Air Support Strength";
BA_ "GenSigSendType" SG_ 676 C_RLAirSptStrNValueSet_EC 4;
BA_ "UserSigValidity" SG_ 676 C_RLAirSptStrNValueSet_EC 0;
BA_REL_ "GenSigTimeoutTime" BU_SG_REL_ RLPSU SG_ 676 C_RLAirSptStrNValueSet_EC 0;
BA_REL_ "GenSigTimeoutTime" BU_SG_REL_ ATS SG_ 676 C_RLAirSptStrNValueSet_EC 0;
BA_ "Version" SG_ 676 C_RLAirSptStrNValueSet_EC "20.02.03";
BA_ "Description" SG_ 676 C_RLAirSptTimeNValueSet_EC "2nd Left Seat Smart Air Support Time";
BA_ "GenSigSendType" SG_ 676 C_RLAirSptTimeNValueSet_EC 4;
BA_ "UserSigValidity" SG_ 676 C_RLAirSptTimeNValueSet_EC 0;
BA_REL_ "GenSigTimeoutTime" BU_SG_REL_ RLPSU SG_ 676 C_RLAirSptTimeNValueSet_EC 0;
BA_REL_ "GenSigTimeoutTime" BU_SG_REL_ ATS SG_ 676 C_RLAirSptTimeNValueSet_EC 0;
BA_ "Version" SG_ 676 C_RLAirSptTimeNValueSet_EC "20.02.03";
BA_ "Description" SG_ 676 C_DrAirSptTimeNValueSet_EC "Driver Seat Smart Air Support Time";
BA_ "GenSigSendType" SG_ 676 C_DrAirSptTimeNValueSet_EC 4;
BA_ "UserSigValidity" SG_ 676 C_DrAirSptTimeNValueSet_EC 0;
BA_REL_ "GenSigTimeoutTime" BU_SG_REL_ DLBCU SG_ 676 C_DrAirSptTimeNValueSet_EC 0;
BA_REL_ "GenSigTimeoutTime" BU_SG_REL_ DSAU SG_ 676 C_DrAirSptTimeNValueSet_EC 0;
BA_ "Version" SG_ 676 C_DrAirSptTimeNValueSet_EC "20.02.03";
BA_ "GenMsgCycleTime" BO_ 677 0;
BA_ "Description" SG_ 677 C_RLBackSoftNValueSet_EC "2nd Left Seat Back Softness";
BA_ "GenSigSendType" SG_ 677 C_RLBackSoftNValueSet_EC 4;
BA_ "UserSigValidity" SG_ 677 C_RLBackSoftNValueSet_EC 0;
BA_REL_ "GenSigTimeoutTime" BU_SG_REL_ RLPSU SG_ 677 C_RLBackSoftNValueSet_EC 0;
BA_REL_ "GenSigTimeoutTime" BU_SG_REL_ ATS SG_ 677 C_RLBackSoftNValueSet_EC 0;
BA_ "Version" SG_ 677 C_RLBackSoftNValueSet_EC "20.02.03";
BA_ "Description" SG_ 677 C_RRAirSptStrNValueSet_EC "2nd Right side seat Smart Air Support Strength";
BA_ "GenSigSendType" SG_ 677 C_RRAirSptStrNValueSet_EC 4;
BA_ "UserSigValidity" SG_ 677 C_RRAirSptStrNValueSet_EC 0;
BA_REL_ "GenSigTimeoutTime" BU_SG_REL_ RRPSU SG_ 677 C_RRAirSptStrNValueSet_EC 0;
BA_REL_ "GenSigTimeoutTime" BU_SG_REL_ ATS SG_ 677 C_RRAirSptStrNValueSet_EC 0;
BA_ "Version" SG_ 677 C_RRAirSptStrNValueSet_EC "20.02.03";
BA_ "Description" SG_ 677 C_RRAirSptTimeNValueSet_EC "2nd Right side seat Smart Air Support Time";
BA_ "GenSigSendType" SG_ 677 C_RRAirSptTimeNValueSet_EC 4;
BA_ "UserSigValidity" SG_ 677 C_RRAirSptTimeNValueSet_EC 0;
BA_REL_ "GenSigTimeoutTime" BU_SG_REL_ RRPSU SG_ 677 C_RRAirSptTimeNValueSet_EC 0;
BA_REL_ "GenSigTimeoutTime" BU_SG_REL_ ATS SG_ 677 C_RRAirSptTimeNValueSet_EC 0;
BA_ "Version" SG_ 677 C_RRAirSptTimeNValueSet_EC "20.02.03";
BA_ "Description" SG_ 677 C_RRBackSoftNValueSet_EC "2nd Right side seat Back Softness";
BA_ "GenSigSendType" SG_ 677 C_RRBackSoftNValueSet_EC 4;
BA_ "UserSigValidity" SG_ 677 C_RRBackSoftNValueSet_EC 0;
BA_REL_ "GenSigTimeoutTime" BU_SG_REL_ RRPSU SG_ 677 C_RRBackSoftNValueSet_EC 0;
BA_REL_ "GenSigTimeoutTime" BU_SG_REL_ ATS SG_ 677 C_RRBackSoftNValueSet_EC 0;
BA_ "Version" SG_ 677 C_RRBackSoftNValueSet_EC "20.02.03";
BA_ "Description" SG_ 677 C_RROneTchNvalueSet_EC "2nd Right side seat One Touch Mode";
BA_ "GenSigSendType" SG_ 677 C_RROneTchNvalueSet_EC 4;
BA_ "UserSigValidity" SG_ 677 C_RROneTchNvalueSet_EC 0;
BA_REL_ "GenSigTimeoutTime" BU_SG_REL_ RRPSU SG_ 677 C_RROneTchNvalueSet_EC 0;
BA_REL_ "GenSigTimeoutTime" BU_SG_REL_ ATS SG_ 677 C_RROneTchNvalueSet_EC 0;
BA_ "Version" SG_ 677 C_RROneTchNvalueSet_EC "20.02.03";
BA_ "Description" SG_ 677 C_RLOneTchNValueSet_EC "2nd Left side seat One Touch Mode";
BA_ "GenSigSendType" SG_ 677 C_RLOneTchNValueSet_EC 4;
BA_ "UserSigValidity" SG_ 677 C_RLOneTchNValueSet_EC 0;
BA_REL_ "GenSigTimeoutTime" BU_SG_REL_ RRPSU SG_ 677 C_RLOneTchNValueSet_EC 0;
BA_REL_ "GenSigTimeoutTime" BU_SG_REL_ RLPSU SG_ 677 C_RLOneTchNValueSet_EC 0;
BA_REL_ "GenSigTimeoutTime" BU_SG_REL_ ATS SG_ 677 C_RLOneTchNValueSet_EC 0;
BA_ "Version" SG_ 677 C_RLOneTchNValueSet_EC "20.02.03";
BA_ "Description" SG_ 677 C_RRAirSptModeNValueSet_EC "2nd Right side seat Moving control : Smart Air Support Mode";
BA_ "GenSigSendType" SG_ 677 C_RRAirSptModeNValueSet_EC 4;
BA_ "UserSigValidity" SG_ 677 C_RRAirSptModeNValueSet_EC 0;
BA_REL_ "GenSigTimeoutTime" BU_SG_REL_ RRPSU SG_ 677 C_RRAirSptModeNValueSet_EC 0;
BA_REL_ "GenSigTimeoutTime" BU_SG_REL_ ATS SG_ 677 C_RRAirSptModeNValueSet_EC 0;
BA_ "Version" SG_ 677 C_RRAirSptModeNValueSet_EC "20.02.03";
BA_ "GenMsgSendType" BO_ 1239 0;
BA_ "Description" SG_ 1239 HU_MKBD_BtnLEDCtr "MKBD Button LED Backlight control signal (Hidden Light Button)";
BA_ "GenSigSendType" SG_ 1239 HU_MKBD_BtnLEDCtr 4;
BA_ "GenSigStartValue" SG_ 1239 HU_MKBD_BtnLEDCtr 3;
BA_ "UserSigValidity" SG_ 1239 HU_MKBD_BtnLEDCtr 0;
BA_ "Version" SG_ 1239 HU_MKBD_BtnLEDCtr "19.07.05";
BA_ "Description" SG_ 1239 HU_ADMSettingState "The signal transfers ADM Setting Value(On/Off) from HU to other module.";
BA_ "GenSigSendType" SG_ 1239 HU_ADMSettingState 4;
BA_ "UserSigValidity" SG_ 1239 HU_ADMSettingState 0;
BA_ "NetworkRequest" SG_ 1239 HU_ADMSettingState 0;
BA_ "NetworkRequestHoldingTime" SG_ 1239 HU_ADMSettingState 5000;
BA_ "Version" SG_ 1239 HU_ADMSettingState "21.01.07";
BA_ "Description" SG_ 1239 HU_DigitalKeyInformAvailable "DigitalKeyInformAvailable";
BA_ "GenSigSendType" SG_ 1239 HU_DigitalKeyInformAvailable 4;
BA_ "GenSigStartValue" SG_ 1239 HU_DigitalKeyInformAvailable 3;
BA_ "TimeoutValue" SG_ 1239 HU_DigitalKeyInformAvailable "0x3";
BA_ "UserSigValidity" SG_ 1239 HU_DigitalKeyInformAvailable 0;
BA_ "NetworkRequest" SG_ 1239 HU_DigitalKeyInformAvailable 0;
BA_ "NetworkRequestHoldingTime" SG_ 1239 HU_DigitalKeyInformAvailable 5000;
BA_ "Version" SG_ 1239 HU_DigitalKeyInformAvailable "21.03.01";
BA_ "GenSigSendType" SG_ 1239 HU_VehiclePwr 4;
BA_ "UserSigValidity" SG_ 1239 HU_VehiclePwr 0;
BA_REL_ "GenSigTimeoutTime" BU_SG_REL_ SGU SG_ 1239 HU_VehiclePwr 1500;
BA_ "NetworkRequest" SG_ 1239 HU_VehiclePwr 0;
BA_ "NetworkRequestHoldingTime" SG_ 1239 HU_VehiclePwr 5000;
BA_ "Version" SG_ 1239 HU_VehiclePwr "21.01.01";
BA_ "Description" SG_ 1239 HU_BtnShowReq "This signal indicates requesting turn on/off button light for H/Unit related buttons.";
BA_ "GenSigSendType" SG_ 1239 HU_BtnShowReq 4;
BA_ "GenSigStartValue" SG_ 1239 HU_BtnShowReq 7;
BA_ "UserSigValidity" SG_ 1239 HU_BtnShowReq 0;
BA_REL_ "GenSigTimeoutTime" BU_SG_REL_ SWRC SG_ 1239 HU_BtnShowReq 1500;
BA_ "NetworkRequest" SG_ 1239 HU_BtnShowReq 0;
BA_ "NetworkRequestHoldingTime" SG_ 1239 HU_BtnShowReq 5000;
BA_ "Version" SG_ 1239 HU_BtnShowReq "19.11.01";
BA_ "GenMsgSendType" BO_ 1240 0;
BA_ "Description" SG_ 1240 HU_DistanceUnit "16.12.02_J.H.J. DR Request";
BA_ "GenSigSendType" SG_ 1240 HU_DistanceUnit 4;
BA_ "GenSigStartValue" SG_ 1240 HU_DistanceUnit 3;
BA_ "UserSigValidity" SG_ 1240 HU_DistanceUnit 1;
BA_ "NetworkRequest" SG_ 1240 HU_DistanceUnit 0;
BA_ "Version" SG_ 1240 HU_DistanceUnit "19.02.08";
BA_ "Description" SG_ 1240 HU_ThemeType "This signal indicates current H/Unit GUI theme value. 

 

Detail value -GUI Theme matching table, refer to attachement and ES SPEC";
BA_ "GenSigSendType" SG_ 1240 HU_ThemeType 4;
BA_ "GenSigStartValue" SG_ 1240 HU_ThemeType 15;
BA_ "UserSigValidity" SG_ 1240 HU_ThemeType 0;
BA_REL_ "GenSigTimeoutTime" BU_SG_REL_ ATS SG_ 1240 HU_ThemeType 1500;
BA_REL_ "GenSigTimeoutTime" BU_SG_REL_ BLTN_CAM SG_ 1240 HU_ThemeType 1500;
BA_ "Version" SG_ 1240 HU_ThemeType "20.09.00";
BA_ "Description" SG_ 1240 HU_MicActivity "16.06.02_";
BA_ "GenSigSendType" SG_ 1240 HU_MicActivity 4;
BA_ "GenSigStartValue" SG_ 1240 HU_MicActivity 3;
BA_ "UserSigValidity" SG_ 1240 HU_MicActivity 0;
BA_ "Version" SG_ 1240 HU_MicActivity "19.02.08";
BA_ "Description" SG_ 1240 HU_Scheduled_Setting "Information of scheduled update charge setting

The signal means that scheduled update charaging information send to BMS for BMS SOC control";
BA_ "GenSigSendType" SG_ 1240 HU_Scheduled_Setting 4;
BA_ "UserSigValidity" SG_ 1240 HU_Scheduled_Setting 3;
BA_ "Version" SG_ 1240 HU_Scheduled_Setting "19.05.02";
BA_ "Description" SG_ 1240 AVN_RSPA_ModeSelect "Signal for User's RSPA¥± mode setting

RSPA¥± ¸ðµå ¼±ÅÃ ¸Þ´º CCP Focus ¹× CCP Confirm or Touch °á°ú";
BA_ "GenSigSendType" SG_ 1240 AVN_RSPA_ModeSelect 4;
BA_ "GenSigStartValue" SG_ 1240 AVN_RSPA_ModeSelect 15;
BA_ "UserSigValidity" SG_ 1240 AVN_RSPA_ModeSelect 0;
BA_ "Version" SG_ 1240 AVN_RSPA_ModeSelect "19.08.08";
BA_ "GenSigSendType" SG_ 1240 CF_HU_GPSFlt 4;
BA_ "GenSigStartValue" SG_ 1240 CF_HU_GPSFlt 2;
BA_ "TimeoutValue" SG_ 1240 CF_HU_GPSFlt "0x2";
BA_ "UserSigValidity" SG_ 1240 CF_HU_GPSFlt 0;
BA_ "Version" SG_ 1240 CF_HU_GPSFlt "20.02.02";
BA_ "GenSigSendType" SG_ 1240 AVN_RSPA_CancelInput 4;
BA_ "UserSigValidity" SG_ 1240 AVN_RSPA_CancelInput 0;
BA_ "Version" SG_ 1240 AVN_RSPA_CancelInput "19.05.03";
BA_ "GenSigSendType" SG_ 1240 AVN_RSPA_Disp_Rdy 4;
BA_ "GenSigStartValue" SG_ 1240 AVN_RSPA_Disp_Rdy 3;
BA_ "UserSigValidity" SG_ 1240 AVN_RSPA_Disp_Rdy 0;
BA_ "Version" SG_ 1240 AVN_RSPA_Disp_Rdy "19.05.03";
BA_ "Description" SG_ 1240 CF_AVN_ProfileIDRValue "18.08.22_This signal is only used in User Profile applied H/Unit";
BA_ "GenSigSendType" SG_ 1240 CF_AVN_ProfileIDRValue 4;
BA_ "GenSigStartValue" SG_ 1240 CF_AVN_ProfileIDRValue 15;
BA_ "UserSigValidity" SG_ 1240 CF_AVN_ProfileIDRValue 0;
BA_REL_ "GenSigTimeoutTime" BU_SG_REL_ WPC SG_ 1240 CF_AVN_ProfileIDRValue 1500;
BA_REL_ "GenSigTimeoutTime" BU_SG_REL_ RWPC SG_ 1240 CF_AVN_ProfileIDRValue 1500;
BA_REL_ "GenSigTimeoutTime" BU_SG_REL_ DPSU SG_ 1240 CF_AVN_ProfileIDRValue 1500;
BA_REL_ "GenSigTimeoutTime" BU_SG_REL_ BLTN_CAM SG_ 1240 CF_AVN_ProfileIDRValue 1500;
BA_REL_ "GenSigTimeoutTime" BU_SG_REL_ SGU SG_ 1240 CF_AVN_ProfileIDRValue 1500;
BA_ "Version" SG_ 1240 CF_AVN_ProfileIDRValue "18.09.04";
BA_ "Description" SG_ 1240 HazardFromHUSVM "18.08.22_This signal is for the 'Premium AVNT6 && SVM&& ConnectedCarService' vehicle only";
BA_ "GenSigSendType" SG_ 1240 HazardFromHUSVM 4;
BA_ "GenSigStartValue" SG_ 1240 HazardFromHUSVM 3;
BA_ "UserSigValidity" SG_ 1240 HazardFromHUSVM 0;
BA_ "Version" SG_ 1240 HazardFromHUSVM "18.09.04";
BA_ "Description" SG_ 1240 OMUOSMirCtrl "18.08.22_This signal is for the 'Premium AVNT 6.0&&SVM&&ConnectedCarService' vehicle only";
BA_ "GenSigSendType" SG_ 1240 OMUOSMirCtrl 4;
BA_ "GenSigStartValue" SG_ 1240 OMUOSMirCtrl 3;
BA_ "UserSigValidity" SG_ 1240 OMUOSMirCtrl 0;
BA_ "Version" SG_ 1240 OMUOSMirCtrl "18.09.04";
BA_ "Description" SG_ 1240 OTAUIStatus "0x00 : Headunit is booting so, Headunit can't display any state

0x01 : Headunit is normal state, Headunit could display according to CCU command.";
BA_ "GenSigSendType" SG_ 1240 OTAUIStatus 4;
BA_ "UserSigValidity" SG_ 1240 OTAUIStatus 0;
BA_ "Version" SG_ 1240 OTAUIStatus "21.03.02";
BA_ "GenSigSendType" SG_ 1240 C_TeleActiveStatus 4;
BA_ "GenSigStartValue" SG_ 1240 C_TeleActiveStatus 3;
BA_ "UserSigValidity" SG_ 1240 C_TeleActiveStatus 0;
BA_ "Version" SG_ 1240 C_TeleActiveStatus "19.04.06";
BA_ "Description" SG_ 1240 HU_AliveStatus "18.08.22_";
BA_ "GenSigSendType" SG_ 1240 HU_AliveStatus 4;
BA_ "GenSigStartValue" SG_ 1240 HU_AliveStatus 3;
BA_ "UserSigValidity" SG_ 1240 HU_AliveStatus 0;
BA_ "NetworkRequest" SG_ 1240 HU_AliveStatus 0;
BA_ "Version" SG_ 1240 HU_AliveStatus "19.02.08";
BA_ "GenSigSendType" SG_ 1240 HU_RTCCheck 4;
BA_ "GenSigStartValue" SG_ 1240 HU_RTCCheck 3;
BA_ "TimeoutValue" SG_ 1240 HU_RTCCheck "0x3";
BA_ "UserSigValidity" SG_ 1240 HU_RTCCheck 3;
BA_REL_ "GenSigTimeoutTime" BU_SG_REL_ APSU SG_ 1240 HU_RTCCheck 1500;
BA_ "Version" SG_ 1240 HU_RTCCheck "20.02.02";
BA_ "GenMsgCycleTime" BO_ 1218 0;
BA_ "Description" SG_ 1218 C_AVN_PTGHeightNValueSet "18.08.09_";
BA_ "GenSigSendType" SG_ 1218 C_AVN_PTGHeightNValueSet 4;
BA_ "UserSigValidity" SG_ 1218 C_AVN_PTGHeightNValueSet 3;
BA_ "Version" SG_ 1218 C_AVN_PTGHeightNValueSet "19.02.07";
BA_ "Description" SG_ 1218 CF_AVN_SCCMLReset "18.08.09_";
BA_ "GenSigSendType" SG_ 1218 CF_AVN_SCCMLReset 4;
BA_ "UserSigValidity" SG_ 1218 CF_AVN_SCCMLReset 3;
BA_ "Version" SG_ 1218 CF_AVN_SCCMLReset "18.09.04";
BA_ "Description" SG_ 1218 C_TgltAwayCloseNValue "USM Request for Tailgate Away Close";
BA_ "GenSigSendType" SG_ 1218 C_TgltAwayCloseNValue 4;
BA_ "UserSigValidity" SG_ 1218 C_TgltAwayCloseNValue 3;
BA_ "Version" SG_ 1218 C_TgltAwayCloseNValue "19.01.10";
BA_ "Description" SG_ 1218 C_HAnBNValueSet "18.08.09_";
BA_ "GenSigSendType" SG_ 1218 C_HAnBNValueSet 4;
BA_ "UserSigValidity" SG_ 1218 C_HAnBNValueSet 3;
BA_ "Version" SG_ 1218 C_HAnBNValueSet "18.09.04";
BA_ "Description" SG_ 1218 CF_AVN_RrSeatRemindNValueSet "18.08.09_";
BA_ "GenSigSendType" SG_ 1218 CF_AVN_RrSeatRemindNValueSet 4;
BA_ "UserSigValidity" SG_ 1218 CF_AVN_RrSeatRemindNValueSet 3;
BA_ "Version" SG_ 1218 CF_AVN_RrSeatRemindNValueSet "18.09.04";
BA_ "Description" SG_ 1218 CF_AVN_DSWNValueSet "18.08.09_";
BA_ "GenSigSendType" SG_ 1218 CF_AVN_DSWNValueSet 4;
BA_ "UserSigValidity" SG_ 1218 CF_AVN_DSWNValueSet 3;
BA_ "Version" SG_ 1218 CF_AVN_DSWNValueSet "18.09.04";
BA_ "Description" SG_ 1218 CF_AVN_RRPSU_RLNValueSet "18.08.09_";
BA_ "GenSigSendType" SG_ 1218 CF_AVN_RRPSU_RLNValueSet 4;
BA_ "UserSigValidity" SG_ 1218 CF_AVN_RRPSU_RLNValueSet 3;
BA_REL_ "GenSigTimeoutTime" BU_SG_REL_ APSU SG_ 1218 CF_AVN_RRPSU_RLNValueSet 0;
BA_REL_ "GenSigTimeoutTime" BU_SG_REL_ RRPSU SG_ 1218 CF_AVN_RRPSU_RLNValueSet 0;
BA_REL_ "GenSigTimeoutTime" BU_SG_REL_ RLPSU SG_ 1218 CF_AVN_RRPSU_RLNValueSet 0;
BA_ "Version" SG_ 1218 CF_AVN_RRPSU_RLNValueSet "18.09.04";
BA_ "Description" SG_ 1218 CF_AVN_APSUNValueSet "18.08.09_";
BA_ "GenSigSendType" SG_ 1218 CF_AVN_APSUNValueSet 4;
BA_ "UserSigValidity" SG_ 1218 CF_AVN_APSUNValueSet 3;
BA_REL_ "GenSigTimeoutTime" BU_SG_REL_ APSU SG_ 1218 CF_AVN_APSUNValueSet 0;
BA_REL_ "GenSigTimeoutTime" BU_SG_REL_ ASAU SG_ 1218 CF_AVN_APSUNValueSet 0;
BA_ "Version" SG_ 1218 CF_AVN_APSUNValueSet "18.09.04";
BA_ "Description" SG_ 1218 CF_AVN_NCC_CameraNValueSet "18.08.09_";
BA_ "GenSigSendType" SG_ 1218 CF_AVN_NCC_CameraNValueSet 4;
BA_ "UserSigValidity" SG_ 1218 CF_AVN_NCC_CameraNValueSet 3;
BA_ "Version" SG_ 1218 CF_AVN_NCC_CameraNValueSet "18.09.04";
BA_ "Description" SG_ 1218 CF_AVN_FCAJnctnNValueSet "18.08.09_";
BA_ "GenSigSendType" SG_ 1218 CF_AVN_FCAJnctnNValueSet 4;
BA_ "UserSigValidity" SG_ 1218 CF_AVN_FCAJnctnNValueSet 3;
BA_ "Version" SG_ 1218 CF_AVN_FCAJnctnNValueSet "18.09.04";
BA_ "Description" SG_ 1218 CF_AVN_RRPSU_RRNValueSet "18.08.09_";
BA_ "GenSigSendType" SG_ 1218 CF_AVN_RRPSU_RRNValueSet 4;
BA_ "UserSigValidity" SG_ 1218 CF_AVN_RRPSU_RRNValueSet 3;
BA_REL_ "GenSigTimeoutTime" BU_SG_REL_ APSU SG_ 1218 CF_AVN_RRPSU_RRNValueSet 0;
BA_REL_ "GenSigTimeoutTime" BU_SG_REL_ RRPSU SG_ 1218 CF_AVN_RRPSU_RRNValueSet 0;
BA_REL_ "GenSigTimeoutTime" BU_SG_REL_ RLPSU SG_ 1218 CF_AVN_RRPSU_RRNValueSet 0;
BA_ "Version" SG_ 1218 CF_AVN_RRPSU_RRNValueSet "18.09.04";
BA_ "Description" SG_ 1218 CF_AVN_HtBlcAstNValueSet "18.08.09_";
BA_ "GenSigSendType" SG_ 1218 CF_AVN_HtBlcAstNValueSet 4;
BA_ "UserSigValidity" SG_ 1218 CF_AVN_HtBlcAstNValueSet 3;
BA_REL_ "GenSigTimeoutTime" BU_SG_REL_ APSU SG_ 1218 CF_AVN_HtBlcAstNValueSet 0;
BA_REL_ "GenSigTimeoutTime" BU_SG_REL_ SHVU_FR SG_ 1218 CF_AVN_HtBlcAstNValueSet 0;
BA_REL_ "GenSigTimeoutTime" BU_SG_REL_ DPSU SG_ 1218 CF_AVN_HtBlcAstNValueSet 0;
BA_ "Version" SG_ 1218 CF_AVN_HtBlcAstNValueSet "18.09.04";
BA_ "Description" SG_ 1218 CF_AVN_HtBlcDrvNValueSet "18.08.09_";
BA_ "GenSigSendType" SG_ 1218 CF_AVN_HtBlcDrvNValueSet 4;
BA_ "UserSigValidity" SG_ 1218 CF_AVN_HtBlcDrvNValueSet 3;
BA_REL_ "GenSigTimeoutTime" BU_SG_REL_ APSU SG_ 1218 CF_AVN_HtBlcDrvNValueSet 0;
BA_REL_ "GenSigTimeoutTime" BU_SG_REL_ SHVU_FR SG_ 1218 CF_AVN_HtBlcDrvNValueSet 0;
BA_REL_ "GenSigTimeoutTime" BU_SG_REL_ DPSU SG_ 1218 CF_AVN_HtBlcDrvNValueSet 0;
BA_ "Version" SG_ 1218 CF_AVN_HtBlcDrvNValueSet "18.09.04";
BA_ "Description" SG_ 1218 CF_AVN_SCCModeNValueSet "18.12.03_";
BA_ "GenSigSendType" SG_ 1218 CF_AVN_SCCModeNValueSet 4;
BA_ "GenSigStartValue" SG_ 1218 CF_AVN_SCCModeNValueSet 3;
BA_ "UserSigValidity" SG_ 1218 CF_AVN_SCCModeNValueSet 3;
BA_ "Version" SG_ 1218 CF_AVN_SCCModeNValueSet "18.12.03";
BA_ "GenSigSendType" SG_ 1218 CF_AVN_SCCMLChar1Set 4;
BA_ "UserSigValidity" SG_ 1218 CF_AVN_SCCMLChar1Set 3;
BA_ "Version" SG_ 1218 CF_AVN_SCCMLChar1Set "19.11.05";
BA_ "Description" SG_ 1218 CF_AVN_UIPNValueSet "18.10.01_";
BA_ "GenSigSendType" SG_ 1218 CF_AVN_UIPNValueSet 4;
BA_ "UserSigValidity" SG_ 1218 CF_AVN_UIPNValueSet 3;
BA_ "Version" SG_ 1218 CF_AVN_UIPNValueSet "18.10.06";
BA_ "GenSigSendType" SG_ 1218 CF_AVN_SCCMLChar2Set 4;
BA_ "UserSigValidity" SG_ 1218 CF_AVN_SCCMLChar2Set 3;
BA_ "Version" SG_ 1218 CF_AVN_SCCMLChar2Set "19.11.05";
BA_ "GenSigSendType" SG_ 1218 CF_AVN_SCCMLChar3Set 4;
BA_ "UserSigValidity" SG_ 1218 CF_AVN_SCCMLChar3Set 3;
BA_ "Version" SG_ 1218 CF_AVN_SCCMLChar3Set "19.11.05";
BA_ "Description" SG_ 1218 CF_AVN_NmodeFCAoffNValue "USM request for FCA Auto Off in N mode";
BA_ "GenSigSendType" SG_ 1218 CF_AVN_NmodeFCAoffNValue 4;
BA_ "UserSigValidity" SG_ 1218 CF_AVN_NmodeFCAoffNValue 3;
BA_ "Version" SG_ 1218 CF_AVN_NmodeFCAoffNValue "19.05.04";
BA_ "Description" SG_ 1218 CF_AVN_HDALCFuncNValueSet "18.08.09_";
BA_ "GenSigSendType" SG_ 1218 CF_AVN_HDALCFuncNValueSet 4;
BA_ "UserSigValidity" SG_ 1218 CF_AVN_HDALCFuncNValueSet 3;
BA_ "Version" SG_ 1218 CF_AVN_HDALCFuncNValueSet "18.09.04";
BA_ "GenMsgCycleTime" BO_ 675 0;
BA_ "Description" SG_ 675 Usm_RpmMUDSet "Related to Cluster Gauge";
BA_ "GenSigSendType" SG_ 675 Usm_RpmMUDSet 4;
BA_ "UserSigValidity" SG_ 675 Usm_RpmMUDSet 3;
BA_ "Version" SG_ 675 Usm_RpmMUDSet "20.02.04";
BA_ "GenSigSendType" SG_ 675 CF_AVN_HtBlcRLNValueSet 4;
BA_ "UserSigValidity" SG_ 675 CF_AVN_HtBlcRLNValueSet 3;
BA_REL_ "GenSigTimeoutTime" BU_SG_REL_ SHVU_FR SG_ 675 CF_AVN_HtBlcRLNValueSet 0;
BA_REL_ "GenSigTimeoutTime" BU_SG_REL_ SHVU_RR SG_ 675 CF_AVN_HtBlcRLNValueSet 0;
BA_REL_ "GenSigTimeoutTime" BU_SG_REL_ RRPSU SG_ 675 CF_AVN_HtBlcRLNValueSet 0;
BA_REL_ "GenSigTimeoutTime" BU_SG_REL_ RLPSU SG_ 675 CF_AVN_HtBlcRLNValueSet 0;
BA_ "Version" SG_ 675 CF_AVN_HtBlcRLNValueSet "20.06.03";
BA_ "Description" SG_ 675 CF_AVN_BRAKE_PedalfeelNValueSet2 "USM request for Brake Mode (New spec)";
BA_ "GenSigSendType" SG_ 675 CF_AVN_BRAKE_PedalfeelNValueSet2 4;
BA_ "UserSigValidity" SG_ 675 CF_AVN_BRAKE_PedalfeelNValueSet2 3;
BA_ "Version" SG_ 675 CF_AVN_BRAKE_PedalfeelNValueSet2 "20.04.06";
BA_ "GenSigSendType" SG_ 675 CF_AVN_HtBlcRRNValueSet 4;
BA_ "UserSigValidity" SG_ 675 CF_AVN_HtBlcRRNValueSet 3;
BA_REL_ "GenSigTimeoutTime" BU_SG_REL_ SHVU_FR SG_ 675 CF_AVN_HtBlcRRNValueSet 0;
BA_REL_ "GenSigTimeoutTime" BU_SG_REL_ SHVU_RR SG_ 675 CF_AVN_HtBlcRRNValueSet 0;
BA_REL_ "GenSigTimeoutTime" BU_SG_REL_ RRPSU SG_ 675 CF_AVN_HtBlcRRNValueSet 0;
BA_REL_ "GenSigTimeoutTime" BU_SG_REL_ RLPSU SG_ 675 CF_AVN_HtBlcRRNValueSet 0;
BA_ "Version" SG_ 675 CF_AVN_HtBlcRRNValueSet "20.06.03";
BA_ "Description" SG_ 675 LapTimer_AutoMeasure_Setting "Setting value for auto-measurement of Laptimer";
BA_ "GenSigSendType" SG_ 675 LapTimer_AutoMeasure_Setting 4;
BA_ "GenSigStartValue" SG_ 675 LapTimer_AutoMeasure_Setting 3;
BA_ "UserSigValidity" SG_ 675 LapTimer_AutoMeasure_Setting 3;
BA_ "Version" SG_ 675 LapTimer_AutoMeasure_Setting "20.07.11";
BA_ "Description" SG_ 675 LapTimer_TimeGap_Setting "setting value for laptimer time gap displaying";
BA_ "GenSigSendType" SG_ 675 LapTimer_TimeGap_Setting 4;
BA_ "GenSigStartValue" SG_ 675 LapTimer_TimeGap_Setting 3;
BA_ "UserSigValidity" SG_ 675 LapTimer_TimeGap_Setting 3;
BA_ "Version" SG_ 675 LapTimer_TimeGap_Setting "20.07.11";
BA_ "Description" SG_ 675 Usm_RpmSANDSet "Related to Cluster Gauge";
BA_ "GenSigSendType" SG_ 675 Usm_RpmSANDSet 4;
BA_ "UserSigValidity" SG_ 675 Usm_RpmSANDSet 3;
BA_ "Version" SG_ 675 Usm_RpmSANDSet "20.02.04";
BA_ "Description" SG_ 675 CF_AVN_RemoteWDWNValueSet "Remote Window On/Off Set signal of USM for Fob Key";
BA_ "GenSigSendType" SG_ 675 CF_AVN_RemoteWDWNValueSet 4;
BA_ "UserSigValidity" SG_ 675 CF_AVN_RemoteWDWNValueSet 3;
BA_ "Version" SG_ 675 CF_AVN_RemoteWDWNValueSet "20.07.14";
BA_ "Description" SG_ 675 USM_TowWeight_Set "Trailer Mode Setting USM: Tow Weight set for User

-User can select the tow weight value for get the exact DTE value";
BA_ "GenSigSendType" SG_ 675 USM_TowWeight_Set 4;
BA_ "UserSigValidity" SG_ 675 USM_TowWeight_Set 7;
BA_ "Version" SG_ 675 USM_TowWeight_Set "20.10.02";
BA_ "Description" SG_ 675 CF_AVN_PABArbgNValueSet "USM PAB On/Off Set Signal";
BA_ "GenSigSendType" SG_ 675 CF_AVN_PABArbgNValueSet 4;
BA_ "UserSigValidity" SG_ 675 CF_AVN_PABArbgNValueSet 3;
BA_ "Version" SG_ 675 CF_AVN_PABArbgNValueSet "20.08.07";
BA_ "Description" SG_ 675 CF_AVN_SportHUD2 "Related to HUD Sports mode of custom mode2";
BA_ "GenSigSendType" SG_ 675 CF_AVN_SportHUD2 4;
BA_ "UserSigValidity" SG_ 675 CF_AVN_SportHUD2 3;
BA_ "Version" SG_ 675 CF_AVN_SportHUD2 "20.09.00";
BA_ "Description" SG_ 675 C_SLB_SmartCtrl_Set_Nvalue "USM time setting for Smart Posture Care 2.0  Off or 30min or 60min";
BA_ "GenSigSendType" SG_ 675 C_SLB_SmartCtrl_Set_Nvalue 4;
BA_ "UserSigValidity" SG_ 675 C_SLB_SmartCtrl_Set_Nvalue 3;
BA_REL_ "GenSigTimeoutTime" BU_SG_REL_ SLB SG_ 675 C_SLB_SmartCtrl_Set_Nvalue 0;
BA_REL_ "GenSigTimeoutTime" BU_SG_REL_ DLBCU SG_ 675 C_SLB_SmartCtrl_Set_Nvalue 0;
BA_ "Version" SG_ 675 C_SLB_SmartCtrl_Set_Nvalue "20.09.01";
BA_ "Description" SG_ 675 CF_AVN_ArHudLeftRightSet "AR Hud Left Right Set Signal";
BA_ "GenSigSendType" SG_ 675 CF_AVN_ArHudLeftRightSet 4;
BA_ "UserSigValidity" SG_ 675 CF_AVN_ArHudLeftRightSet 3;
BA_ "Version" SG_ 675 CF_AVN_ArHudLeftRightSet "20.09.01";
BA_ "Description" SG_ 675 HU_CustomNewMenuSet "Custom Mode User Setting Signal";
BA_ "GenSigSendType" SG_ 675 HU_CustomNewMenuSet 4;
BA_ "UserSigValidity" SG_ 675 HU_CustomNewMenuSet 3;
BA_ "Version" SG_ 675 HU_CustomNewMenuSet "20.09.00";
BA_ "Description" SG_ 675 CF_AVN_ArHudViewSet "AR Mode Height View Set Signal";
BA_ "GenSigSendType" SG_ 675 CF_AVN_ArHudViewSet 4;
BA_ "UserSigValidity" SG_ 675 CF_AVN_ArHudViewSet 3;
BA_ "Version" SG_ 675 CF_AVN_ArHudViewSet "20.09.01";
BA_ "Description" SG_ 675 USM_RpmComfortRearSet "RPM Display Setting When Comfort(Rear) mode Set";
BA_ "GenSigSendType" SG_ 675 USM_RpmComfortRearSet 4;
BA_ "UserSigValidity" SG_ 675 USM_RpmComfortRearSet 3;
BA_ "Version" SG_ 675 USM_RpmComfortRearSet "20.10.02";
BA_ "Description" SG_ 675 Usm_RpmMyDriveModeSet "Cluster MY Drive Mode RPM Set Signal";
BA_ "GenSigSendType" SG_ 675 Usm_RpmMyDriveModeSet 4;
BA_ "UserSigValidity" SG_ 675 Usm_RpmMyDriveModeSet 3;
BA_ "Version" SG_ 675 Usm_RpmMyDriveModeSet "20.11.00";
BA_ "Description" SG_ 675 CF_AVN_PCA_RrEquipNvalueSet "Headunit Setting signal for Rear Safety of USM";
BA_ "GenSigSendType" SG_ 675 CF_AVN_PCA_RrEquipNvalueSet 4;
BA_ "UserSigValidity" SG_ 675 CF_AVN_PCA_RrEquipNvalueSet 3;
BA_ "Version" SG_ 675 CF_AVN_PCA_RrEquipNvalueSet "20.06.04";
BA_ "GenMsgCycleTime" BO_ 1251 0;
BA_ "Description" SG_ 1251 IAU_EsyAcsProfileID "This signal indicate the current detected profile ID by NFC.

(The drv seat move to the easy access position of the detected profile ID when receive the signal)";
BA_ "GenSigSendType" SG_ 1251 IAU_EsyAcsProfileID 4;
BA_ "UserSigValidity" SG_ 1251 IAU_EsyAcsProfileID 0;
BA_REL_ "GenSigTimeoutTime" BU_SG_REL_ DPSU SG_ 1251 IAU_EsyAcsProfileID 0;
BA_ "NetworkRequest" SG_ 1251 IAU_EsyAcsProfileID 0;
BA_ "NetworkRequestHoldingTime" SG_ 1251 IAU_EsyAcsProfileID 5;
BA_ "Version" SG_ 1251 IAU_EsyAcsProfileID "18.08.12";
BA_ "Description" SG_ 1251 IAU_SmrtPhnID "SmartPhone ID with BLE Connection";
BA_ "GenSigSendType" SG_ 1251 IAU_SmrtPhnID 4;
BA_ "UserSigValidity" SG_ 1251 IAU_SmrtPhnID 0;
BA_ "NetworkRequest" SG_ 1251 IAU_SmrtPhnID 0;
BA_ "NetworkRequestHoldingTime" SG_ 1251 IAU_SmrtPhnID 5;
BA_ "Version" SG_ 1251 IAU_SmrtPhnID "20.04.06";
BA_ "Description" SG_ 1251 IAU_SmrtPhnCmd "SmartPhone RKE Command Indi";
BA_ "GenSigSendType" SG_ 1251 IAU_SmrtPhnCmd 4;
BA_ "UserSigValidity" SG_ 1251 IAU_SmrtPhnCmd 0;
BA_ "NetworkRequest" SG_ 1251 IAU_SmrtPhnCmd 0;
BA_ "NetworkRequestHoldingTime" SG_ 1251 IAU_SmrtPhnCmd 5;
BA_ "Version" SG_ 1251 IAU_SmrtPhnCmd "19.08.08";
BA_ "Description" SG_ 1251 IAUwFRU_ISK_LearningReq "This signal is to request ISK learning to FRU";
BA_ "GenSigSendType" SG_ 1251 IAUwFRU_ISK_LearningReq 4;
BA_ "UserSigValidity" SG_ 1251 IAUwFRU_ISK_LearningReq 0;
BA_ "NetworkRequest" SG_ 1251 IAUwFRU_ISK_LearningReq 0;
BA_ "NetworkRequestHoldingTime" SG_ 1251 IAUwFRU_ISK_LearningReq 5;
BA_ "Version" SG_ 1251 IAUwFRU_ISK_LearningReq "20.05.02";
BA_ "Description" SG_ 1251 IAUwFPM_ISK_LearningReq "This signal is to request ISK learning to FPM";
BA_ "GenSigSendType" SG_ 1251 IAUwFPM_ISK_LearningReq 4;
BA_ "UserSigValidity" SG_ 1251 IAUwFPM_ISK_LearningReq 0;
BA_ "NetworkRequest" SG_ 1251 IAUwFPM_ISK_LearningReq 0;
BA_ "NetworkRequestHoldingTime" SG_ 1251 IAUwFPM_ISK_LearningReq 5;
BA_ "Version" SG_ 1251 IAUwFPM_ISK_LearningReq "20.05.02";
BA_ "Description" SG_ 1251 IAU2FRU_ISKLearnFdbck "This isgnla is learning feedback";
BA_ "GenSigSendType" SG_ 1251 IAU2FRU_ISKLearnFdbck 4;
BA_ "UserSigValidity" SG_ 1251 IAU2FRU_ISKLearnFdbck 0;
BA_ "NetworkRequest" SG_ 1251 IAU2FRU_ISKLearnFdbck 0;
BA_ "NetworkRequestHoldingTime" SG_ 1251 IAU2FRU_ISKLearnFdbck 5;
BA_ "Version" SG_ 1251 IAU2FRU_ISKLearnFdbck "20.04.05";
BA_ "Description" SG_ 1251 IAU2FPM_ISKLearnFdbck "This signal is learning feedback";
BA_ "GenSigSendType" SG_ 1251 IAU2FPM_ISKLearnFdbck 4;
BA_ "UserSigValidity" SG_ 1251 IAU2FPM_ISKLearnFdbck 0;
BA_ "NetworkRequest" SG_ 1251 IAU2FPM_ISKLearnFdbck 0;
BA_ "NetworkRequestHoldingTime" SG_ 1251 IAU2FPM_ISKLearnFdbck 5;
BA_ "Version" SG_ 1251 IAU2FPM_ISKLearnFdbck "20.04.05";
BA_ "GenMsgSendType" BO_ 2172675329 0;
BA_ "GenMsgCycleTime" BO_ 2172675329 50;
BA_ "GenMsgCycleTimeFast" BO_ 2172675329 0;
BA_ "GenMsgNrOfRepetition" BO_ 2172675329 0;
BA_ "VFrameFormat" BO_ 2172675329 1;
BA_ "Description" SG_ 2172675329 IEB_Crc1Val "The data area for CRC calculation is based on the data length (DLC) of the message DB.

The CRC shall be calculated over the entire data block (excluding the CRC bytes) including the user data, alive counter and Data ID

 

- CRC Polynomial (0x1021) , Initial Value : 0xFFFF, XOR value : 0x0000, Data ID : Message ID + 0xF800 

- The initial value is for CRC calculation and the message should be sent with the calculated result value. 

- The mathematical expression to 16 bit CRC polynomial is given here. G(x) = x16 + x12 + x5 + 1";
BA_ "GenSigStartValue" SG_ 2172675329 IEB_Crc1Val 65535;
BA_ "UserSigValidity" SG_ 2172675329 IEB_Crc1Val 3;
BA_ "RoutingFactor" SG_ 2172675329 IEB_Crc1Val 5;
BA_ "Version" SG_ 2172675329 IEB_Crc1Val "19.05.02";
BA_ "Description" SG_ 2172675329 IEB_AlvCnt1Val "For the first transmission request for a data element the counter shall be initialized with 0 and shall be incremented by 1 for every subsequent send request. 

When the counter reaches the maximum value(0xFF), then it shall restart with 0 for the next send request";
BA_ "UserSigValidity" SG_ 2172675329 IEB_AlvCnt1Val 3;
BA_ "RoutingFactor" SG_ 2172675329 IEB_AlvCnt1Val 5;
BA_ "Version" SG_ 2172675329 IEB_AlvCnt1Val "19.05.02";
BA_ "Description" SG_ 2172675329 IEB_SrvLmpDis "The signal indicates the status of the ¡°AHB Service lamp¡±";
BA_ "UserSigValidity" SG_ 2172675329 IEB_SrvLmpDis 3;
BA_ "RoutingFactor" SG_ 2172675329 IEB_SrvLmpDis 5;
BA_ "Version" SG_ 2172675329 IEB_SrvLmpDis "19.05.02";
BA_ "Description" SG_ 2172675329 IEB_DfctvSta "Information regarding the AHB 'defective' indication.";
BA_ "UserSigValidity" SG_ 2172675329 IEB_DfctvSta 3;
BA_ "RoutingFactor" SG_ 2172675329 IEB_DfctvSta 5;
BA_ "Version" SG_ 2172675329 IEB_DfctvSta "19.05.02";
BA_ "Description" SG_ 2172675329 IEB_ActvSta "Information regarding AHB ¡°Control Active¡± signal";
BA_ "UserSigValidity" SG_ 2172675329 IEB_ActvSta 3;
BA_ "RoutingFactor" SG_ 2172675329 IEB_ActvSta 5;
BA_ "Version" SG_ 2172675329 IEB_ActvSta "19.05.02";
BA_ "Description" SG_ 2172675329 IEB_DiagSta "Information regarding the AHB ¡°diagnostic mode¡± indication.";
BA_ "UserSigValidity" SG_ 2172675329 IEB_DiagSta 3;
BA_ "RoutingFactor" SG_ 2172675329 IEB_DiagSta 5;
BA_ "Version" SG_ 2172675329 IEB_DiagSta "19.05.02";
BA_ "Description" SG_ 2172675329 IEB_WrngLmpDis "The signal indicates the status of the ¡°AHB Warning lamp¡±";
BA_ "UserSigValidity" SG_ 2172675329 IEB_WrngLmpDis 3;
BA_ "RoutingFactor" SG_ 2172675329 IEB_WrngLmpDis 5;
BA_ "Version" SG_ 2172675329 IEB_WrngLmpDis "19.05.02";
BA_ "Description" SG_ 2172675329 IEB_MILReq "IEB sends this signal to turn on the Malfunction Indicator Lamp (MIL).";
BA_ "UserSigValidity" SG_ 2172675329 IEB_MILReq 3;
BA_ "RoutingFactor" SG_ 2172675329 IEB_MILReq 5;
BA_ "Version" SG_ 2172675329 IEB_MILReq "19.05.02";
BA_ "Description" SG_ 2172675329 IEB_StrkDpthmmVal "The signal indicates the depth of brake pedal";
BA_ "UserSigValidity" SG_ 2172675329 IEB_StrkDpthmmVal 3;
BA_ "RoutingFactor" SG_ 2172675329 IEB_StrkDpthmmVal 5;
BA_ "Version" SG_ 2172675329 IEB_StrkDpthmmVal "19.05.02";
BA_ "Description" SG_ 2172675329 IEB_BrkActvSta "This signal indicates that a brake switch is activated or not. When the brake switch is activated(pressed) its value is 02H otherwise its value is 01H.

If the ECU does not support this signal the value is 00H.



ÀÌ ½ÅÈ£´Â EV, FCEV ¿¡¼­¸¸ »ç¿ëµÉ ¼ö ÀÖÀ½.

This signal can be used in EV or FCEV vehicle.";
BA_ "UserSigValidity" SG_ 2172675329 IEB_BrkActvSta 3;
BA_ "RoutingFactor" SG_ 2172675329 IEB_BrkActvSta 5;
BA_ "Version" SG_ 2172675329 IEB_BrkActvSta "19.05.05";
BA_ "Description" SG_ 2172675329 IEB_PdlTrvlSnsrFailSta "Information regarding the pedal travel sensor fail status";
BA_ "UserSigValidity" SG_ 2172675329 IEB_PdlTrvlSnsrFailSta 3;
BA_ "RoutingFactor" SG_ 2172675329 IEB_PdlTrvlSnsrFailSta 5;
BA_ "Version" SG_ 2172675329 IEB_PdlTrvlSnsrFailSta "19.05.02";
BA_ "Description" SG_ 2172675329 IEB_PdlCalibSta "Information regarding the pedal travel sensor¡¯s calibration status";
BA_ "UserSigValidity" SG_ 2172675329 IEB_PdlCalibSta 3;
BA_ "RoutingFactor" SG_ 2172675329 IEB_PdlCalibSta 5;
BA_ "Version" SG_ 2172675329 IEB_PdlCalibSta "19.05.02";
BA_ "Description" SG_ 2172675329 IEB_BzrSta "The signal indicates the status of the ¡°Buzzer¡±";
BA_ "UserSigValidity" SG_ 2172675329 IEB_BzrSta 3;
BA_ "RoutingFactor" SG_ 2172675329 IEB_BzrSta 5;
BA_ "Version" SG_ 2172675329 IEB_BzrSta "19.05.02";
BA_ "GenMsgSendType" BO_ 2172675332 0;
BA_ "GenMsgCycleTime" BO_ 2172675332 50;
BA_ "GenMsgCycleTimeFast" BO_ 2172675332 0;
BA_ "GenMsgNrOfRepetition" BO_ 2172675332 0;
BA_ "VFrameFormat" BO_ 2172675332 1;
BA_ "Description" SG_ 2172675332 TCS_MtrTrgtRpm_Flag_Frnt "ÀÌ ½ÅÈ£´Â IEB_01_10ms ¸Þ½ÃÁöÀÇ TCS ÀÛµ¿½Ã Àü·û ¸ðÅÍÀÇ Å¸°Ù RPM ½ÅÈ£(TCS_MtrTrgtRpm_Frnt)¿¡ ´ëÇÑ ºÎÈ£¸¦ ÀÇ¹ÌÇÑ´Ù.";
BA_ "UserSigValidity" SG_ 2172675332 TCS_MtrTrgtRpm_Flag_Frnt 3;
BA_ "RoutingFactor" SG_ 2172675332 TCS_MtrTrgtRpm_Flag_Frnt 5;
BA_ "Version" SG_ 2172675332 TCS_MtrTrgtRpm_Flag_Frnt "20.04.05";
BA_ "Description" SG_ 2172675332 TCS_MtrTrgtRpm_Flag_Rear "ÀÌ ½ÅÈ£´Â IEB_01_10ms ¸Þ½ÃÁöÀÇ TCS ÀÛµ¿½Ã ÈÄ·û ¸ðÅÍÀÇ Å¸°Ù RPM ½ÅÈ£(TCS_MtrTrgtRpm_Rear)¿¡ ´ëÇÑ ºÎÈ£¸¦ ÀÇ¹ÌÇÑ´Ù.";
BA_ "UserSigValidity" SG_ 2172675332 TCS_MtrTrgtRpm_Flag_Rear 3;
BA_ "RoutingFactor" SG_ 2172675332 TCS_MtrTrgtRpm_Flag_Rear 5;
BA_ "Version" SG_ 2172675332 TCS_MtrTrgtRpm_Flag_Rear "20.04.05";
BA_ "Description" SG_ 2172675332 TCS_MtrTrgtRpm_Rear "TCS Á¦¾î¸¦ À§ÇÑ ÈÄ·û ¸ðÅÍÀÇ RPM ¿ä±¸°ªÀ» ÀÇ¹Ì.

ºÎÈ£´Â TCS_MtrTrgtRpm_Flag_Rear ½ÅÈ£¸¦ ÂüÁ¶.";
BA_ "UserSigValidity" SG_ 2172675332 TCS_MtrTrgtRpm_Rear 3;
BA_ "RoutingFactor" SG_ 2172675332 TCS_MtrTrgtRpm_Rear 5;
BA_ "Version" SG_ 2172675332 TCS_MtrTrgtRpm_Rear "20.04.05";
BA_ "Description" SG_ 2172675332 IEB_DriftModeSta "This signal is for a pop-up display on drift mode.";
BA_ "UserSigValidity" SG_ 2172675332 IEB_DriftModeSta 3;
BA_ "RoutingFactor" SG_ 2172675332 IEB_DriftModeSta 5;
BA_ "Version" SG_ 2172675332 IEB_DriftModeSta "20.12.02";
BA_ "Description" SG_ 2172675332 IEB_DriftModeActSta "This signal is for drift mode ON/OFF status";
BA_ "UserSigValidity" SG_ 2172675332 IEB_DriftModeActSta 3;
BA_ "RoutingFactor" SG_ 2172675332 IEB_DriftModeActSta 5;
BA_ "Version" SG_ 2172675332 IEB_DriftModeActSta "20.12.02";
BA_ "Description" SG_ 2172675332 TCS_MtrTrgtRpm_Frnt "TCS Á¦¾î¸¦ À§ÇÑ Àü·û ¸ðÅÍÀÇ RPM ¿ä±¸°ªÀ» ÀÇ¹Ì.

ºÎÈ£´Â TCS_MtrTrgtRpm_Flag_Frnt ½ÅÈ£¸¦ ÂüÁ¶.";
BA_ "UserSigValidity" SG_ 2172675332 TCS_MtrTrgtRpm_Frnt 3;
BA_ "RoutingFactor" SG_ 2172675332 TCS_MtrTrgtRpm_Frnt 5;
BA_ "Version" SG_ 2172675332 TCS_MtrTrgtRpm_Frnt "20.04.05";
BA_ "GenMsgCycleTime" BO_ 1227 0;
BA_ "Description" SG_ 1227 DrvIMS_MemoryP1Req "-(Old)C_MEMP1CMD";
BA_ "GenSigSendType" SG_ 1227 DrvIMS_MemoryP1Req 4;
BA_ "UserSigValidity" SG_ 1227 DrvIMS_MemoryP1Req 0;
BA_REL_ "GenSigTimeoutTime" BU_SG_REL_ CGW_CCU SG_ 1227 DrvIMS_MemoryP1Req 0;
BA_ "NetworkRequest" SG_ 1227 DrvIMS_MemoryP1Req 0;
BA_ "NetworkRequestHoldingTime" SG_ 1227 DrvIMS_MemoryP1Req 5000;
BA_ "Version" SG_ 1227 DrvIMS_MemoryP1Req "17.11.00";
BA_ "GenSigSendType" SG_ 1227 DrvIMS_PlyBckP2Req 4;
BA_ "UserSigValidity" SG_ 1227 DrvIMS_PlyBckP2Req 0;
BA_REL_ "GenSigTimeoutTime" BU_SG_REL_ CGW_CCU SG_ 1227 DrvIMS_PlyBckP2Req 0;
BA_ "NetworkRequest" SG_ 1227 DrvIMS_PlyBckP2Req 0;
BA_ "NetworkRequestHoldingTime" SG_ 1227 DrvIMS_PlyBckP2Req 5000;
BA_ "Version" SG_ 1227 DrvIMS_PlyBckP2Req "17.11.00";
BA_ "Description" SG_ 1227 DrvIMS_PlyBckP3Req "PLAY IMS3";
BA_ "GenSigSendType" SG_ 1227 DrvIMS_PlyBckP3Req 4;
BA_ "UserSigValidity" SG_ 1227 DrvIMS_PlyBckP3Req 0;
BA_REL_ "GenSigTimeoutTime" BU_SG_REL_ CGW_CCU SG_ 1227 DrvIMS_PlyBckP3Req 0;
BA_ "NetworkRequest" SG_ 1227 DrvIMS_PlyBckP3Req 0;
BA_ "NetworkRequestHoldingTime" SG_ 1227 DrvIMS_PlyBckP3Req 5000;
BA_ "Version" SG_ 1227 DrvIMS_PlyBckP3Req "17.11.00";
BA_ "Description" SG_ 1227 DrvIMS_PlyBckStpReq "This signal is used to stop during playback";
BA_ "GenSigSendType" SG_ 1227 DrvIMS_PlyBckStpReq 4;
BA_ "UserSigValidity" SG_ 1227 DrvIMS_PlyBckStpReq 0;
BA_REL_ "GenSigTimeoutTime" BU_SG_REL_ CGW_CCU SG_ 1227 DrvIMS_PlyBckStpReq 0;
BA_ "NetworkRequest" SG_ 1227 DrvIMS_PlyBckStpReq 0;
BA_ "NetworkRequestHoldingTime" SG_ 1227 DrvIMS_PlyBckStpReq 5000;
BA_ "Version" SG_ 1227 DrvIMS_PlyBckStpReq "17.11.00";
BA_ "Description" SG_ 1227 SmrtIMS_PlyBckReq "Signal for Health Care IMS Playback DB Number";
BA_ "GenSigSendType" SG_ 1227 SmrtIMS_PlyBckReq 4;
BA_ "UserSigValidity" SG_ 1227 SmrtIMS_PlyBckReq 0;
BA_REL_ "GenSigTimeoutTime" BU_SG_REL_ CGW_CCU SG_ 1227 SmrtIMS_PlyBckReq 0;
BA_ "NetworkRequest" SG_ 1227 SmrtIMS_PlyBckReq 0;
BA_ "NetworkRequestHoldingTime" SG_ 1227 SmrtIMS_PlyBckReq 5000;
BA_ "Version" SG_ 1227 SmrtIMS_PlyBckReq "21.07.05";
BA_ "Description" SG_ 1227 DrvIMS_MemoryP2Req "-(Old)C_MEMP2CMD";
BA_ "GenSigSendType" SG_ 1227 DrvIMS_MemoryP2Req 4;
BA_ "UserSigValidity" SG_ 1227 DrvIMS_MemoryP2Req 0;
BA_REL_ "GenSigTimeoutTime" BU_SG_REL_ CGW_CCU SG_ 1227 DrvIMS_MemoryP2Req 0;
BA_ "NetworkRequest" SG_ 1227 DrvIMS_MemoryP2Req 0;
BA_ "NetworkRequestHoldingTime" SG_ 1227 DrvIMS_MemoryP2Req 5000;
BA_ "Version" SG_ 1227 DrvIMS_MemoryP2Req "17.11.00";
BA_ "Description" SG_ 1227 PSM_IMSReq "IMS request";
BA_ "GenSigSendType" SG_ 1227 PSM_IMSReq 4;
BA_ "UserSigValidity" SG_ 1227 PSM_IMSReq 0;
BA_REL_ "GenSigTimeoutTime" BU_SG_REL_ CGW_CCU SG_ 1227 PSM_IMSReq 0;
BA_ "NetworkRequest" SG_ 1227 PSM_IMSReq 0;
BA_ "NetworkRequestHoldingTime" SG_ 1227 PSM_IMSReq 5000;
BA_ "Version" SG_ 1227 PSM_IMSReq "21.02.02";
BA_ "Description" SG_ 1227 SmrtIMS_ImgDBVal "-(Old)C_SmartIMSImageDB";
BA_ "GenSigSendType" SG_ 1227 SmrtIMS_ImgDBVal 4;
BA_ "UserSigValidity" SG_ 1227 SmrtIMS_ImgDBVal 0;
BA_REL_ "GenSigTimeoutTime" BU_SG_REL_ CGW_CCU SG_ 1227 SmrtIMS_ImgDBVal 0;
BA_ "NetworkRequest" SG_ 1227 SmrtIMS_ImgDBVal 0;
BA_ "NetworkRequestHoldingTime" SG_ 1227 SmrtIMS_ImgDBVal 5000;
BA_ "Version" SG_ 1227 SmrtIMS_ImgDBVal "17.11.00";
BA_ "Description" SG_ 1227 SmrtIMS_PlyBckStpReq "Health Care IMS On/Off Flag";
BA_ "GenSigSendType" SG_ 1227 SmrtIMS_PlyBckStpReq 4;
BA_ "UserSigValidity" SG_ 1227 SmrtIMS_PlyBckStpReq 0;
BA_REL_ "GenSigTimeoutTime" BU_SG_REL_ CGW_CCU SG_ 1227 SmrtIMS_PlyBckStpReq 0;
BA_ "NetworkRequest" SG_ 1227 SmrtIMS_PlyBckStpReq 0;
BA_ "NetworkRequestHoldingTime" SG_ 1227 SmrtIMS_PlyBckStpReq 5000;
BA_ "Version" SG_ 1227 SmrtIMS_PlyBckStpReq "17.11.00";
BA_ "Description" SG_ 1227 DrvIMS_MemoryP3Req "Memory IMS3";
BA_ "GenSigSendType" SG_ 1227 DrvIMS_MemoryP3Req 4;
BA_ "UserSigValidity" SG_ 1227 DrvIMS_MemoryP3Req 0;
BA_REL_ "GenSigTimeoutTime" BU_SG_REL_ CGW_CCU SG_ 1227 DrvIMS_MemoryP3Req 0;
BA_ "NetworkRequest" SG_ 1227 DrvIMS_MemoryP3Req 0;
BA_ "NetworkRequestHoldingTime" SG_ 1227 DrvIMS_MemoryP3Req 5000;
BA_ "Version" SG_ 1227 DrvIMS_MemoryP3Req "17.11.00";
BA_ "Description" SG_ 1227 SmrtIMS_EnterSwSta "-(Old)C_SmartIMSOn";
BA_ "GenSigSendType" SG_ 1227 SmrtIMS_EnterSwSta 4;
BA_ "UserSigValidity" SG_ 1227 SmrtIMS_EnterSwSta 0;
BA_REL_ "GenSigTimeoutTime" BU_SG_REL_ CGW_CCU SG_ 1227 SmrtIMS_EnterSwSta 0;
BA_ "NetworkRequest" SG_ 1227 SmrtIMS_EnterSwSta 0;
BA_ "NetworkRequestHoldingTime" SG_ 1227 SmrtIMS_EnterSwSta 5000;
BA_ "Version" SG_ 1227 SmrtIMS_EnterSwSta "17.11.00";
BA_ "Description" SG_ 1227 DrvIMS_BzrReq "IMS ºÎÁ®À½À» Å¬·¯½ºÅÍ ½ºÇÇÄ¿¿¡¼­ Ãâ·ÂÇÏ±â À§ÇÑ ½Ã±×³Î";
BA_ "GenSigSendType" SG_ 1227 DrvIMS_BzrReq 4;
BA_ "UserSigValidity" SG_ 1227 DrvIMS_BzrReq 0;
BA_REL_ "GenSigTimeoutTime" BU_SG_REL_ CGW_CCU SG_ 1227 DrvIMS_BzrReq 0;
BA_ "NetworkRequest" SG_ 1227 DrvIMS_BzrReq 0;
BA_ "NetworkRequestHoldingTime" SG_ 1227 DrvIMS_BzrReq 5000;
BA_ "Version" SG_ 1227 DrvIMS_BzrReq "17.11.00";
BA_ "Description" SG_ 1227 DrvIMS_ErrConWmgDis "IMS ±â¾ï/Àç»ý Á¶°Ç ¿¡·¯ Ãâ·Â ½Ã±×³Î";
BA_ "GenSigSendType" SG_ 1227 DrvIMS_ErrConWmgDis 4;
BA_ "UserSigValidity" SG_ 1227 DrvIMS_ErrConWmgDis 0;
BA_REL_ "GenSigTimeoutTime" BU_SG_REL_ CGW_CCU SG_ 1227 DrvIMS_ErrConWmgDis 0;
BA_ "NetworkRequest" SG_ 1227 DrvIMS_ErrConWmgDis 0;
BA_ "NetworkRequestHoldingTime" SG_ 1227 DrvIMS_ErrConWmgDis 5000;
BA_ "Version" SG_ 1227 DrvIMS_ErrConWmgDis "18.07.01";
BA_ "Description" SG_ 1227 PSM_DrvRlxReturn_Req "one touch relax play and return";
BA_ "GenSigSendType" SG_ 1227 PSM_DrvRlxReturn_Req 4;
BA_ "UserSigValidity" SG_ 1227 PSM_DrvRlxReturn_Req 0;
BA_REL_ "GenSigTimeoutTime" BU_SG_REL_ CGW_CCU SG_ 1227 PSM_DrvRlxReturn_Req 0;
BA_ "NetworkRequest" SG_ 1227 PSM_DrvRlxReturn_Req 0;
BA_ "NetworkRequestHoldingTime" SG_ 1227 PSM_DrvRlxReturn_Req 5000;
BA_ "Version" SG_ 1227 PSM_DrvRlxReturn_Req "20.07.02";
BA_ "GenSigSendType" SG_ 1227 Drv_AutoRlxWrngDis 4;
BA_ "UserSigValidity" SG_ 1227 Drv_AutoRlxWrngDis 1;
BA_REL_ "GenSigTimeoutTime" BU_SG_REL_ CGW_CCU SG_ 1227 Drv_AutoRlxWrngDis 0;
BA_ "NetworkRequest" SG_ 1227 Drv_AutoRlxWrngDis 0;
BA_ "NetworkRequestHoldingTime" SG_ 1227 Drv_AutoRlxWrngDis 5000;
BA_ "Version" SG_ 1227 Drv_AutoRlxWrngDis "21.06.10";
BA_ "Description" SG_ 1227 DrvIMS_MemorySetEnaSta "-(Old)C_MEMENB";
BA_ "GenSigSendType" SG_ 1227 DrvIMS_MemorySetEnaSta 4;
BA_ "UserSigValidity" SG_ 1227 DrvIMS_MemorySetEnaSta 0;
BA_REL_ "GenSigTimeoutTime" BU_SG_REL_ CGW_CCU SG_ 1227 DrvIMS_MemorySetEnaSta 0;
BA_ "NetworkRequest" SG_ 1227 DrvIMS_MemorySetEnaSta 0;
BA_ "NetworkRequestHoldingTime" SG_ 1227 DrvIMS_MemorySetEnaSta 5000;
BA_ "Version" SG_ 1227 DrvIMS_MemorySetEnaSta "17.11.00";
BA_ "GenSigSendType" SG_ 1227 DrvIMS_PlyBckP1Req 4;
BA_ "UserSigValidity" SG_ 1227 DrvIMS_PlyBckP1Req 0;
BA_REL_ "GenSigTimeoutTime" BU_SG_REL_ CGW_CCU SG_ 1227 DrvIMS_PlyBckP1Req 0;
BA_ "NetworkRequest" SG_ 1227 DrvIMS_PlyBckP1Req 0;
BA_ "NetworkRequestHoldingTime" SG_ 1227 DrvIMS_PlyBckP1Req 5000;
BA_ "Version" SG_ 1227 DrvIMS_PlyBckP1Req "17.11.00";
BA_ "GenMsgCycleTime" BO_ 1252 0;
BA_ "Description" SG_ 1252 RKE_Crc1Val "The data area for CRC calculation is based on the data length (DLC) of the message DB.

The CRC shall be calculated over the entire data block (excluding the CRC bytes) including the user data, alive counter and Data ID 

 

- CRC Polynomial (0x1D) , Initial Value : 0x00, XOR value : 0xFF, Data ID Mode : Both, Data ID : Message ID + 0xF800 

- The initial value is for CRC calculation and the message should be sent with the calculated result value. 

The mathematical expression to 8 bit CRC polynomial is given here. G(x) = x8 + x4 + x3 + x2 + 1";
BA_ "GenSigSendType" SG_ 1252 RKE_Crc1Val 4;
BA_ "GenSigStartValue" SG_ 1252 RKE_Crc1Val 255;
BA_ "UserSigValidity" SG_ 1252 RKE_Crc1Val 0;
BA_ "Version" SG_ 1252 RKE_Crc1Val "18.11.08";
BA_ "Description" SG_ 1252 RKE_AlvCnt1Val "For the first transmission request for a data element the counter shall be initialized with 0 and shall be incremented by 1

for every subsequent send request. When the counter reaches the maximum value(0xE), then it shall restart with 0 for the next send request";
BA_ "GenSigSendType" SG_ 1252 RKE_AlvCnt1Val 4;
BA_ "UserSigValidity" SG_ 1252 RKE_AlvCnt1Val 0;
BA_ "Version" SG_ 1252 RKE_AlvCnt1Val "18.11.08";
BA_ "Description" SG_ 1252 RKE_BtnReq "Remote Key Button Request from Folding Key or Smart Key";
BA_ "GenSigSendType" SG_ 1252 RKE_BtnReq 4;
BA_ "UserSigValidity" SG_ 1252 RKE_BtnReq 0;
BA_REL_ "GenSigTimeoutTime" BU_SG_REL_ ATS SG_ 1252 RKE_BtnReq 0;
BA_ "NetworkRequest" SG_ 1252 RKE_BtnReq 0;
BA_ "NetworkRequestHoldingTime" SG_ 1252 RKE_BtnReq 5000;
BA_ "Version" SG_ 1252 RKE_BtnReq "20.12.00";
BA_ "Description" SG_ 1252 RKE_PsdBtnReq "Remote Key Power Sliding Door Button Request from Folding Key or Smart Key";
BA_ "GenSigSendType" SG_ 1252 RKE_PsdBtnReq 4;
BA_ "UserSigValidity" SG_ 1252 RKE_PsdBtnReq 0;
BA_ "NetworkRequest" SG_ 1252 RKE_PsdBtnReq 0;
BA_ "NetworkRequestHoldingTime" SG_ 1252 RKE_PsdBtnReq 5000;
BA_ "Version" SG_ 1252 RKE_PsdBtnReq "17.12.00";
BA_ "Description" SG_ 1252 RKE_WdwUpDnReq "Remote Key Window Up and Down Request from Folding Key or Smart Key";
BA_ "GenSigSendType" SG_ 1252 RKE_WdwUpDnReq 4;
BA_ "UserSigValidity" SG_ 1252 RKE_WdwUpDnReq 0;
BA_REL_ "GenSigTimeoutTime" BU_SG_REL_ RCM SG_ 1252 RKE_WdwUpDnReq 0;
BA_ "NetworkRequest" SG_ 1252 RKE_WdwUpDnReq 0;
BA_ "NetworkRequestHoldingTime" SG_ 1252 RKE_WdwUpDnReq 5000;
BA_ "Version" SG_ 1252 RKE_WdwUpDnReq "17.12.00";
BA_ "Description" SG_ 1252 RKE_TrnkTlgtBtnReq "This signal for Tailgate or Trunk open CMD

While RKE Tailgate(Trunk) Button push, This Signal Tx On

While Tailgate(Trunk) Button released, This Signal Tx Off";
BA_ "GenSigSendType" SG_ 1252 RKE_TrnkTlgtBtnReq 4;
BA_ "UserSigValidity" SG_ 1252 RKE_TrnkTlgtBtnReq 0;
BA_ "NetworkRequest" SG_ 1252 RKE_TrnkTlgtBtnReq 0;
BA_ "NetworkRequestHoldingTime" SG_ 1252 RKE_TrnkTlgtBtnReq 5000;
BA_ "Version" SG_ 1252 RKE_TrnkTlgtBtnReq "18.07.01";
BA_ "Description" SG_ 1252 RKE_ID "Remote Key Window Up and Down Request from Folding Key or Smart Key



Folding key or smart key ID for recently received RF frame";
BA_ "GenSigSendType" SG_ 1252 RKE_ID 4;
BA_ "UserSigValidity" SG_ 1252 RKE_ID 0;
BA_ "Version" SG_ 1252 RKE_ID "17.12.00";
BA_ "Description" SG_ 1252 RKE_PwrDrAllOpnClsReq "Remote Key Button Signal for PSD and PTG opening or closing together";
BA_ "GenSigSendType" SG_ 1252 RKE_PwrDrAllOpnClsReq 4;
BA_ "UserSigValidity" SG_ 1252 RKE_PwrDrAllOpnClsReq 0;
BA_ "NetworkRequest" SG_ 1252 RKE_PwrDrAllOpnClsReq 0;
BA_ "NetworkRequestHoldingTime" SG_ 1252 RKE_PwrDrAllOpnClsReq 5000;
BA_ "Version" SG_ 1252 RKE_PwrDrAllOpnClsReq "19.04.04";
BA_ "GenMsgCycleTime" BO_ 1237 0;
BA_ "Description" SG_ 1237 SWRC_Crc2Val "The data area for CRC calculation is based on the data length (DLC) of the message DB.

The CRC shall be calculated over the entire data block (excluding the CRC bytes) including the user data, alive counter and Data ID 

 

- CRC Polynomial (0x1D) , Initial Value : 0x00, XOR value : 0xFF, Data ID Mode : Both, Data ID : Message ID + 0xF800 

- The initial value is for CRC calculation and the message should be sent with the calculated result value. 

The mathematical expression to 8 bit CRC polynomial is given here. G(x) = x8 + x4 + x3 + x2 + 1";
BA_ "GenSigSendType" SG_ 1237 SWRC_Crc2Val 4;
BA_ "GenSigStartValue" SG_ 1237 SWRC_Crc2Val 255;
BA_ "UserSigValidity" SG_ 1237 SWRC_Crc2Val 0;
BA_ "Version" SG_ 1237 SWRC_Crc2Val "19.11.02";
BA_ "Description" SG_ 1237 SWRC_AlvCnt2Val "For the first transmission request for a data element the counter shall be initialized with 0 and shall be incremented by 1

for every subsequent send request. When the counter reaches the maximum value(0xE), then it shall restart with 0 for the next send request";
BA_ "GenSigSendType" SG_ 1237 SWRC_AlvCnt2Val 4;
BA_ "UserSigValidity" SG_ 1237 SWRC_AlvCnt2Val 0;
BA_ "Version" SG_ 1237 SWRC_AlvCnt2Val "19.11.02";
BA_ "Description" SG_ 1237 Audio_VolEncoderSta "Audio Volume switch

MM-CAN Gateway needed";
BA_ "GenSigSendType" SG_ 1237 Audio_VolEncoderSta 4;
BA_ "UserSigValidity" SG_ 1237 Audio_VolEncoderSta 0;
BA_REL_ "GenSigTimeoutTime" BU_SG_REL_ CGW_CCU SG_ 1237 Audio_VolEncoderSta 0;
BA_ "NetworkRequest" SG_ 1237 Audio_VolEncoderSta 0;
BA_ "NetworkRequestHoldingTime" SG_ 1237 Audio_VolEncoderSta 5000;
BA_ "Version" SG_ 1237 Audio_VolEncoderSta "19.11.02";
BA_ "Description" SG_ 1237 Cluster_ScrlEncoderSta "Cluster Trip Switch";
BA_ "GenSigSendType" SG_ 1237 Cluster_ScrlEncoderSta 4;
BA_ "UserSigValidity" SG_ 1237 Cluster_ScrlEncoderSta 0;
BA_REL_ "GenSigTimeoutTime" BU_SG_REL_ CGW_CCU SG_ 1237 Cluster_ScrlEncoderSta 0;
BA_ "NetworkRequest" SG_ 1237 Cluster_ScrlEncoderSta 0;
BA_ "NetworkRequestHoldingTime" SG_ 1237 Cluster_ScrlEncoderSta 5000;
BA_ "Version" SG_ 1237 Cluster_ScrlEncoderSta "19.11.02";
VAL_ 694 ASAU_NotFootMsgOperStaWarn 0 "OFF" 1 "ON" 2 "Reserved" 3 "Reserved" ;
VAL_ 678 Ast_AutoRlxWrngDis 0 "Off" 1 "Auto relax Enable" 2 "Mode-Fail (Vehicle Speed Warning)" 3 "Mode-Fail (Not P Warning)" 4 "Mode-Fail (2nd Seat Belted)" 5 "Mode-Fail (Not Initialized)" 6 "Mode-Fail (2nd Seat Position Warning)" 7 "Invaild" ;
VAL_ 678 APSM_IMSWngDis 0 "Default" 1 "Inhibit Ast IMS" 2 "Reserved" 3 "Invaild" ;
VAL_ 158 ATS_DATC_FrDrBlowerSet 0 "DATC Off" 1 "0 level (Do not use)" 2 "1 level" 3 "2 level" 4 "3level" 5 "4 level" 6 "5 level" 7 "6 level" 8 "7 level" 9 "8 level" 15 "Invalid" ;
VAL_ 158 ATS_DATC_RrDrTempUpDn 0 "Reserved" 1 "Temp Up" 2 "Temp Down" 3 "Invalid" ;
VAL_ 158 ATS_DATC_RrDrBlowerSet 0 "Off" 1 "0 level" 2 "1 level" 3 "2 level" 4 "3 level" 5 "4 level" 6 "5 level" 7 "6 level" 8 "7 level" 9 "8 level" 14 "reserved" 15 "Invalid" ;
VAL_ 158 ATS_DATC_RrDrModeSet 0 "Off" 1 "VENT" 2 "BL" 3 "FLOOR" 12 "reserved" 13 "reserved" 14 "reserved" 15 "Invalid" ;
VAL_ 158 ATS_DATC_FrDrModeSet 0 "Reserved" 1 "VENT" 2 "BL" 3 "FLOOR" 4 "MIX" 5 "reserved" 6 "reserved" 7 "7 Mode DEF VENT" 8 "reserved" 9 "MODE DEF VENT FLOOR" 10 "7 Mode DEF" 11 "Reserved" 12 "Reserved" 13 "Reserved" 14 "Reserved" 15 "Invalid" ;
VAL_ 158 ATS_DATC_RrOnOffSet 0 "Function Off" 1 "Function On" 2 "reserved" 3 "Invalid" ;
VAL_ 158 ATS_DATC_IntakeSet 0 "REC Off (Fresh On)" 1 "REC ON (Fresh Off)" 2 "reserved" 3 "Invalid" ;
VAL_ 158 ATS_DATC_OffReq 0 "Reserved" 1 "Request" 2 "reserved" 3 "Invalid" ;
VAL_ 158 ATS_DATC_FrDrAutoSet 0 "reserved" 1 "AUTO ON" 2 "reserved" 3 "Invalid" ;
VAL_ 158 ATS_DATC_FrPsTempUpDn 0 "Reserved" 1 "Temp Up" 2 "Temp Down" 3 "Invalid" ;
VAL_ 158 ATS_DATC_FrDefog 0 "Defog Off" 1 "Defog On" 2 "reserved" 3 "Invalid" ;
VAL_ 158 ATS_DATC_RrSyncSet 0 "Reserved" 1 "NOT SYNC" 2 "Rear SYNC" 3 "Invalid" ;
VAL_ 158 ATS_DATC_AcSet 0 "AC Off" 1 "AC ON" 2 "reserved" 3 "Invalid" ;
VAL_ 158 ATS_DATC_AirCleaningSet 0 "Air Cleaning System Off" 1 "Air Cleaning System On" 2 "Air Cleaning System Not Support" 3 "Invalid" ;
VAL_ 158 ATS_DATC_FrDrBlowerUpDn 0 "Reserved" 1 "Up" 2 "Down" 3 "Invalid" ;
VAL_ 158 ATS_DATC_FrDrTempUpDn 0 "Reserved" 1 "Temp Up" 2 "Temp Down" 3 "Invalid" ;
VAL_ 158 ATS_DATC_RrDrAutoSet 0 "Auto Off" 1 "Auto On" 2 "Not Used" 3 "Invalid" ;
VAL_ 157 ATS_DATC_FrDrTempSetC 0 "Blank" 1 "LO" 2 "PHY=HEX*0.5 + 14" 3 "PHY=HEX*0.5 + 14" 4 "PHY=HEX*0.5 + 14" 5 "PHY=HEX*0.5 + 14" 6 "PHY=HEX*0.5 + 14" 7 "PHY=HEX*0.5 + 14" 8 "PHY=HEX*0.5 + 14" 9 "PHY=HEX*0.5 + 14" 10 "PHY=HEX*0.5 + 14" 11 "PHY=HEX*0.5 + 14" 12 "PHY=HEX*0.5 + 14" 13 "PHY=HEX*0.5 + 14" 14 "PHY=HEX*0.5 + 14" 15 "PHY=HEX*0.5 + 14" 16 "PHY=HEX*0.5 + 14" 17 "PHY=HEX*0.5 + 14" 18 "PHY=HEX*0.5 + 14" 19 "PHY=HEX*0.5 + 14" 20 "PHY=HEX*0.5 + 14" 21 "PHY=HEX*0.5 + 14" 22 "PHY=HEX*0.5 + 14" 23 "PHY=HEX*0.5 + 14" 24 "PHY=HEX*0.5 + 14" 25 "PHY=HEX*0.5 + 14" 26 "PHY=HEX*0.5 + 14" 27 "PHY=HEX*0.5 + 14" 28 "PHY=HEX*0.5 + 14" 29 "PHY=HEX*0.5 + 14" 30 "PHY=HEX*0.5 + 14" 31 "PHY=HEX*0.5 + 14" 32 "PHY=HEX*0.5 + 14" 33 "PHY=HEX*0.5 + 14" 34 "PHY=HEX*0.5 + 14" 35 "PHY=HEX*0.5 + 14" 36 "PHY=HEX*0.5 + 14" 37 "0x25~0xFD:Reserved" 253 "0x25~0xFD:Reserved" 254 "HI" 255 "Invalid" ;
VAL_ 157 ATS_DATC_RrDrBlowerUpDn 0 "Reserved" 1 "Blower Up" 2 "Blower Down" 3 "Invalid" ;
VAL_ 157 ATS_DATC_FrSyncSet 0 "Reserved" 1 "NOT SYNC" 2 "SYNC" 3 "Invalid" ;
VAL_ 157 ATS_DATC_RrDrTempSetC 0 "Blank" 1 "LO" 2 "PHY=HEX*0.5 + 14" 3 "PHY=HEX*0.5 + 14" 4 "PHY=HEX*0.5 + 14" 5 "PHY=HEX*0.5 + 14" 6 "PHY=HEX*0.5 + 14" 7 "PHY=HEX*0.5 + 14" 8 "PHY=HEX*0.5 + 14" 9 "PHY=HEX*0.5 + 14" 10 "PHY=HEX*0.5 + 14" 11 "PHY=HEX*0.5 + 14" 12 "PHY=HEX*0.5 + 14" 13 "PHY=HEX*0.5 + 14" 14 "PHY=HEX*0.5 + 14" 15 "PHY=HEX*0.5 + 14" 16 "PHY=HEX*0.5 + 14" 17 "PHY=HEX*0.5 + 14" 18 "PHY=HEX*0.5 + 14" 19 "PHY=HEX*0.5 + 14" 20 "PHY=HEX*0.5 + 14" 21 "PHY=HEX*0.5 + 14" 22 "PHY=HEX*0.5 + 14" 23 "PHY=HEX*0.5 + 14" 24 "PHY=HEX*0.5 + 14" 25 "PHY=HEX*0.5 + 14" 26 "PHY=HEX*0.5 + 14" 27 "PHY=HEX*0.5 + 14" 28 "PHY=HEX*0.5 + 14" 29 "PHY=HEX*0.5 + 14" 30 "PHY=HEX*0.5 + 14" 31 "PHY=HEX*0.5 + 14" 32 "PHY=HEX*0.5 + 14" 33 "PHY=HEX*0.5 + 14" 34 "PHY=HEX*0.5 + 14" 35 "PHY=HEX*0.5 + 14" 36 "PHY=HEX*0.5 + 14" 37 "0x25~0xFC:Reserved" 252 "0x25~0xFC:Reserved" 254 "HI" 255 "Invalid" ;
VAL_ 157 ATS_DATC_RrDrTempSetF 0 "Blank" 1 "LO" 2 "PHY=HEX*1+56" 3 "PHY=HEX*1+56" 4 "PHY=HEX*1+56" 5 "PHY=HEX*1+56" 6 "PHY=HEX*1+56" 7 "PHY=HEX*1+56" 8 "PHY=HEX*1+56" 9 "PHY=HEX*1+56" 10 "PHY=HEX*1+56" 11 "PHY=HEX*1+56" 12 "PHY=HEX*1+56" 13 "PHY=HEX*1+56" 14 "PHY=HEX*1+56" 15 "PHY=HEX*1+56" 16 "PHY=HEX*1+56" 17 "PHY=HEX*1+56" 18 "PHY=HEX*1+56" 19 "PHY=HEX*1+56" 20 "PHY=HEX*1+56" 21 "PHY=HEX*1+56" 22 "PHY=HEX*1+56" 23 "PHY=HEX*1+56" 24 "PHY=HEX*1+56" 25 "PHY=HEX*1+56" 26 "PHY=HEX*1+56" 27 "PHY=HEX*1+56" 28 "PHY=HEX*1+56" 29 "PHY=HEX*1+56" 30 "PHY=HEX*1+56" 31 "PHY=HEX*1+56" 32 "PHY=HEX*1+56" 33 "PHY=HEX*1+56" 34 "PHY=HEX*1+56" 35 "PHY=HEX*1+56" 36 "PHY=HEX*1+56" 37 "0x25~0xFC:Reserved" 252 "0x25~0xFC:Reserved" 254 "HI" 255 "Invalid" ;
VAL_ 157 ATS_DATC_FrPsTempSetC 0 "Blank" 1 "LO" 2 "PHY=HEX*0.5 + 14" 3 "PHY=HEX*0.5 + 14" 4 "PHY=HEX*0.5 + 14" 5 "PHY=HEX*0.5 + 14" 6 "PHY=HEX*0.5 + 14" 7 "PHY=HEX*0.5 + 14" 8 "PHY=HEX*0.5 + 14" 9 "PHY=HEX*0.5 + 14" 10 "PHY=HEX*0.5 + 14" 11 "PHY=HEX*0.5 + 14" 12 "PHY=HEX*0.5 + 14" 13 "PHY=HEX*0.5 + 14" 14 "PHY=HEX*0.5 + 14" 15 "PHY=HEX*0.5 + 14" 16 "PHY=HEX*0.5 + 14" 17 "PHY=HEX*0.5 + 14" 18 "PHY=HEX*0.5 + 14" 19 "PHY=HEX*0.5 + 14" 20 "PHY=HEX*0.5 + 14" 21 "PHY=HEX*0.5 + 14" 22 "PHY=HEX*0.5 + 14" 23 "PHY=HEX*0.5 + 14" 24 "PHY=HEX*0.5 + 14" 25 "PHY=HEX*0.5 + 14" 26 "PHY=HEX*0.5 + 14" 27 "PHY=HEX*0.5 + 14" 28 "PHY=HEX*0.5 + 14" 29 "PHY=HEX*0.5 + 14" 30 "PHY=HEX*0.5 + 14" 31 "PHY=HEX*0.5 + 14" 32 "PHY=HEX*0.5 + 14" 33 "PHY=HEX*0.5 + 14" 34 "PHY=HEX*0.5 + 14" 35 "PHY=HEX*0.5 + 14" 36 "PHY=HEX*0.5 + 14" 37 "0x25~0xFD:Reserved" 253 "0x25~0xFD:Reserved" 254 "HI" 255 "Invalid" ;
VAL_ 157 ATS_DATC_FrPsTempSetF 0 "Blank" 1 "LO" 2 "PHY=HEX*1+56" 3 "PHY=HEX*1+56" 4 "PHY=HEX*1+56" 5 "PHY=HEX*1+56" 6 "PHY=HEX*1+56" 7 "PHY=HEX*1+56" 8 "PHY=HEX*1+56" 9 "PHY=HEX*1+56" 10 "PHY=HEX*1+56" 11 "PHY=HEX*1+56" 12 "PHY=HEX*1+56" 13 "PHY=HEX*1+56" 14 "PHY=HEX*1+56" 15 "PHY=HEX*1+56" 16 "PHY=HEX*1+56" 17 "PHY=HEX*1+56" 18 "PHY=HEX*1+56" 19 "PHY=HEX*1+56" 20 "PHY=HEX*1+56" 21 "PHY=HEX*1+56" 22 "PHY=HEX*1+56" 23 "PHY=HEX*1+56" 24 "PHY=HEX*1+56" 25 "PHY=HEX*1+56" 26 "PHY=HEX*1+56" 27 "PHY=HEX*1+56" 28 "PHY=HEX*1+56" 29 "PHY=HEX*1+56" 30 "PHY=HEX*1+56" 31 "PHY=HEX*1+56" 32 "PHY=HEX*1+56" 33 "PHY=HEX*1+56" 34 "PHY=HEX*1+56" 35 "PHY=HEX*1+56" 36 "PHY=HEX*1+56" 37 "0x25~0xFC:Reserved" 252 "0x25~0xFC:Reserved" 254 "HI" 255 "Invalid" ;
VAL_ 157 ATS_DATC_FrDrTempSetF 0 "Blank" 1 "LO" 2 "PHY=HEX*1 + 56" 3 "PHY=HEX*1 + 56" 4 "PHY=HEX*1 + 56" 5 "PHY=HEX*1 + 56" 6 "PHY=HEX*1 + 56" 7 "PHY=HEX*1 + 56" 8 "PHY=HEX*1 + 56" 9 "PHY=HEX*1 + 56" 10 "PHY=HEX*1 + 56" 11 "PHY=HEX*1 + 56" 12 "PHY=HEX*1 + 56" 13 "PHY=HEX*1 + 56" 14 "PHY=HEX*1 + 56" 15 "PHY=HEX*1 + 56" 16 "PHY=HEX*1 + 56" 17 "PHY=HEX*1 + 56" 18 "PHY=HEX*1 + 56" 19 "PHY=HEX*1 + 56" 20 "PHY=HEX*1 + 56" 21 "PHY=HEX*1 + 56" 22 "PHY=HEX*1 + 56" 23 "PHY=HEX*1 + 56" 24 "PHY=HEX*1 + 56" 25 "PHY=HEX*1 + 56" 26 "PHY=HEX*1 + 56" 27 "PHY=HEX*1 + 56" 28 "PHY=HEX*1 + 56" 29 "PHY=HEX*1 + 56" 30 "PHY=HEX*1 + 56" 31 "PHY=HEX*1 + 56" 32 "PHY=HEX*1 + 56" 33 "PHY=HEX*1 + 56" 34 "PHY=HEX*1 + 56" 35 "PHY=HEX*1 + 56" 36 "PHY=HEX*1 + 56" 37 "0x25~0xFD:Reserved" 253 "0x25~0xFD:Reserved" 254 "HI" 255 "Invalid" ;
VAL_ 171 BLTN_CAM_UI_Mode_Tmt_Req 0 "Default" 1 "BLTN_CAM UI Terminate Request" 2 "Reserved" 3 "invalid" ;
VAL_ 171 BLTN_CAM_Dis_Touch_BeepSound 0 "Off" 1 "ON" 2 "Keyboard On" 3 "invalid" ;
VAL_ 171 BLTN_CAM_PopUp_Req 0 "Default" 1 "Event Video Record On by manual switch" 2 "Time Lapse Record Started" 3 "Time Lapse Record Ended" 4 "micro SD card inserted" 5 "micro SD card removed" 6 "SD Card has problem(format required or need to be replaced)" 7 "Start Parking recording" 8 "Can not Start Parking recording (SD card is removed, not recognizable, or has problem)" 9 "Can not Record Event Video (SD card is removed, not recognizable, or has problem)" 10 "RESERVED" 11 "RESERVED" 12 "RESERVED" 13 "RESERVED" 14 "RESERVED" 15 "Invalid" ;
VAL_ 171 BLTN_CAM_File_List_Renew 0 "Defalut" 1 "the file list and storage space are renewed." 2 "reserved" 3 "Invalid" ;
VAL_ 171 BLTN_CAM_Wifi_Pwd_Chg_State 0 "Default" 1 "the password is changed" 2 "Failed, wrong password, can't change password" 3 "Invalid" ;
VAL_ 2323816449 C_CtrlDrLockRlyCCS_Copy_2 0 "Off (default)" 1 "On (remote Lock Command)" 2 "Reserved" 3 "Invalid" ;
VAL_ 2323816449 C_TeleHeatingCmdIBOX_Copy_2 0 "Off (default)" 1 "On(Remote Heating On)" 2 "Reserved" 3 "Invalid" ;
VAL_ 2323816449 C_TeleStrgWhlHeatingCmdIBOX_Copy_2 0 "Off (default)" 1 "On(Remote Heating On)" 2 "Reserved" 3 "Invalid" ;
VAL_ 2323816449 C_TeleDefoggerHeatingCmdIBOX_Copy_2 0 "Off (default)" 1 "On(Remote Heating On)" 2 "Reserved" 3 "Invalid" ;
VAL_ 2323816449 C_TeleDrvSeatOpCmdIBOX_Copy_2 0 "Init" 1 "Unused" 2 "Seat Heat&Vent OFF" 3 "Seat_Vent_Low" 4 "Seat_Vent_Mid" 5 "Seat_Vent_High" 6 "Seat_Heat_Low" 7 "Seat_Heat_Mid" 8 "Seat_Heat_High" 9 "Unused" 10 "Unused" 11 "Unused" 12 "Unused" 13 "Unused" 14 "Unused" 15 "Invalid" ;
VAL_ 2323816449 C_CtrlDrUnlockRlyCCS_Copy_2 0 "0ff" 1 "On (Remote Unlock Command)" 2 "Reserved" 3 "Invalid" ;
VAL_ 2323816449 C_TeleAstSeatOpCmdIBOX_Copy_2 0 "Init" 1 "Unused" 2 "Seat Heat&Vent OFF" 3 "Seat_Vent_Low" 4 "Seat_Vent_Mid" 5 "Seat_Vent_High" 6 "Seat_Heat_Low" 7 "Seat_Heat_Mid" 8 "Seat_Heat_High" 9 "Unused" 10 "Unused" 11 "Unused" 12 "Unused" 13 "Unused" 14 "Unused" 15 "Invalid" ;
VAL_ 2323816449 C_TeleRRSeatOpCmdIBOX_Copy_2 0 "Init" 1 "Unused" 2 "Seat Heat&Vent OFF" 3 "Seat_Vent_Low" 4 "Seat_Vent_Mid" 5 "Seat_Vent_High" 6 "Seat_Heat_Low" 7 "Seat_Heat_Mid" 8 "Seat_Heat_High" 9 "Unused" 10 "Unused" 11 "Unused" 12 "Unused" 13 "Unused" 14 "Unused" 15 "Invalid" ;
VAL_ 2323816449 C_TeleRLSeatOpCmdIBOX_Copy_1 0 "Init" 1 "Unused" 2 "Seat Heat&Vent OFF" 3 "Seat_Vent_Low" 4 "Seat_Vent_Mid" 5 "Seat_Vent_High" 6 "Seat_Heat_Low" 7 "Seat_Heat_Mid" 8 "Seat_Heat_High" 9 "Unused" 10 "Unused" 11 "Unused" 12 "Unused" 13 "Unused" 14 "Unused" 15 "Invalid" ;
VAL_ 2323816449 C_BlindCmdAVN_Copy_2 0 "No Action" 1 "R_Blind Auto Open" 2 "R_Blind Auto Close" 3 "Stop" 4 "reserved" 5 "reserved" 6 "reserved" 7 "Invalid" ;
VAL_ 2323816449 C_GlassCmdAVN_Copy_2 0 "No Action" 1 "Glass Auto Open" 2 "Glass Auto Close" 3 "Glass Auto Tilt Up" 4 "Stop" 5 "reserved" 6 "reserved" 7 "Invalid" ;
VAL_ 2323816449 C_DrvWindowCmdAVN_Copy_2 0 "No action" 1 "Manual Down" 2 "Manual Up" 3 "25% Open" 4 "50% Open" 5 "Auto Down" 6 "Auto Up" 7 "15% Open" 8 "Unused" 9 "Unused" 10 "Unused" 11 "Unused" 12 "Unused" 13 "Unused" 14 "Unused" 15 "Invalid" ;
VAL_ 2323816449 C_HazardFromCCS_Copy_2 0 "Off" 1 "On (Remote Hazard On)" 2 "Reserved" 3 "Invalid" ;
VAL_ 2323816449 C_AstWindowCmdAVN_Copy_2 0 "No action" 1 "Manual Down" 2 "Manual Up" 3 "25% Open" 4 "50%Open" 5 "Auto Down" 6 "Auto Up" 7 "15% Open" 8 "Unused" 9 "Unused" 10 "Unused" 11 "Unused" 12 "Unused" 13 "Unused" 14 "Unused" 15 "Invalid" ;
VAL_ 2323816449 C_RRWindowCmdAVN_Copy_2 0 "No action" 1 "Manual Down" 2 "Manual Up" 3 "25% Open" 4 "50% Open" 5 "Auto Down" 6 "Auto Up" 7 "15% Open" 8 "Unused" 9 "Unused" 10 "Unused" 11 "Unused" 12 "Unused" 13 "Unused" 14 "Unused" 15 "Invalid" ;
VAL_ 2323816449 C_RLWindowCmdAVN_Copy_2 0 "No action" 1 "Manual Down" 2 "Manual Up" 3 "25% Open" 4 "50% Open" 5 "Auto Down" 6 "Auto UP" 7 "15% Open" 8 "Unused" 9 "Unused" 10 "Unused" 11 "Unused" 12 "Unused" 13 "Unused" 14 "Unused" 15 "Invalid" ;
VAL_ 2323816449 TailCtrlReq_Copy 0 "No Action(Default)" 1 "Tail Off" 2 "Tail On" 3 "Error Indicator" ;
VAL_ 2323816449 HazardCtrlReq_Copy 0 "No Action(Default)" 1 "Hazard Off" 2 "Hazard On" 3 "Error Indicator" ;
VAL_ 2323816449 HU_DATC_AirCleaningSet_Copy_1 0 "Air Cleaning System Off" 1 "Air Cleaning System On" 2 "Air Cleaning System Not Support" 3 "Invalid" ;
VAL_ 2323816449 C_PanicFromCCS_Copy_2 0 "Off" 1 "On (Remote Horn and Hazard On)" 2 "Reserved" 3 "Invalid" ;
VAL_ 2323816449 C_TeleFrontHeatingCmdIBOX_Copy_1 0 "Off (Default)" 1 "On (Remote Heating On)" 2 "Reserved" 3 "Invalid" ;
VAL_ 2323816449 RAC_AirCleaningCtrlReq_Copy_1 0 "Deactive air cleaning control" 1 "Active air cleaning control" 2 "Not used" 3 "invalid" ;
VAL_ 2323816449 C_PreCrankReq_Copy 0 "Default" 1 "Req On" 2 "Not Support" 3 "Invalid" ;
VAL_ 2323816450 HU_CDMOpenCmd_Copy_1 0 "Default" 1 "CDM Open" 2 "CDM Close" 3 "Invalid" ;
VAL_ 2323816450 HU_StrgWhlHeatingSet_CCS_Copy 0 "Default (off)" 1 "Step1 On" 2 "Step2 On" 3 "Reserved" 4 "Reserved" 5 "Reserved" 6 "Reserved" 7 "Invalid" ;
VAL_ 2323816450 C_EsyAcsProfileID_CCU 0 "Default" 1 "Gueset" 2 "Profile 1" 3 "Profile 2" 4 "Reserved" 5 "Reserved" 6 "Reserved" 7 "Reserved" 8 "Reserved" 9 "Reserved" 10 "Reserved" 11 "Reserved" 12 "Reserved" 13 "Reserved" 14 "Reserved" 15 "Invalid" ;
VAL_ 679 USM_CMSDayBrgtnsLvlRHSta 0 "-5 Level" 1 "-4 Level" 2 "-3 Level" 3 "-2 Level" 4 "-1 Level" 5 "0 Level" 6 "1 Level" 7 "2 Level" 8 "3 Level" 9 "4 Level" 10 "5 Level" 11 "Not Used" 12 "Not Used" 13 "Not Used" 14 "Error Indicator" 15 "Invalid" ;
VAL_ 679 USM_CMSNgtBrgtnsLvlRHSta 0 "-5 Level" 1 "-4 Level" 2 "-3 Level" 3 "-2 Level" 4 "-1 Level" 5 "0 Level" 6 "1 Level" 7 "2 Level" 8 "3 Level" 9 "4 Level" 10 "5 Level" 11 "Not Used" 12 "Not Used" 13 "Not Used" 14 "Error Indicator" 15 "Invalid" ;
VAL_ 679 IMS_CMSPlayBackSta_RH 0 "Stop" 1 "Play 1" 2 "Play 2" 3 "Smart IMS" 4 "Profile 1" 5 "Profile 2" 6 "Guest" 7 "Invalid" ;
VAL_ 679 MonitorStatus 0 "Default" 1 "Off" 2 "On" 3 "Invalid" ;
VAL_ 679 CMS_RH_FoldingSta 0 "Off" 1 "Folding" 2 "Not Used" 3 "Error Indicator" ;
VAL_ 679 CMS_RH_UnfoldingSta 0 "Off" 1 "Unfolding" 2 "Not Used" 3 "Error Indicator" ;
VAL_ 679 CMS_RHVerPosVal 251 "Reserved" 252 "Reserved" 253 "Reserved" 254 "Reserved" 255 "Error Indicator" ;
VAL_ 679 CMS_RHHorPosVal 251 "Reserved" 252 "Reserved" 253 "Reserved" 254 "Reserved" 255 "Error Indicator" ;
VAL_ 2382594561 DATC_FrDrvModDis 0 "Off(Blank Display, ÅäÃâ¸ðµå ¹ÌÇ¥½Ã ¿¹) Auto ½Ã)" 1 "VENT" 2 "B_L" 3 "FLOOR" 4 "MIX (7 MODE DEF FLOOR)" 5 "DEF (MAX DEF)" 6 "AUTO DEFOG" 7 "7 MODE DEF VENT" 8 "MODE AUTO" 9 "7 MODE DEF VENT FLOOR" 10 "7 MODE DEF" 11 "DEF VENT (Arrow)" 12 "DEF FLOOR (Arrow)" 13 "DEF VENT FLOOR (Arrow)" 14 "DEF (Arrow)" 15 "Error Indicator" ;
VAL_ 2382594561 DATC_FrPassModDis 0 "Off(Blank Display, ÅäÃâ¸ðµå ¹ÌÇ¥½Ã ¿¹) Auto ½Ã)" 1 "VENT" 2 "B_L" 3 "FLOOR" 4 "MIX (7 MODE DEF FLOOR)" 5 "DEF (MAX DEF)" 6 "AUTO DEFOG" 7 "7 MODE DEF VENT" 8 "MODE AUTO" 9 "7 MODE DEF VENT FLOOR" 10 "7 MODE DEF" 11 "DEF VENT (Arrow)" 12 "DEF FLOOR (Arrow)" 13 "DEF VENT FLOOR (Arrow)" 14 "DEF (Arrow)" 15 "Error Indicator" ;
VAL_ 2382594561 DATC_ClmtTxtPopupOSD 0 "Default" 1 "AirCleaning SYS ON" 2 "AirCleaning SYS OFF" 3 "High Dust AirCleaning ON" 4 "High Dust AirCleaning OFF" 5 "Sensor AirCleaning SYS ON & Closing Window" 6 "Opening Warning" 7 "Auto AirCleaning SYS ON" 8 "Smart Ventilation On" 9 "Washer Intake On" 10 "Rear Climate OFF by ROA" 11 "0x0B~0xFE:Reserved" 254 "0x0B~0xFE:Reserved" 255 "Error Indicator" ;
VAL_ 2382594561 DATC_TempDispUnitSta 0 "Centigrade(¡É)" 1 "Fahrenheit(¢µ)" 2 "Not used" 3 "Error Indicator" ;
VAL_ 2382594561 DATC_DrvAutoDis 0 "AUTO Off" 1 "AUTO On" 2 "Not used" 3 "Error Indicator" ;
VAL_ 2382594561 DATC_FrChgReqDis 0 "OFF" 1 "User Input" 2 "Not used" 3 "Error Indicator" ;
VAL_ 2382594561 DATC_FrClmtScrnDis 0 "Deactived" 1 "Actived" 2 "Not used" 3 "Error Indicator" ;
VAL_ 2382594561 DATC_AcDis 0 "A/C Off" 1 "A/C ON" 2 "Not used" 3 "Error Indicator" ;
VAL_ 2382594561 DATC_IntakeSta 0 "Default" 1 "REC (Fresh off)" 2 "FRE (REC off)" 3 "Error Indicator" ;
VAL_ 2382594561 DATC_TempDrLvl 0 "Default" 1 "Max Cool" 2 "Cool2" 3 "Cool1" 4 "Warm1" 5 "Warm2" 6 "Max Hot" 7 "Not Used" 8 "Not Used" 9 "Not Used" 10 "Not Used" 11 "Not Used" 12 "Not Used" 13 "Not Used" 14 "Not Used" 15 "Error Indicator" ;
VAL_ 2424580353 DATC_StrWhlHtrSwReq 0 "Default" 1 "OFF" 2 "ON" 3 "Error Indicator" ;
VAL_ 2424580353 DATC_FRStHtrSwReq 0 "Default" 1 "OFF" 2 "ON" 3 "Error Indicator" ;
VAL_ 2424580353 DATC_FRStVentSwReq 0 "Default" 1 "OFF" 2 "ON" 3 "Error Indicator" ;
VAL_ 2424580353 DATC_RrDefSw 0 "Default" 1 "OFF" 2 "ON" 3 "Error Indicator" ;
VAL_ 2424580353 DATC_FLStOpReq 0 "Default" 1 "Integrated control OFF" 2 "OFF" 3 "Left Seat Ventilation 1st ON" 4 "Left Seat Ventilation 1st&2nd ON" 5 "Left Seat Ventilation 1st&2nd&3rd ON" 6 "Left Seat Warmer 1st ON" 7 "Left Seat Warmer 1st&2nd ON" 8 "Left Seat Warmer 1st&2nd&3rd ON" 9 "Not Used" 10 "Not Used" 11 "Not Used" 12 "Not Used" 13 "Not Used" 14 "Not Used" 15 "Error Indicator" ;
VAL_ 2424580353 DATC_FRStOpReq 0 "Default" 1 "Integrated control OFF" 2 "OFF" 3 "Right Seat Ventilation 1st ON" 4 "Right Seat Ventilation 1st&2nd ON" 5 "Right Seat Ventilation 1st&2nd&3rd ON" 6 "Right Seat Warmer 1st ON" 7 "Right Seat Warmer 1st&2nd ON" 8 "Right Seat Warmer 1st&2nd&3rd ON" 9 "Not Used" 10 "Not Used" 11 "Not Used" 12 "Not Used" 13 "Not Used" 14 "Not Used" 15 "Error Indicaotr" ;
VAL_ 2424580353 DATC_FLStHtrSwReq 0 "Default" 1 "OFF" 2 "ON" 3 "Error Indicator" ;
VAL_ 2424580353 DATC_FLStVentSwReq 0 "Default" 1 "OFF" 2 "ON" 3 "Error Indicator" ;
VAL_ 2424580353 DATC_FLStTmblrSwReq 0 "Default" 1 "Up" 2 "Down" 3 "Error Indicator" ;
VAL_ 2424580353 DATC_FRStTmblrSwReq 0 "Default" 1 "Up" 2 "Down" 3 "Error Indicator" ;
VAL_ 2424580353 DATC_RRStHtrSwReq 0 "Default" 1 "OFF" 2 "ON" 3 "Error Indicator" ;
VAL_ 2424580353 DATC_RRStVentSwReq 0 "Default" 1 "OFF" 2 "ON" 3 "Error Indicator" ;
VAL_ 2424580353 DATC_RLStHtrSwReq 0 "Default" 1 "OFF" 2 "ON" 3 "Error Indicator" ;
VAL_ 2424580353 DATC_RLStVentSwReq 0 "Default" 1 "OFF" 2 "ON" 3 "Error Indicator" ;
VAL_ 2424580353 DATC_FRWndShldHtSW 0 "Default" 1 "Off" 2 "On" 3 "Error Indicator" ;
VAL_ 2424580353 DATC_WhistlelNoise 0 "Default" 1 "Off" 2 "On (Whistle Noise Prevent)" 3 "Error Indicator" ;
VAL_ 2424580353 DATC_WdwClsReq 0 "Default" 1 "Close Request" 2 "Reserved" 3 "Error Indicator" ;
VAL_ 2424580353 DATC_RRSyncDis 0 "Rear SYNC Off" 1 "Rear SYNC On" 2 "Not used" 3 "Error Indicator" ;
VAL_ 2176872449 HDCT_OBDErrSta 0 "No error" 1 "OBD error" 2 "Not used" 3 "Error Indicator" ;
VAL_ 2176872449 HDCT_StcShftLrchCtrl 0 "No DR or RD lurch control" 1 "DR lurch control active" 2 "RD lurch control active" 3 "Error Indicator" ;
VAL_ 2176872449 HDCT_EngCltchLmphmMod 0 "Inactive" 1 "Active" 2 "Not used" 3 "Error Indicator" ;
VAL_ 2176872449 HDCT_CurrPrgrm 0 "SOS" 1 "ECO" 16 "ACC_NLD" 17 "ACC_LD1" 18 "ACC_LD2" 19 "ACC_LD3" 20 "Manual" 21 "Manual_LD" 22 "CLT_PRT" 23 "TCS_NLD" 24 "TCS_LD" 25 "NORMAL" 26 "ECO_DLD" 27 "DS_DLD" 28 "EVEN" 29 "ODD" 30 "CD (EV Mode)" 31 "Reserve" 2 "DS" 3 "ECO_LD1" 4 "ECO_LD2" 5 "ECO_LD3" 6 "ECO_LD1_HAT" 7 "ECO_LD2_HAT" 8 "ECO_LD3_HAT" 9 "DS_LD1" 10 "DS_LD2" 11 "DS_LD3" 12 "SOC_L" 13 "SOC_N" 14 "SOC_H" 15 "Highway" ;
VAL_ 2176872449 HDCT_FltSta 0 "No fault" 1 "TCU Diagnostic failure" 2 "" 3 "TCU Diagnostic faulure & Limphome activated" 4 "OPU/EOP Diagnostic failure" 5 "" 6 "" 7 "" ;
VAL_ 2176872449 HDCT_MCUAntJrkInhbt 0 "Anti-jerk not inhibit" 1 "Anti-jerk inhibit" 2 "Not used" 3 "Error Indicator" ;
VAL_ 2176872449 HDCT_TrgtGear 0 "If N or P are detected(No frictional conncetion)" 1 "1st speed" 2 "2nd speed" 3 "3rd speed" 4 "4th speed" 5 "5th speed" 6 "6th speed" 15 "Reverse" ;
VAL_ 2176872449 HDCT_CurrGear 0 "if N or P are detected (no frictional connection)" 1 "1st speed" 2 "2nd speed" 3 "3rd speed" 4 "4th speed" 5 "5th speed" 6 "6th speed" 15 "Reverse speed" ;
VAL_ 2176872449 HDCT_GearSelDis 0 "P" 1 "L" 2 "2" 3 "3" 4 "DS Mode (by TGS lever)" 5 "D" 6 "N" 7 "R" 8 "Sports/Manual Mode" 9 "Not display at Cluster" 10 "DS Mode (by Drive Mode button)" 11 "Reserved" 12 "Paddle shift" 13 "Reserved" 14 "Intermediate Position" 15 "Fault" ;
VAL_ 2176872450 HDCT_TCURdySta 0 "Not ready" 1 "Ready" 2 "Not used" 3 "Error Indicator" ;
VAL_ 2176872450 HDCT_NetrlCtrlSta 0 "Not complete" 1 "Complete" 2 "Not used" 3 "Error Indicator" ;
VAL_ 2176872450 HDCT_GearShftSta 0 "Inactive" 1 "Active" 2 "Not used" 3 "Error Indicator" ;
VAL_ 2176872450 HDCT_CtrlablSta 0 "Not Ready" 1 "Controllable" 2 "Not used" 3 "Error Indicator" ;
VAL_ 2176872450 HDCT_TqIncReq 0 "Passive" 1 "Torque increase controls" 2 "Not used" 3 "Error Indicator" ;
VAL_ 2176872450 HDCT_TrgtShftCls 0 "static" 1 "Pon UP" 2 "Poff UP" 3 "reserve" 4 "Pon DN" 5 "PoffDn(manual)" 6 "NSTP to 5;4;3;2" 7 "NSTP to 1" 8 "reserve" 9 "reserve" 10 "reserve" 11 "reserve" 12 "reserve" 13 "reserve" 14 "reserve" ;
VAL_ 2176872450 HDCT_EOLReq 0 "No request" 1 "EOL request" 2 "Not used" 3 "Error Indicator" ;
VAL_ 2176872450 HDCT_CltchSta 0 "Open" 1 "Slip" 2 "Locked" 3 "Locked&Micro Slip" ;
VAL_ 2176872450 HDCT_DblCltchSta 0 "CS_Open" 1 "CS_TakeUp" 2 "CS_Engage" 3 "CS_Shift" 4 "CS_Drive" 5 "CS_Disengage" 6 "CS_SpinRequest" 7 "CS_TestMode" 8 "CS_Initialize" 9 "CS_Fail" ;
VAL_ 2176872450 HDCT_AcnChrgInhbtReq 0 "-" 1 "Freeze AC clutch" 2 "Not used" 3 "Error Indicator" ;
VAL_ 2176872450 HDCT_KckDnSkpShftCnt 0 "Normal K/D(No Skipº¯¼Ó) or No shift" 1 "1st Skip K/D" 2 "2nd Skip K/D" 3 "Error Indicator" ;
VAL_ 2176872450 HDCT_ShftPhase 0 "No shift" 1 "A0 (Prepataion for shift)" 2 "A1 (Prepataion for shift)" 3 "A2 (Prepataion for shift)" 4 "A3 (Prepataion for shift)" 5 "B1 (Beginning of shift)" 6 "B2 (Beginning of shift)" 7 "B3 (Beginning of shift)" 8 "B4 (Beginning of shift)" 9 "C1 (Duration of actual shift)" 10 "C2 (Duration of actual shift)" 11 "C3 (Duration of actual shift)" 12 "D1 (Duration of actual shift)" 13 "E1 (Finishing shift)" 14 "E2 (Finishing shift)" 15 "E3 (Finishing shift)" 16 "END (Shift End)" ;
VAL_ 2176872451 HDCT_FuelCutReq 0 "No Fuel Cut request" 1 "Activation of Fuel Cut request" 2 "Not used" 3 "Error Indicator" ;
VAL_ 2176872451 HDCT_NCoastTrgtGear 0 "gN" 1 "g1" 2 "g2" 3 "g3" 4 "g4" 5 "g5" 6 "g6" 7 "None" 8 "None" 9 "None" 10 "None" 11 "None" 12 "None" 13 "None" 14 "None" 15 "gR" ;
VAL_ 2176872451 HDCT_CLUEngSpdFlag 0 "Off" 1 "On" 2 "Not used" 3 "Error Indicator" ;
VAL_ 2176872451 HDCT_CLUTrgtGear 0 "If N or P are detected(No frictional conncetion)" 1 "1st speed" 2 "2nd speed" 3 "3rd speed" 4 "4th speed" 5 "5th speed" 6 "6th speed" 7 "7th speed" 15 "Reverse" ;
VAL_ 2176872451 HDCT_GSITrgtGear 0 "Neutral (Initial Value)" 1 "1st speed" 2 "2nd speed" 3 "3rd speed" 4 "4th speed" 5 "5th speed" 6 "6th speed" 7 "Reserved" 8 "Reserved" 9 "Reserved" 10 "Reserved" 11 "Reserved" 12 "Reserved" 13 "Reserved" 14 "Reserved" 15 "Reserved" ;
VAL_ 2176872451 HDCT_NCoastDnReq 0 "Off" 1 "On" 2 "Not used" 3 "Error Indicator" ;
VAL_ 2176872451 HDCT_CLUEngSpd 8191 "Error Indicator" ;
VAL_ 676 C_DrAirSptNValueSet_EC 0 "Default" 1 "Off" 2 "On" 3 "Invalid" ;
VAL_ 676 C_DrCushSoftNValueSet_EC 0 "Default" 1 "Off" 2 "Low" 3 "Mid" 4 "High" 5 "Reserved" 6 "Reserved" 7 "Invalid" ;
VAL_ 676 C_AstAirSptNValueSet_EC 0 "Default" 1 "Off" 2 "On" 3 "Invalid" ;
VAL_ 676 C_DrBackSoftNValueSet_EC 0 "Default" 1 "Off" 2 "Low" 3 "Mid" 4 "High" 5 "Reserved" 6 "Reserved" 7 "Invalid" ;
VAL_ 676 C_AstAirSptModeNValueSet_EC 0 "Default" 1 "Mode 1" 2 "Mode 2" 3 "Mode 3" 4 "Mode 4" 5 "Mode 5" 6 "Reserved" 7 "Invalid" ;
VAL_ 676 C_DrAirSptModeNValueSet_EC 0 "Default" 1 "Mode 1" 2 "Mode 2" 3 "Mode 3" 4 "Mode 4" 5 "Mode 5" 6 "Reserved" 7 "Invalid" ;
VAL_ 676 C_RLAirSptNValueSet_EC 0 "Default" 1 "Off" 2 "On" 3 "Invalid" ;
VAL_ 676 C_AstAirSptStrNValueSet_EC 0 "Default" 1 "Weak" 2 "Normal" 3 "Strong" 4 "Reserved" 5 "Reserved" 6 "Reserved" 7 "Invalid" ;
VAL_ 676 C_AstAirSptTimeNValueSet_EC 0 "Default" 1 "Short" 2 "Normal" 3 "Long" 4 "Reserved" 5 "Reserved" 6 "Reserved" 7 "Invalid" ;
VAL_ 676 C_RRAirSptNValueSet_EC 0 "Default" 1 "Off" 2 "On" 3 "Invalid" ;
VAL_ 676 C_AstCushSoftNValueSet_EC 0 "Default" 1 "Off" 2 "Low" 3 "Mid" 4 "High" 5 "Reserved" 6 "Reserved" 7 "Invalid" ;
VAL_ 676 C_AstBackSoftNValueSet_EC 0 "Default" 1 "Off" 2 "Low" 3 "Mid" 4 "High" 5 "Reserved" 6 "Reserved" 7 "Invalid" ;
VAL_ 676 C_AstRlxNValueSet_EC 0 "Default" 1 "Off" 2 "Return" 3 "Relax" 4 "Reserved" 5 "Reserved" 6 "Reserved" 7 "Invalid" ;
VAL_ 676 C_RLAirSptModeNValueSet_EC 0 "Default" 1 "Mode 1" 2 "Mode 2" 3 "Mode 3" 4 "Mode 4" 5 "Mode 5" 6 "Reserved" 7 "Invalid" ;
VAL_ 676 C_DrAirSptStrNValueSet_EC 0 "Default" 1 "Weak" 2 "Normal" 3 "Strong" 4 "Reserved" 5 "Reserved" 6 "Reserved" 7 "Invalid" ;
VAL_ 676 C_RLAirSptStrNValueSet_EC 0 "Default" 1 "Weak" 2 "Normal" 3 "Strong" 4 "Reserved" 5 "Reserved" 6 "Reserved" 7 "Invalid" ;
VAL_ 676 C_RLAirSptTimeNValueSet_EC 0 "Default" 1 "Short" 2 "Normal" 3 "Long" 4 "Reserved" 5 "Reserved" 6 "Reserved" 7 "Invalid" ;
VAL_ 676 C_DrAirSptTimeNValueSet_EC 0 "Default" 1 "Short" 2 "Normal" 3 "Long" 4 "Reserved" 5 "Reserved" 6 "Reserved" 7 "Invalid" ;
VAL_ 677 C_RLBackSoftNValueSet_EC 0 "Default" 1 "Off" 2 "Low" 3 "Mid" 4 "High" 5 "Reserved" 6 "Reserved" 7 "Invalid" ;
VAL_ 677 C_RRAirSptStrNValueSet_EC 0 "Default" 1 "Weak" 2 "Normal" 3 "Strong" 4 "Reserved" 5 "Reserved" 6 "Reserved" 7 "Invalid" ;
VAL_ 677 C_RRAirSptTimeNValueSet_EC 0 "Default" 1 "Short" 2 "Normal" 3 "Long" 4 "Reserved" 5 "Reserved" 6 "Reserved" 7 "Invalid" ;
VAL_ 677 C_RRBackSoftNValueSet_EC 0 "Default" 1 "Off" 2 "Low" 3 "Mid" 4 "High" 5 "Reserved" 6 "Reserved" 7 "Invalid" ;
VAL_ 677 C_RROneTchNvalueSet_EC 0 "Default" 1 "Off" 2 "Return" 3 "Relax" 4 "AV" 5 "Read" 6 "Reserved" 7 "Invalid" ;
VAL_ 677 C_RLOneTchNValueSet_EC 0 "Default" 1 "Off" 2 "Return" 3 "Relax" 4 "Reserved" 5 "Reserved" 6 "Reserved" 7 "Invalid" ;
VAL_ 677 C_RRAirSptModeNValueSet_EC 0 "Default" 1 "Mode 1" 2 "Mode 2" 3 "Mode 3" 4 "Mode 4" 5 "Mode 5" 6 "Reserved" 7 "Invalid" ;
VAL_ 1239 HU_MKBD_BtnLEDCtr 0 "Default" 1 "OFF" 2 "ON" 3 "Invalid" ;
VAL_ 1239 HU_ADMSettingState 0 "ADM On (Setting Vaule in HU)" 1 "ADM Off" 2 "Reserved" 3 "Reserved" 4 "Reserved" 5 "Reserved" 6 "Reserved" 7 "Invalid" ;
VAL_ 1239 HU_DigitalKeyInformAvailable 0 "Service OFF" 1 "Service ON" 2 "Service ON &OfflineMode" 3 "invalid" ;
VAL_ 1239 HU_VehiclePwr 0 "Key out or Audio OFF" 1 "Not used" 2 "ACC or Audio ON" 3 "KBD Wake-up" 4 "Waiting for Good-Bye (Key out or Audio OFF)" 5 "Not used" 6 "Not used" 7 "Not used" 8 "Not used" 9 "Not used" 10 "Not used" 11 "Not used" 12 "Not used" 13 "Not used" 14 "Not used" 15 "Invalid" ;
VAL_ 1239 HU_BtnShowReq 0 "default" 1 "on" 2 "off" 3 "reserved" 4 "reserved" 5 "reserved" 6 "reserved" 7 "invalid" ;
VAL_ 1240 HU_DistanceUnit 0 "Km" 1 "Mile" 2 "Reserved" 3 "Invalid" ;
VAL_ 1240 HU_ThemeType 0 "default" 1 "Aqua(Hyundai)" 16 "Copper" 17 "Copper Rust" 2 "Magenta(Kia)" 32 "ccIC Light" 33 "ccIC Dark" 3 "Eco White" 4 "Eco Black" 5 "Genesis(IKPE)" 6 "Magenta White" ;
VAL_ 1240 HU_MicActivity 0 "Deactivated" 1 "Activated" 2 "reserved" 3 "Invalid" ;
VAL_ 1240 HU_Scheduled_Setting 0 "Scheduled not set" 1 "Scheduled set" 2 "Reserved" 3 "Reserved" 4 "Reserved" 5 "Reserved" 6 "60% SoC Requested" 7 "70% SoC Requested" 8 "80% SoC Requested" 9 "90% SoC Requested" 10 "100% SoC Requested" 11 "Reserved" 12 "Reserved" 13 "Reserved" 14 "Reserved" 15 "Invalid" ;
VAL_ 1240 AVN_RSPA_ModeSelect 0 "None" 1 "CCP focus (1st menu on the left)" 2 "Touch or CCP confirm (1st menu on the left)" 3 "CCP focus (2nd menu on the left)" 4 "Touch or CCP confirm (2nd menu on the left)" 5 "CCP focus (1st menu on the right)" 6 "Touch or CCP confirm (1st menu on the right)" 7 "CCP focus (2nd menu on the right)" 8 "Touch or CCP confirm (2nd menu on the right)" 9 "Reserved" 10 "Reserved" 11 "Reserved" 12 "Reserved" 13 "Reserved" 14 "Reserved" 15 "Invalid" ;
VAL_ 1240 CF_HU_GPSFlt 0 "Normal" 1 "Fault operation" 2 "TimeOut" 3 "Invalid" ;
VAL_ 1240 AVN_RSPA_CancelInput 0 "Init" 1 "No Input" 2 "Cancel Input" 3 "Invalid" ;
VAL_ 1240 AVN_RSPA_Disp_Rdy 0 "Impossible to display" 1 "Possible to display" 2 "Reserved" 3 "Invalid" ;
VAL_ 1240 CF_AVN_ProfileIDRValue 0 "Default" 1 "Guest" 2 "Profile 1" 3 "Profile 2" 4 "reserved" 5 "reserved" 6 "reserved" 7 "reserved" 8 "reserved" 9 "reserved" 10 "reserved" 11 "reserved" 12 "reserved" 13 "reserved" 14 "reserved" 15 "Invalid" ;
VAL_ 1240 HazardFromHUSVM 0 "inactive" 1 "active" 2 "reserved" 3 "invalid" ;
VAL_ 1240 OMUOSMirCtrl 0 "Off" 1 "Fold" 2 "Unfold" 3 "invalid" ;
VAL_ 1240 OTAUIStatus 0 "Not Ready" 1 "Ready" 2 "Reserved" 3 "Invalid" ;
VAL_ 1240 C_TeleActiveStatus 0 "Active" 1 "Deactive" 2 "Reserved" 3 "Invalid" ;
VAL_ 1240 HU_AliveStatus 0 "Not Ready" 1 "On Mode" 2 "Head Unit Update Mode" 3 "Invalid" ;
VAL_ 1240 HU_RTCCheck 0 "Ready" 1 "Checking" 2 "Reserved" 3 "Invalid" ;
VAL_ 1218 C_AVN_PTGHeightNValueSet 0 "Default" 1 "Level 1" 2 "Level 2" 3 "Level 3" 4 "Level 4" 5 "Reserved" 6 "User Setting" 7 "Invalid" ;
VAL_ 1218 CF_AVN_SCCMLReset 0 "Default" 1 "Reset" 2 "Reserved" 3 "Invalid" ;
VAL_ 1218 C_TgltAwayCloseNValue 0 "Default" 1 "Off" 2 "On" 3 "Invalid" ;
VAL_ 1218 C_HAnBNValueSet 0 "Default" 1 "Arm Disarm Buzzer Off" 2 "Arm Disarm Buzzer On" 3 "Invalid" ;
VAL_ 1218 CF_AVN_RrSeatRemindNValueSet 0 "Default" 1 "Off  (Disable)" 2 "On (Enable)" 3 "Invalid" ;
VAL_ 1218 CF_AVN_DSWNValueSet 0 "Default" 1 "Off" 2 "On" 3 "Invalid" ;
VAL_ 1218 CF_AVN_RRPSU_RLNValueSet 0 "Default" 1 "Off (Disable)" 2 "On (Enable)" 3 "Reserved" 4 "Reserved" 5 "Reserved" 6 "Reserved" 7 "Invalid" ;
VAL_ 1218 CF_AVN_APSUNValueSet 0 "Default" 1 "Off (Disable)" 2 "50mm On (Enable)" 3 "75mm On (Enable)" 4 "Reserved" 5 "Reserved" 6 "Reserved" 7 "Invalid" ;
VAL_ 1218 CF_AVN_NCC_CameraNValueSet 0 "Default" 1 "Function Off" 2 "Manual Resume (Function On)" 3 "Automatic Resume (Function On)" 4 "Reserved" 5 "Reserved" 6 "Reserved" 7 "Invalid" ;
VAL_ 1218 CF_AVN_FCAJnctnNValueSet 0 "Default" 1 "Off" 2 "On" 3 "Invalid" ;
VAL_ 1218 CF_AVN_RRPSU_RRNValueSet 0 "Default" 1 "Off (Disable)" 2 "On (Enable)" 3 "Reserved" 4 "Reserved" 5 "Reserved" 6 "Reserved" 7 "Invalid" ;
VAL_ 1218 CF_AVN_HtBlcAstNValueSet 0 "Default" 1 "Normal" 2 "Back 1" 3 "Back 2" 4 "Back 3" 5 "Cush 1" 6 "Cush 2" 7 "Cush 3" 8 "Reserved" 9 "Reserved" 10 "Reserved" 11 "Reserved" 12 "Reserved" 13 "Reserved" 14 "Reserved" 15 "Invalid" ;
VAL_ 1218 CF_AVN_HtBlcDrvNValueSet 0 "Default" 1 "Normal" 2 "Back 1" 3 "Back 2" 4 "Back 3" 5 "Cush 1" 6 "Cush 2" 7 "Cush 3" 8 "Reserved" 9 "Reserved" 10 "Reserved" 11 "Reserved" 12 "Reserved" 13 "Reserved" 14 "Reserved" 15 "Invalid" ;
VAL_ 1218 CF_AVN_SCCModeNValueSet 0 "Not applied" 1 "Drive mode" 2 "SCC-ML" 3 "Invalid" ;
VAL_ 1218 CF_AVN_SCCMLChar1Set 0 "None" 1 "Level 1(Weak)" 2 "Level 2" 3 "Level 3" 4 "Level 4" 5 "Level 5(Strong)" 6 "Reserved" 7 "Invalid" ;
VAL_ 1218 CF_AVN_UIPNValueSet 0 "Default" 1 "Off (Disable)" 2 "On (Enable)" 3 "Invalid" ;
VAL_ 1218 CF_AVN_SCCMLChar2Set 0 "None" 1 "Level 1(Short)" 2 "Level 2" 3 "Level 3" 4 "Level 4" 5 "Reserved" 6 "Reserved" 7 "Invalid" ;
VAL_ 1218 CF_AVN_SCCMLChar3Set 0 "None" 1 "Level 1(Slow)" 2 "Level 2" 3 "Level 3" 4 "Level 4" 5 "Level 5(Fast)" 6 "Reserved" 7 "Invalid" ;
VAL_ 1218 CF_AVN_NmodeFCAoffNValue 0 "Default" 1 "Disable" 2 "Enable" 3 "Invalid" ;
VAL_ 1218 CF_AVN_HDALCFuncNValueSet 0 "Default" 1 "Off" 2 "On" 3 "Invalid" ;
VAL_ 675 Usm_RpmMUDSet 0 "Default" 1 "Off" 2 "On(RPM Gauge Display)" 3 "Invalid" ;
VAL_ 675 CF_AVN_HtBlcRLNValueSet 0 "Default" 1 "Normal" 2 "Back 1" 3 "Back 2" 4 "Back 3" 5 "Cush 1" 6 "Cush 2" 7 "Cush 3" 8 "Reserved" 9 "Reserved" 10 "Reserved" 11 "Reserved" 12 "Reserved" 13 "Reserved" 14 "Reserved" 15 "Invalid" ;
VAL_ 675 CF_AVN_BRAKE_PedalfeelNValueSet2 0 "Default" 1 "Normal" 2 "Sport" 3 "Chauffeur" 4 "Reserved" 5 "Reserved" 6 "Reserved" 7 "Invalid" ;
VAL_ 675 CF_AVN_HtBlcRRNValueSet 0 "Default" 1 "Normal" 2 "Back 1" 3 "Back 2" 4 "Back 3" 5 "Cush 1" 6 "Cush 2" 7 "Cush 3" 8 "Reserved" 9 "Reserved" 10 "Reserved" 11 "Reserved" 12 "Reserved" 13 "Reserved" 14 "Reserved" 15 "Invalid" ;
VAL_ 675 LapTimer_AutoMeasure_Setting 0 "default" 1 "off" 2 "on (auto-measure)" 3 "invalid" ;
VAL_ 675 LapTimer_TimeGap_Setting 0 "default" 1 "compare with best lap" 2 "compare with last lap" 3 "invalid" ;
VAL_ 675 Usm_RpmSANDSet 0 "Default" 1 "Off" 2 "On(RPM Gauge Display)" 3 "Invalid" ;
VAL_ 675 CF_AVN_RemoteWDWNValueSet 0 "Default" 1 "Disable (Off)" 2 "Enable (On)" 3 "Invalid" ;
VAL_ 675 USM_TowWeight_Set 0 "Default" 1 "Off" 2 "Auto" 3 "Small" 4 "Medium" 5 "Maximum" 6 "Reserved" 7 "Reserved" 8 "Reserved" 9 "Reserved" 10 "Reserved" 11 "Reserved" 12 "Reserved" 13 "Reserved" 14 "Reserved" 15 "Invalid" ;
VAL_ 675 CF_AVN_PABArbgNValueSet 0 "Default" 1 "PAB Off" 2 "PAB On" 3 "Invalid" ;
VAL_ 675 CF_AVN_SportHUD2 0 "Default" 1 "Off(Normal)" 2 "Sport HUD" 3 "Invalid" ;
VAL_ 675 C_SLB_SmartCtrl_Set_Nvalue 0 "Init" 1 "Off" 2 "10min" 3 "20min" 4 "30min" 5 "40min" 6 "50min" 7 "60min" 8 "Unused" 9 "Unused" 10 "Unused" 11 "Unused" 12 "Unused" 13 "Unused" 14 "Unused" 15 "Invalid" ;
VAL_ 675 CF_AVN_ArHudLeftRightSet 0 "Default" 1 "Center" 2 "Left1" 3 "Left2" 4 "Left3" 5 "Left4" 6 "Left5" 7 "Right1" 8 "Right2" 9 "Right3" 10 "Right4" 11 "Right5" 12 "Reserved" 13 "Reserved" 14 "Reserved" 15 "Invalid" ;
VAL_ 675 HU_CustomNewMenuSet 0 "Default" 1 "MY Drive Mode (Custom)" 2 "Smart (Custom)" 3 "Baby (Custom)" 4 "Retro(Custom)" 5 "Snow(CUSTOM) - Not Terrain" 6 "Comfort(Rear) - Custom" 7 "Reserved" 8 "Reserved" 9 "Reserved" 10 "Reserved" 11 "Reserved" 12 "Reserved" 13 "Reserved" 14 "Off(Custom)" 15 "Invalid" ;
VAL_ 675 CF_AVN_ArHudViewSet 0 "Default" 1 "Center" 2 "View1" 3 "View2" 4 "View3" 5 "View4" 6 "View5" 7 "View6" 8 "View7" 9 "View8" 10 "View9" 11 "View10" 12 "Reserved" 13 "Reserved" 14 "Reserved" 15 "Reserved" 16 "Reserved" 17 "View-1" 18 "View-2" 19 "View-3" 20 "View-4" 21 "View-5" 22 "View-6" 23 "View-7" 24 "View-8" 25 "View-9" 26 "View-10" 27 "Reserved" 28 "Reserved" 29 "Reserved" 30 "Reserved" 31 "Invalid" ;
VAL_ 675 USM_RpmComfortRearSet 0 "Default (Not configured)" 1 "Off" 2 "On (Display RPM guage)" 3 "Invalid" ;
VAL_ 675 Usm_RpmMyDriveModeSet 0 "Default" 1 "Off" 2 "On(RPM Gauge Display)" 3 "Invalid" ;
VAL_ 675 CF_AVN_PCA_RrEquipNvalueSet 0 "Default" 1 "Off" 2 "On" 3 "Invalid(Gray)" ;
VAL_ 1251 IAU_EsyAcsProfileID 0 "Default" 1 "Profile 1" 2 "Profile 2" 3 "Guest" ;
VAL_ 1251 IAU_SmrtPhnID 0 "None" 1 "ID1" 2 "ID2" 3 "ID3" 4 "ID4" 5 "ID5" 6 "ID6" 7 "ID7" 8 "ID8" 9 "Reseved" 10 "Reseved" 11 "Reseved" 12 "Reseved" 13 "Reseved" 14 "Reseved" 15 "Reseved" ;
VAL_ 1251 IAU_SmrtPhnCmd 0 "None" 1 "Reserved" 2 "Reserved" 3 "Reserved" 4 "Reserved" 5 "Reserved" 6 "Reserved" 7 "Tele Cranking Stop" 8 "Reserved" 9 "Forward (RSPA)" 10 "Backward/Parking (RSPA)" 11 "Pause (RSPA)" 12 "PL Lft Out" 13 "PL Rt Out" 14 "Reserved" 15 "Reserved" ;
VAL_ 1251 IAUwFRU_ISK_LearningReq 0 "Default (Normal)" 1 "Start with PSK #1" 2 "Start with PSK #2" 3 "Start with PSK #3" 4 "Start with PSK #4" 5 "Start with PSK #5" 6 "Stop" 7 "Neutral" 8 "Reserved" 9 "Reserved" 10 "Reserved" 11 "Reserved" 12 "Reserved" 13 "Reserved" 14 "Reserved" 15 "Invalid" ;
VAL_ 1251 IAUwFPM_ISK_LearningReq 0 "Default" 1 "Start with PSK #1" 2 "Start with PSK #2" 3 "Start with PSK #3" 4 "Start with PSK #4" 5 "Start with PSK #5" 6 "Stop" 7 "Neutral" 8 "Reserved" 9 "Reserved" 10 "Reserved" 11 "Reserved" 12 "Reserved" 13 "Reserved" 14 "Reserved" 15 "Invalid" ;
VAL_ 1251 IAU2FRU_ISKLearnFdbck 0 "Default" 1 "Positive" 2 "Negative" 3 "Invalid" ;
VAL_ 1251 IAU2FPM_ISKLearnFdbck 0 "Default" 1 "Positive" 2 "Negative" 3 "Invalid" ;
VAL_ 2172675329 IEB_SrvLmpDis 0 "AHB Service Lamp is Off" 1 "AHB Service Lamp is On" 2 "AHB Service Lamp is BLINKING(2HZ)" 3 "Error Indicator" ;
VAL_ 2172675329 IEB_DfctvSta 0 "AHB is normal mode" 1 "AHB is degraded mode" 2 "AHB is defective mode" 3 "Error Indicator" ;
VAL_ 2172675329 IEB_ActvSta 0 "All Control Inactive" 1 "Charging Active" 2 "AHB Control Active" 3 "Chaging Active + AHB Control Active" ;
VAL_ 2172675329 IEB_DiagSta 0 "AHB is not diagnostic mode" 1 "AHB is diagnostic mode" 2 "Not used" 3 "Error Indicator" ;
VAL_ 2172675329 IEB_WrngLmpDis 0 "AHB Warning Lamp is Off" 1 "AHB Warning Lamp is On" 2 "Not used" 3 "Error Indicator" ;
VAL_ 2172675329 IEB_MILReq 0 "No Request" 1 "MIL On Request" 2 "Reserved" 3 "Reserved" ;
VAL_ 2172675329 IEB_BrkActvSta 0 "ECU does not support this function." 1 "Brake switch is not pressed (OFF)" 2 "Brake switch is pressed (ON)" 3 "Brake switch failure" ;
VAL_ 2172675329 IEB_PdlTrvlSnsrFailSta 0 "Normal" 1 "Fail" 2 "Not used" 3 "Error Indicator" ;
VAL_ 2172675329 IEB_PdlCalibSta 0 "Not complete" 1 "Complete" 2 "Not used" 3 "Error Indicator" ;
VAL_ 2172675329 IEB_BzrSta 0 "Buzzer is Off" 1 "Buzzer is On" 2 "Not used" 3 "Error Indicator" ;
VAL_ 2172675332 TCS_MtrTrgtRpm_Flag_Frnt 0 "Positive" 1 "Negative" ;
VAL_ 2172675332 TCS_MtrTrgtRpm_Flag_Rear 0 "Positive" 1 "Negative" ;
VAL_ 2172675332 TCS_MtrTrgtRpm_Rear 0 "0x0x000~0xFFE:Motor RPM Target" 4094 "0x0x000~0xFFE:Motor RPM Target" 4095 "Error Value" ;
VAL_ 2172675332 IEB_DriftModeSta 0 "Default" 1 "Drift Mode Activate (ON)" 2 "Drift Mode Deactivate (OFF)" 3 "Defective" ;
VAL_ 2172675332 IEB_DriftModeActSta 0 "Default" 1 "Drift Mode ON" 2 "Drift Mode OFF" 3 "Reserved" ;
VAL_ 2172675332 TCS_MtrTrgtRpm_Frnt 0 "0x0x000~0xFFE:Motor RPM Target" 4094 "0x0x000~0xFFE:Motor RPM Target" 4095 "Error Value" ;
VAL_ 1227 DrvIMS_MemoryP1Req 0 "None" 1 "P1" 2 "Not Used" 3 "Error Indicator" ;
VAL_ 1227 DrvIMS_PlyBckP2Req 0 "None" 1 "P2" 2 "Not Used" 3 "Error Indicator" ;
VAL_ 1227 DrvIMS_PlyBckP3Req 0 "None" 1 "P3" 2 "Not Used" 3 "Error Indicator" ;
VAL_ 1227 DrvIMS_PlyBckStpReq 0 "Off" 1 "Stop" 2 "Not Used" 3 "Error Indicator" ;
VAL_ 1227 SmrtIMS_PlyBckReq 0 "None" 1 "0x1~0x97E:Smart IMS DB Number(1~2430)" 2430 "0x1~0x97E:Smart IMS DB Number(1~2430)" 2431 "0x97F~0xFFE:RESERVED" 4094 "0x97F~0xFFE:RESERVED" 4095 "Invalid" ;
VAL_ 1227 DrvIMS_MemoryP2Req 0 "None" 1 "P2" 2 "Not Used" 3 "Error Indicator" ;
VAL_ 1227 PSM_IMSReq 0 "None" 1 "Replay1" 2 "Replay2" 3 "Replay3" 4 "Memory1" 5 "Memory2" 6 "Memory3" 7 "Stop" ;
VAL_ 1227 SmrtIMS_ImgDBVal 0 "none" 1 "Smart IMS Image DB 1~30" 2 "Smart IMS Image DB 1~30" 3 "Smart IMS Image DB 1~30" 4 "Smart IMS Image DB 1~30" 5 "Smart IMS Image DB 1~30" 6 "Smart IMS Image DB 1~30" 7 "Smart IMS Image DB 1~30" 8 "Smart IMS Image DB 1~30" 9 "Smart IMS Image DB 1~30" 10 "Smart IMS Image DB 1~30" 11 "Smart IMS Image DB 1~30" 12 "Smart IMS Image DB 1~30" 13 "Smart IMS Image DB 1~30" 14 "Smart IMS Image DB 1~30" 15 "Smart IMS Image DB 1~30" 16 "Smart IMS Image DB 1~30" 17 "Smart IMS Image DB 1~30" 18 "Smart IMS Image DB 1~30" 19 "Smart IMS Image DB 1~30" 20 "Smart IMS Image DB 1~30" 21 "Smart IMS Image DB 1~30" 22 "Smart IMS Image DB 1~30" 23 "Smart IMS Image DB 1~30" 24 "Smart IMS Image DB 1~30" 25 "Smart IMS Image DB 1~30" 26 "Smart IMS Image DB 1~30" 27 "Smart IMS Image DB 1~30" 28 "Smart IMS Image DB 1~30" 29 "Smart IMS Image DB 1~30" 30 "Smart IMS Image DB 1~30" 31 "Invalid" ;
VAL_ 1227 SmrtIMS_PlyBckStpReq 0 "OFF" 1 "On" 2 "Not Used" 3 "Error Indicator" ;
VAL_ 1227 DrvIMS_MemoryP3Req 0 "None" 1 "P3" 2 "Not Used" 3 "Error Indicator" ;
VAL_ 1227 SmrtIMS_EnterSwSta 0 "off" 1 "on" 2 "reserved" 3 "invalid" ;
VAL_ 1227 DrvIMS_BzrReq 0 "Off" 1 "On" 2 "Not Used" 3 "Error Indicator" ;
VAL_ 1227 DrvIMS_ErrConWmgDis 0 "Off" 1 "On" 2 "Not Used" 3 "Error Indicator" ;
VAL_ 1227 PSM_DrvRlxReturn_Req 0 "Default" 1 "One touch relax" 2 "One touch return" 3 "Stop" 4 "Reserved" 5 "Reserved" 6 "Reserved" 7 "invalid" ;
VAL_ 1227 Drv_AutoRlxWrngDis 0 "Off" 1 "Auto Relax Enable" 2 "Mode-Fail (Vehicle Speed Warning)" 3 "Mode-Fail (Not P Warning)" 4 "Mode-Fail (2nd Seat Belted)" 5 "Mode-Fail (Not Initialized)" 6 "Mode-Fail (2nd Seat Position Warning)" 7 "Invalid" ;
VAL_ 1227 DrvIMS_MemorySetEnaSta 0 "Disable" 1 "Enable" 2 "Not Used" 3 "Error Indicator" ;
VAL_ 1227 DrvIMS_PlyBckP1Req 0 "None" 1 "P1" 2 "Not Used" 3 "Error Indicator" ;
VAL_ 1252 RKE_BtnReq 0 "None" 1 "Lock" 2 "Unlock" 3 "Trunk(Or Tail Gate)" 4 "Panic" 5 "Panic Stop" 6 "Two Step Unlock Warning or India Door Lock/Unlock Sound ON/OFF Set" 7 "Remote Cranking Stop" 8 "Remote Cranking Start" 9 "Forward(RSPA)" 10 "Backward/Parking(RSPA)" 11 "Pause(RSPA)" 12 "Front Trunk" 13 "Reserved" 14 "Charge Door / ImmeChg" 15 "Error Indicator" ;
VAL_ 1252 RKE_PsdBtnReq 0 "Off" 1 "LH On" 2 "RH On" 3 "PanicStop_PSD LH" 4 "PanicStop_PSD RH" 5 "Reseved" 6 "Reseved" 7 "Reserved" 8 "Reserved" 9 "Reserved" 10 "Reserved" 11 "Reserved" 12 "Reserved" 13 "Reserved" 14 "Not Used" 15 "Error Indicator" ;
VAL_ 1252 RKE_WdwUpDnReq 0 "None" 1 "Remote Window Open" 2 "Remote Window Close" 3 "Remote Window Stop" 4 "Reseved" 5 "Reseved" 6 "Not Used" 7 "Error Indicator" ;
VAL_ 1252 RKE_TrnkTlgtBtnReq 0 "Default" 1 "TailgateTrunkOn" 2 "Off" 3 "Reserved" 4 "Reserved" 5 "Reseved" 6 "Reseved" 7 "Error Indiator" ;
VAL_ 1252 RKE_ID 0 "None" 1 "ID1" 2 "ID2" 3 "ID3" 4 "ID4" 5 "Reseved" 6 "Not Used" 7 "Error Indicator" ;
VAL_ 1252 RKE_PwrDrAllOpnClsReq 0 "None" 1 "Open" 2 "Close" 3 "Stop" 4 "Reserved" 5 "Reserved" 6 "Reserved" 7 "Reserved" ;
VAL_ 1237 Audio_VolEncoderSta 0 "Reserved" 1 "0x01~0x7F:Clockwise(Up)" 127 "0x01~0x7F:Clockwise(Up)" 128 "0x80~0xFE:Counterclockwise (Down)" 254 "0x80~0xFE:Counterclockwise (Down)" 255 "Invalid" ;
VAL_ 1237 Cluster_ScrlEncoderSta 0 "Reserved" 1 "0x01~0x7F:Clockwise(Up)" 127 "0x01~0x7F:Clockwise(Up)" 128 "0x80~0xFE:Counterclockwise (Down)" 254 "0x80~0xFE:Counterclockwise (Down)" 255 "Invalid" ;
